VERSION ""

NS_ :

BS_:

BU_: TCM HCM IPMA_ADAS PSCM ABS_ESC TCCM TCM_DSL PCM_HEV PCM ECM_HEVDSL ECM_HEV ECM_Diesel ECM SIMA_DLCS BCMD_IPDB VDM CMR_DSMC SOBDMC_HPCM CHCM GWM _delete AWD_DLCM GENERIC TSTR

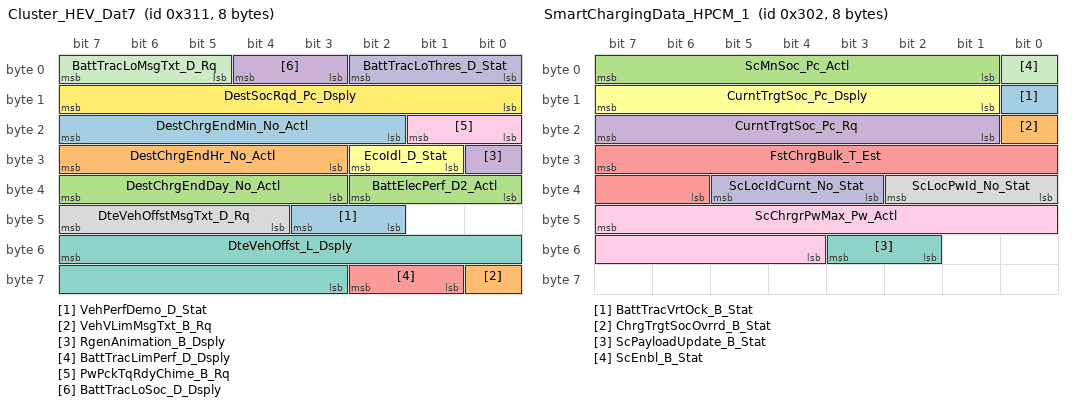
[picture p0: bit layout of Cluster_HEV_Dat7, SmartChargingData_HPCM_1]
BO_ 785 Cluster_HEV_Dat7: 8 SOBDMC_HPCM
 SG_ VehPerfDemo_D_Stat : 43|2@0+ (1,0) [0|3] "SED"  GWM
 SG_ VehVLimMsgTxt_B_Rq : 56|1@0+ (1,0) [0|1] "SED"  GWM
 SG_ BattElecPerf_D2_Actl : 34|3@0+ (1,0) [0|7] "SED"  GWM
 SG_ RgenAnimation_B_Dsply : 24|1@0+ (1,0) [0|1] "SED"  GWM
 SG_ BattTracLimPerf_D_Dsply : 58|2@0+ (1,0) [0|3] "SED"  GWM
 SG_ EcoIdl_D_Stat : 26|2@0+ (1,0) [0|3] "SED"  GWM
 SG_ DteVehOffst_L_Dsply : 55|13@0+ (0.1,-400) [-400|418.9] "kilometer"  GWM
 SG_ DteVehOffstMsgTxt_D_Rq : 47|4@0+ (1,0) [0|15] "SED"  GWM
 SG_ PwPckTqRdyChime_B_Rq : 17|2@0+ (1,0) [0|3] "SED"  GWM
 SG_ BattTracLoThres_D_Stat : 2|3@0+ (1,0) [0|7] "SED"  GWM
 SG_ BattTracLoMsgTxt_D_Rq : 7|3@0+ (1,0) [0|7] "SED"  GWM
 SG_ DestSocRqd_Pc_Dsply : 15|8@0+ (0.5,0) [0|127.5] "percent"  GWM
 SG_ DestChrgEndMin_No_Actl : 23|6@0+ (1,0) [0|63] "Minutes"  GWM
 SG_ DestChrgEndHr_No_Actl : 31|5@0+ (1,0) [0|31] "Hours"  GWM
 SG_ DestChrgEndDay_No_Actl : 39|5@0+ (1,0) [1|31] "days"  GWM
 SG_ BattTracLoSoc_D_Dsply : 4|2@0+ (1,0) [0|3] "SED"  GWM

BO_ 770 SmartChargingData_HPCM_1: 8 SOBDMC_HPCM
 SG_ BattTracVrtOck_B_Stat : 8|1@0+ (1,0) [0|1] "SED"  GWM
 SG_ ChrgTrgtSocOvrrd_B_Stat : 16|1@0+ (1,0) [0|1] "SED"  GWM
 SG_ ScMnSoc_Pc_Actl : 7|7@0+ (1,0) [0|127] "percent"  GWM
 SG_ CurntTrgtSoc_Pc_Rq : 23|7@0+ (1,0) [0|127] "percent"  GWM
 SG_ FstChrgBulk_T_Est : 31|10@0+ (1,0) [0|1023] "minute"  GWM
 SG_ CurntTrgtSoc_Pc_Dsply : 15|7@0+ (1,0) [0|127] "percent"  GWM
 SG_ ScPayloadUpdate_B_Stat : 51|2@0+ (1,0) [0|3] "SED"  GWM
 SG_ ScLocPwId_No_Stat : 34|3@0+ (1,0) [0|7] "unitless"  GWM
 SG_ ScChrgrPwMax_Pw_Actl : 47|12@0+ (50,0) [0|204700] "watts"  GWM
 SG_ ScLocIdCurnt_No_Stat : 37|3@0+ (1,0) [0|7] "unitless"  GWM
 SG_ ScEnbl_B_Stat : 0|1@0+ (1,0) [0|1] "SED"  GWM

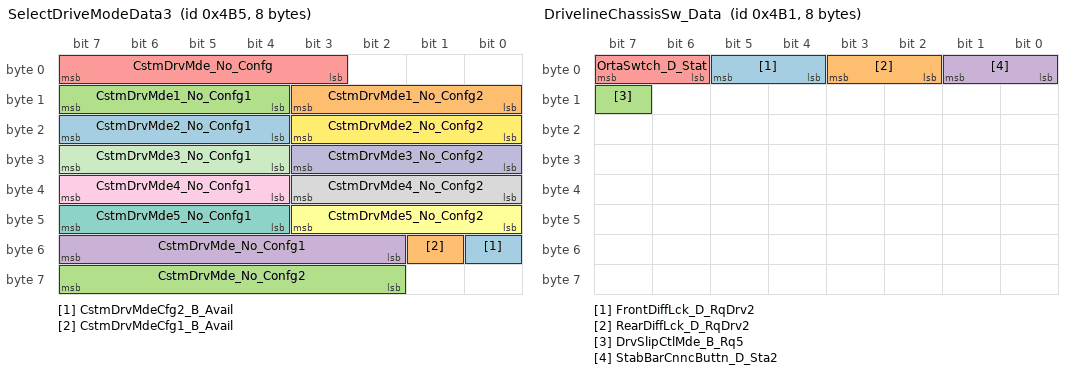
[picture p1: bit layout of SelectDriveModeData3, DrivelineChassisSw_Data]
BO_ 1205 SelectDriveModeData3: 8 ABS_ESC
 SG_ CstmDrvMdeCfg2_B_Avail : 48|1@0+ (1,0) [0|1] "SED"  GWM
 SG_ CstmDrvMdeCfg1_B_Avail : 49|1@0+ (1,0) [0|1] "SED"  GWM
 SG_ CstmDrvMde_No_Confg2 : 63|6@0+ (1,0) [0|63] "unitless"  GWM
 SG_ CstmDrvMde_No_Confg1 : 55|6@0+ (1,0) [0|63] "unitless"  GWM
 SG_ CstmDrvMde_No_Confg : 7|5@0+ (1,0) [0|31] "unitless"  GWM
 SG_ CstmDrvMde5_No_Confg2 : 43|4@0+ (1,0) [0|15] "unitless"  GWM
 SG_ CstmDrvMde5_No_Confg1 : 47|4@0+ (1,0) [0|15] "unitless"  GWM
 SG_ CstmDrvMde4_No_Confg2 : 35|4@0+ (1,0) [0|15] "unitless"  GWM
 SG_ CstmDrvMde4_No_Confg1 : 39|4@0+ (1,0) [0|15] "unitless"  GWM
 SG_ CstmDrvMde3_No_Confg2 : 27|4@0+ (1,0) [0|15] "unitless"  GWM
 SG_ CstmDrvMde3_No_Confg1 : 31|4@0+ (1,0) [0|15] "unitless"  GWM
 SG_ CstmDrvMde2_No_Confg2 : 19|4@0+ (1,0) [0|15] "unitless"  GWM
 SG_ CstmDrvMde2_No_Confg1 : 23|4@0+ (1,0) [0|15] "unitless"  GWM
 SG_ CstmDrvMde1_No_Confg2 : 11|4@0+ (1,0) [0|15] "unitless"  GWM
 SG_ CstmDrvMde1_No_Confg1 : 15|4@0+ (1,0) [0|15] "unitless"  GWM

BO_ 942 ParkAid_Data_3: 8 IPMA_ADAS
 SG_ ApaOffOptnSel_B_Avail : 51|1@0+ (1,0) [0|1] "SED"  GWM
 SG_ PrkBrkElRleas_B_RqApa : 50|1@0+ (1,0) [0|1] "SED"  ABS_ESC,GWM
 SG_ ApaDrvRq2MsgTxt_D_Rq : 55|4@0+ (1,0) [0|15] "SED"  GWM
 SG_ ApaDrvRq1MsgTxt_D_Rq : 42|3@0+ (1,0) [0|7] "SED"  GWM
 SG_ ApaSys_D2_Stat : 35|4@0+ (1,0) [0|15] "SED"  GWM
 SG_ ApaSlotTrgt_D_Stat : 39|4@0+ (1,0) [0|15] "SED"  GWM
 SG_ ApaSlotOption_B_Avail : 43|1@0+ (1,0) [0|1] "SED"  GWM
 SG_ ApaSlotAlrtSet_B_Stat : 44|1@0+ (1,0) [0|1] "SED"  GWM
 SG_ ApaSlotAlrt_B_Rq : 45|1@0+ (1,0) [0|1] "SED"  GWM
 SG_ ApaRmtFeatSel_B_Avail : 46|1@0+ (1,0) [0|1] "SED"  GWM
 SG_ ApaParkOutSel_B_Avail : 47|1@0+ (1,0) [0|1] "SED"  GWM
 SG_ ApaParkInSel_B_Avail : 24|1@0+ (1,0) [0|1] "SED"  GWM
 SG_ ApaMsgTxt_D2_Stat : 28|4@0+ (1,0) [0|15] "SED"  GWM
 SG_ ApaDynmcSlot_B_Stat : 29|1@0+ (1,0) [0|1] "SED"  GWM
 SG_ ApaDisplayMode_D_Stat : 31|2@0+ (1,0) [0|3] "SED"  GWM
 SG_ ApaControlMode_D_Stat : 16|1@0+ (1,0) [0|1] "SED"  GWM
 SG_ PrkAidAcsyRear_D_Stat : 18|2@0+ (1,0) [0|3] "SED"  GWM
 SG_ PrkAidAcsyFront_D_Stat : 20|2@0+ (1,0) [0|3] "SED"  GWM
 SG_ PrkAidRdiusRight_L_Dsply : 15|8@0+ (1,0) [0|255] "unitless"  GWM
 SG_ PrkAidRdiusLeft_L_Dsply : 7|8@0+ (1,0) [0|255] "unitless"  GWM
 SG_ PrkAidDrvDir_D_Stat : 23|3@0+ (1,0) [0|7] "SED"  GWM

BO_ 123 Battery_Traction_2_FD1: 8 BECM
 SG_ BattTrac_U2_Actl : 21|12@0+ (0.5,0) [0|2046.5] "volt"  ECM_Diesel,ECM_HEVDSL,SOBDMC_HPCM,ECM_HEV,PCM_HEV
 SG_ BattTrac_I2_Actl : 7|18@0+ (0.05,-6553.52) [-6553.52|6553.53] "ampere"  ECM_Diesel,ECM_HEVDSL,SOBDMC_HPCM,ECM_HEV,PCM_HEV

BO_ 2612052184 PARSEDPushFcGWM_ECGtoPSCM: 8 GWM
 SG_ PARSEDPushFcGWM_ECGtoPSCM : 7|29@0+ (1,0) [0|536870911] "unitless"  PSCM

BO_ 2612224187 PARSEDPushCMRtoGWM_ECG: 8 CMR_DSMC
 SG_ PARSEDPushCMRtoGWM_ECG : 7|29@0+ (1,0) [0|536870911] "unitless"  GWM

BO_ 1201 DrivelineChassisSw_Data: 8 SIMA_DLCS
 SG_ FrontDiffLck_D_RqDrv2 : 5|2@0+ (1,0) [0|3] "SED"  GWM
 SG_ RearDiffLck_D_RqDrv2 : 3|2@0+ (1,0) [0|3] "SED"  GWM
 SG_ DrvSlipCtlMde_B_Rq5 : 15|1@0+ (1,0) [0|1] "SED"  GWM
 SG_ StabBarCnncButtn_D_Sta2 : 1|2@0+ (1,0) [0|3] "SED"  GWM
 SG_ OrtaSwtch_D_Stat : 7|2@0+ (1,0) [0|3] "SED"  ABS_ESC

BO_ 1912 TesterPhysicalResSIMA_DLCS: 64 SIMA_DLCS
 SG_ TesterPhysicalResSIMA : 7|64@0+ (1,0) [0|1.84467E+019] "unitless"  TSTR

BO_ 1904 TesterPhysicalReqSIMA_DLCS: 64 TSTR
 SG_ TesterPhysicalReqSIMA : 7|64@0+ (1,0) [0|1.84467E+019] "unitless"  SIMA_DLCS

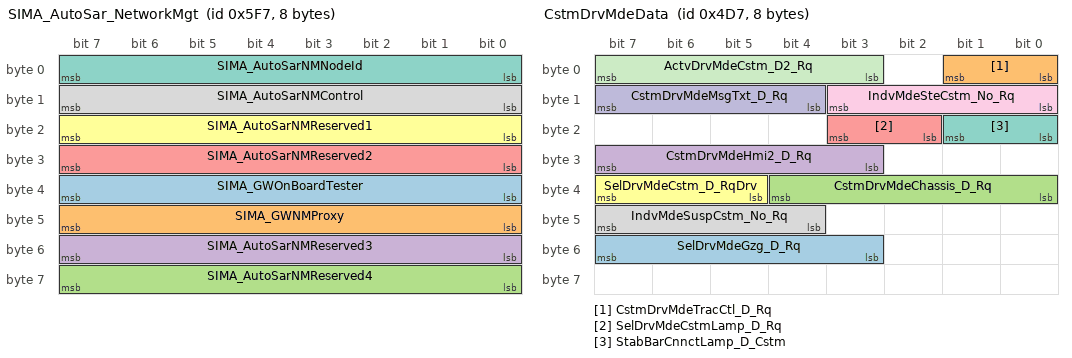
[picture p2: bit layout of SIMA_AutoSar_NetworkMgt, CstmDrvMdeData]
BO_ 1527 SIMA_AutoSar_NetworkMgt: 8 SIMA_DLCS
 SG_ SIMA_GWOnBoardTester : 39|8@0+ (1,0) [0|255] "unitless"  GENERIC
 SG_ SIMA_GWNMProxy : 47|8@0+ (1,0) [0|255] "unitless"  GENERIC
 SG_ SIMA_AutoSarNMReserved4 : 63|8@0+ (1,0) [0|255] "unitless"  GENERIC
 SG_ SIMA_AutoSarNMReserved3 : 55|8@0+ (1,0) [0|255] "unitless"  GENERIC
 SG_ SIMA_AutoSarNMReserved2 : 31|8@0+ (1,0) [0|255] "unitless"  GENERIC
 SG_ SIMA_AutoSarNMReserved1 : 23|8@0+ (1,0) [0|255] "unitless"  GENERIC
 SG_ SIMA_AutoSarNMNodeId : 7|8@0+ (1,0) [0|255] "unitless"  GENERIC
 SG_ SIMA_AutoSarNMControl : 15|8@0+ (1,0) [0|255] "unitless"  GENERIC

BO_ 1239 CstmDrvMdeData: 8 GWM
 SG_ SelDrvMdeGzg_D_Rq : 55|5@0+ (1,0) [0|31] "SED"  ABS_ESC
 SG_ CstmDrvMdeTracCtl_D_Rq : 1|2@0+ (1,0) [0|3] "SED"  ABS_ESC
 SG_ CstmDrvMdeChassis_D_Rq : 36|5@0+ (1,0) [0|31] "SED"  ABS_ESC
 SG_ CstmDrvMdeHmi2_D_Rq : 31|5@0+ (1,0) [0|31] "SED"  ABS_ESC
 SG_ SelDrvMdeCstmLamp_D_Rq : 19|2@0+ (1,0) [0|3] "SED"  GENERIC
 SG_ SelDrvMdeCstm_D_RqDrv : 39|3@0+ (1,0) [0|7] "SED"  ECM_Diesel,ECM_HEV,ECM_HEVDSL,PCM_HEV,ABS_ESC,AWD_DLCM,ECM,PCM,TCCM
 SG_ StabBarCnnctLamp_D_Cstm : 17|2@0+ (1,0) [0|3] "SED"  ABS_ESC
 SG_ IndvMdeSuspCstm_No_Rq : 47|4@0+ (1,0) [0|15] "unitless"  ABS_ESC
 SG_ IndvMdeSteCstm_No_Rq : 11|4@0+ (1,0) [0|15] "unitless"  ABS_ESC
 SG_ CstmDrvMdeMsgTxt_D_Rq : 15|4@0+ (1,0) [0|15] "SED"  GENERIC
 SG_ ActvDrvMdeCstm_D2_Rq : 7|5@0+ (1,0) [0|31] "SED"  ABS_ESC

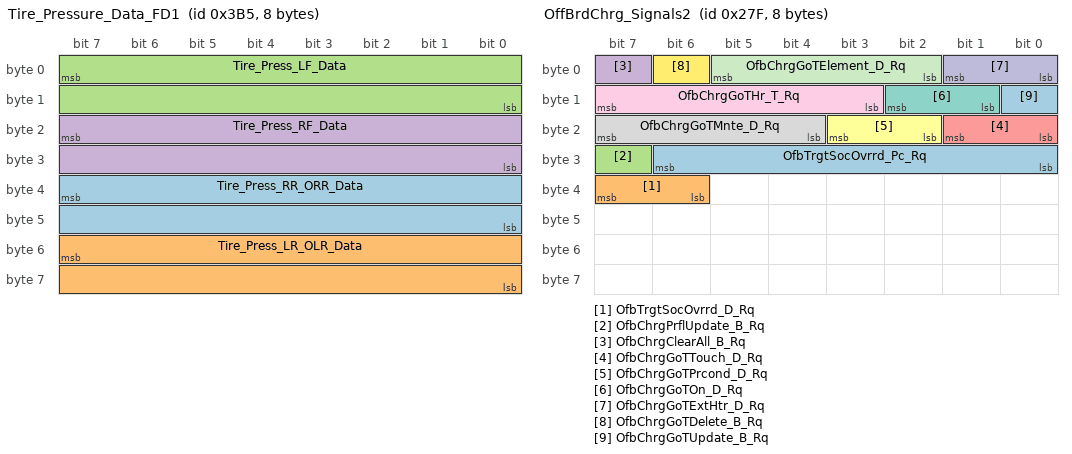
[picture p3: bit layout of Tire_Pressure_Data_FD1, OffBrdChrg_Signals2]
BO_ 949 Tire_Pressure_Data_FD1: 8 BCM
 SG_ Tire_Press_RR_ORR_Data : 39|16@0+ (1,0) [0|65533] "kilopascal"  VDM
 SG_ Tire_Press_LR_OLR_Data : 55|16@0+ (1,0) [0|65533] "kilopascal"  VDM
 SG_ Tire_Press_LF_Data : 7|16@0+ (1,0) [0|65533] "kilopascal"  VDM
 SG_ Tire_Press_RF_Data : 23|16@0+ (1,0) [0|65533] "kilopascal"  VDM

BO_ 2612118744 PARSEDPushFcGWMtoHCM: 8 GWM
 SG_ PARSEDPushFcGWM_ECGtoHCM : 7|29@0+ (1,0) [0|536870911] "unitless"  HCM

BO_ 2612074712 PARSEDPushFcGWMtoSODCMD: 8 GWM
 SG_ PARSEDPushFcGWMtoSODCMD : 7|29@0+ (1,0) [0|536870911] "unitless"  IPMA_ADAS

BO_ 2612024536 PARSEDPushFcGWM_ECGtoCCM: 8 GWM
 SG_ PARSEDPushFcGWM_ECGtoCCM : 7|29@0+ (1,0) [0|536870911] "unitless"  IPMA_ADAS

BO_ 2612036824 PARSEDPushFcGWM_ECGtoIPMA: 8 GWM
 SG_ PARSEDPushFcGWM_ECGtoIPMA : 7|29@0+ (1,0) [0|536870911] "unitless"  IPMA_ADAS

BO_ 2612103384 PARSEDPushFcGWMtoSODL: 8 GWM
 SG_ PARSEDPushFcGWM_ECGtoSODL : 7|29@0+ (1,0) [0|536870911] "unitless"  IPMA_ADAS

BO_ 639 OffBrdChrg_Signals2: 8 GWM
 SG_ OfbTrgtSocOvrrd_Pc_Rq : 30|7@0+ (1,0) [0|127] "percent"  SOBDMC_HPCM
 SG_ OfbTrgtSocOvrrd_D_Rq : 39|2@0+ (1,0) [0|3] "SED"  SOBDMC_HPCM
 SG_ OfbChrgPrflUpdate_B_Rq : 31|1@0+ (1,0) [0|1] "SED"  SOBDMC_HPCM
 SG_ OfbChrgClearAll_B_Rq : 7|1@0+ (1,0) [0|1] "SED"  SOBDMC_HPCM
 SG_ OfbChrgGoTTouch_D_Rq : 17|2@0+ (1,0) [0|3] "SED"  SOBDMC_HPCM
 SG_ OfbChrgGoTPrcond_D_Rq : 19|2@0+ (1,0) [0|3] "SED"  SOBDMC_HPCM
 SG_ OfbChrgGoTOn_D_Rq : 10|2@0+ (1,0) [0|3] "SED"  SOBDMC_HPCM
 SG_ OfbChrgGoTMnte_D_Rq : 23|4@0+ (1,0) [0|15] "minute"  SOBDMC_HPCM
 SG_ OfbChrgGoTHr_T_Rq : 15|5@0+ (1,0) [0|29] "hour"  SOBDMC_HPCM
 SG_ OfbChrgGoTExtHtr_D_Rq : 1|2@0+ (1,0) [0|3] "SED"  SOBDMC_HPCM
 SG_ OfbChrgGoTElement_D_Rq : 5|4@0+ (1,0) [0|15] "Unitless"  SOBDMC_HPCM
 SG_ OfbChrgGoTDelete_B_Rq : 6|1@0+ (1,0) [0|1] "SED"  SOBDMC_HPCM
 SG_ OfbChrgGoTUpdate_B_Rq : 8|1@0+ (1,0) [0|1] "SED"  SOBDMC_HPCM

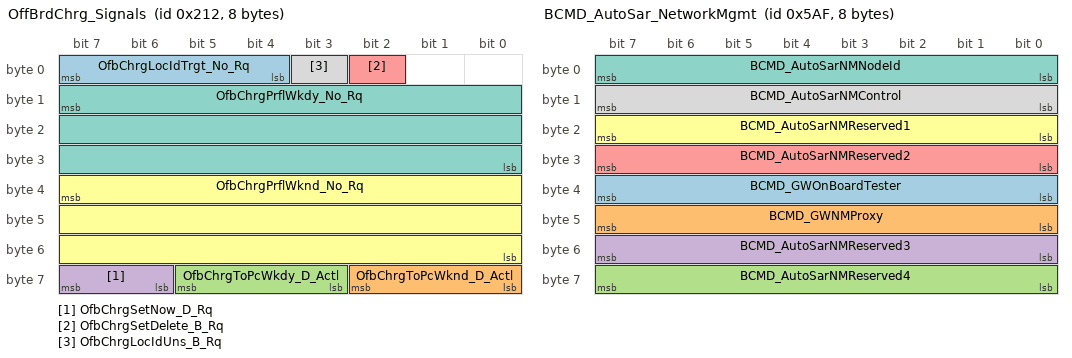
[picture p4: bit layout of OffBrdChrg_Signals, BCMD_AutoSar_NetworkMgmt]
BO_ 530 OffBrdChrg_Signals: 8 GWM
 SG_ OfbChrgLocIdTrgt_No_Rq : 7|4@0+ (1,0) [0|15] "Unitless"  SOBDMC_HPCM
 SG_ OfbChrgToPcWknd_D_Actl : 58|3@0+ (1,0) [0|7] "percent"  SOBDMC_HPCM
 SG_ OfbChrgToPcWkdy_D_Actl : 61|3@0+ (1,0) [0|7] "percent"  SOBDMC_HPCM
 SG_ OfbChrgSetNow_D_Rq : 63|2@0+ (1,0) [0|3] "SED"  SOBDMC_HPCM
 SG_ OfbChrgSetDelete_B_Rq : 2|1@0+ (1,0) [0|1] "SED"  SOBDMC_HPCM
 SG_ OfbChrgPrflWknd_No_Rq : 39|24@0+ (1,0) [0|16777215] "unitless"  SOBDMC_HPCM
 SG_ OfbChrgPrflWkdy_No_Rq : 15|24@0+ (1,0) [0|16777215] "unitless"  SOBDMC_HPCM
 SG_ OfbChrgLocIdUns_B_Rq : 3|1@0+ (1,0) [0|1] "SED"  SOBDMC_HPCM

BO_ 550 ECG_Data4_FD1: 8 GWM
 SG_ PtWakeupActv1_B_Rq : 7|1@0+ (1,0) [0|1] "SED"  SOBDMC_HPCM

BO_ 879 BCMC_Data_FD1: 8 GWM
 SG_ WndwRearHeat_I_Actl : 7|11@0+ (0.1,0) [0|204.6] "ampere"  ECM_Diesel,ECM_HEVDSL
 SG_ WndwRearHeat_D_Stat : 12|3@0+ (1,0) [0|7] "SED"  ECM_Diesel,ECM_HEVDSL

BO_ 1455 BCMD_AutoSar_NetworkMgmt: 8 BCMD_IPDB
 SG_ BCMD_GWOnBoardTester : 39|8@0+ (1,0) [0|255] "unitless"  GENERIC
 SG_ BCMD_GWNMProxy : 47|8@0+ (1,0) [0|255] "unitless"  GENERIC
 SG_ BCMD_AutoSarNMReserved4 : 63|8@0+ (1,0) [0|255] "unitless"  GENERIC
 SG_ BCMD_AutoSarNMReserved3 : 55|8@0+ (1,0) [0|255] "unitless"  GENERIC
 SG_ BCMD_AutoSarNMReserved2 : 31|8@0+ (1,0) [0|255] "unitless"  GENERIC
 SG_ BCMD_AutoSarNMReserved1 : 23|8@0+ (1,0) [0|255] "unitless"  GENERIC
 SG_ BCMD_AutoSarNMNodeId : 7|8@0+ (1,0) [0|255] "unitless"  GENERIC
 SG_ BCMD_AutoSarNMControl : 15|8@0+ (1,0) [0|255] "unitless"  GENERIC

BO_ 1775 TesterPhysicalResBCMD_IPDB: 64 BCMD_IPDB
 SG_ TesterPhysicalResBCMD_IPDB : 7|64@0+ (1,0) [0|1.84467E+019] "unitless"  TSTR

BO_ 1767 TesterPhysicalReqBCMD_IPDB: 64 TSTR
 SG_ TesterPhysicalReqBCMD_IPDB : 7|64@0+ (1,0) [0|1.84467E+019] "unitless"  BCMD_IPDB

BO_ 2612019416 PARSEDPushFcGWM_ECGtoPCM: 8 GWM
 SG_ PARSEDPushFcGWM_ECGtoPCM : 7|29@0+ (1,0) [0|536870911] "unitless"  SOBDMC_HPCM,ECM,ECM_Diesel,ECM_HEV,ECM_HEVDSL,PCM,PCM_HEV

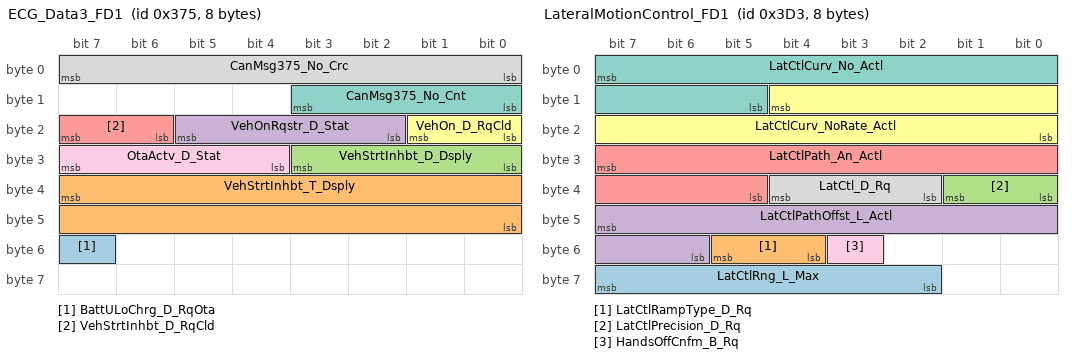
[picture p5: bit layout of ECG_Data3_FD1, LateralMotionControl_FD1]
BO_ 885 ECG_Data3_FD1: 8 GWM
 SG_ BattULoChrg_D_RqOta : 55|1@0+ (1,0) [0|1] "SED"  GENERIC
 SG_ VehStrtInhbt_T_Dsply : 39|16@0+ (1,0) [0|65535] "second"  GENERIC
 SG_ VehStrtInhbt_D_Dsply : 27|4@0+ (1,0) [0|15] "SED"  GENERIC
 SG_ VehOnRqstr_D_Stat : 21|4@0+ (1,0) [0|15] "SED"  GENERIC
 SG_ VehStrtInhbt_D_RqCld : 23|2@0+ (1,0) [0|3] "SED"  GENERIC
 SG_ VehOn_D_RqCld : 17|2@0+ (1,0) [0|3] "SED"  GENERIC
 SG_ CanMsg375_No_Cnt : 11|4@0+ (1,0) [0|15] "unitless"  GENERIC
 SG_ CanMsg375_No_Crc : 7|8@0+ (1,0) [0|255] "unitless"  GENERIC
 SG_ OtaActv_D_Stat : 31|4@0+ (1,0) [0|15] "SED"  AWD_DLCM,TCM,TCM_DSL,SOBDMC_HPCM

BO_ 2612104408 PARSEDPushFcGWMtoSODR: 8 GWM
 SG_ PARSEDPushFcGWM_ECGtoSODR : 7|29@0+ (1,0) [0|536870911] "unitless"  IPMA_ADAS

BO_ 2612020440 PARSEDPushFcGWMtoSOBDMCFD1: 8 GWM
 SG_ PARSEDPushFcGWMtoSOBDMC : 7|29@0+ (1,0) [0|536870911] "unitless"  SOBDMC_HPCM

BO_ 979 LateralMotionControl_FD1: 8 IPMA
 SG_ LatCtlRng_L_Max : 63|6@0+ (2,0) [0|126] "meter"  PSCM
 SG_ LatCtlRampType_D_Rq : 53|2@0+ (1,0) [0|3] "SED" Vector__XXX
 SG_ LatCtlPrecision_D_Rq : 33|2@0+ (1,0) [0|3] "SED" Vector__XXX
 SG_ LatCtlPathOffst_L_Actl : 47|10@0+ (0.01,-5.12) [-5.12|5.11] "meter" Vector__XXX
 SG_ LatCtlPath_An_Actl : 31|11@0+ (0.0005,-0.5) [-0.5|0.5235] "radians" Vector__XXX
 SG_ LatCtlCurv_NoRate_Actl : 12|13@0+ (2.5E-007,-0.001024) [-0.001024|0.00102375] "1/meter"  PSCM
 SG_ LatCtlCurv_No_Actl : 7|11@0+ (2E-005,-0.02) [-0.02|0.02094] "1/meter" Vector__XXX
 SG_ LatCtl_D_Rq : 36|3@0+ (1,0) [0|7] "SED"  PSCM
 SG_ HandsOffCnfm_B_Rq : 51|1@0+ (1,0) [0|1] "SED" Vector__XXX

BO_ 739 HMI_Send_Signals_7_FD1: 8 APIM
 SG_ BptMde_D_RqMnu : 7|3@0+ (1,0) [0|7] "SED"  SOBDMC_HPCM
 SG_ SpeedChngChime_D_Rq : 49|2@0+ (1,0) [0|3] "SED"  IPMA_ADAS
 SG_ BptMnSoc_L_RqMnu : 39|13@0+ (0.1,0) [0|818.9] "kilometer"  SOBDMC_HPCM
 SG_ BptStrtStop_D_RqMnu : 4|2@0+ (1,0) [0|3] "SED"  SOBDMC_HPCM
 SG_ OnbTrgtSocOvrrd_Pc_Rq : 63|7@0+ (1,0) [0|127] "percent"  SOBDMC_HPCM
 SG_ OnbTrgtSocOvrrd_D_Rq : 14|2@0+ (1,0) [0|3] "SED"  SOBDMC_HPCM
 SG_ BabySeatInUse_D_Stat : 31|2@0+ (1,0) [0|3] "SED"  GENERIC
 SG_ VehHornOccAlrt_D_Stat : 27|2@0+ (1,0) [0|3] "SED"  GENERIC
 SG_ SeatOccChime_B_RqCancl : 16|1@0+ (1,0) [0|1] "SED"  GENERIC
 SG_ SeatOccRear_D_Stat : 29|2@0+ (1,0) [0|3] "SED"  GENERIC
 SG_ EngExhMdeHrStrt_D_Rq : 12|5@0+ (1,0) [0|31] "SED"  PCM
 SG_ EngExhMdeHrEnd_D_Rq : 23|5@0+ (1,0) [0|31] "SED"  PCM
 SG_ EngExhMdeHrEnbl_D_Rq : 18|2@0+ (1,0) [0|3] "SED"  PCM
 SG_ VgfSet_D_Stat : 25|2@0+ (1,0) [0|3] "SED"  GENERIC
 SG_ BptDly_T_RqMnu : 55|6@0+ (0.5,0) [0|30.5] "minute"  SOBDMC_HPCM
 SG_ Partial_Amp_Shutdown : 15|1@0+ (1,0) [0|1] "SED"  GENERIC
 SG_ HMI_HMIMode_St : 2|3@0+ (1,0) [0|7] "SED"  ECM,ECM_Diesel,ECM_HEV,ECM_HEVDSL,PCM_HEV,PCM

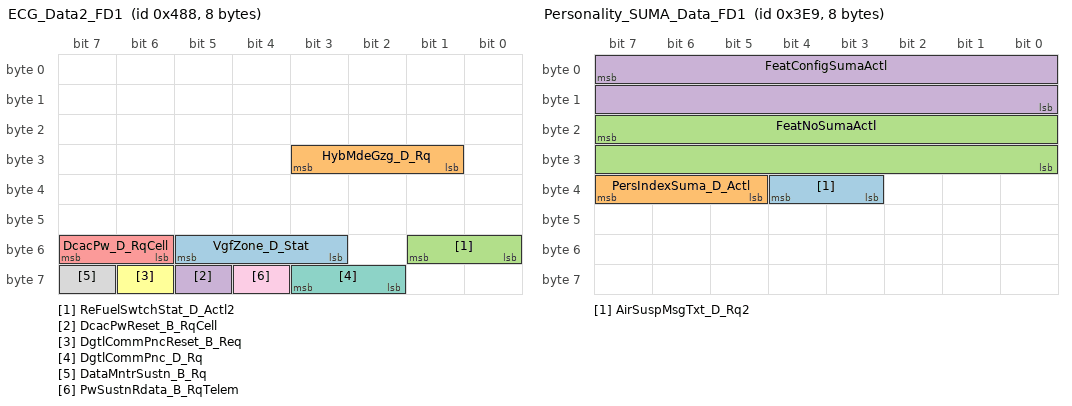
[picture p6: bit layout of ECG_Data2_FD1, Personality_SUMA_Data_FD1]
BO_ 1160 ECG_Data2_FD1: 8 GWM
 SG_ VgfZone_D_Stat : 53|3@0+ (1,0) [0|7] "SED"  ECM,ECM_HEV,PCM,PCM_HEV
 SG_ HybMdeGzg_D_Rq : 27|3@0+ (1,0) [0|7] "SED"  PCM_HEV,SOBDMC_HPCM
 SG_ ReFuelSwtchStat_D_Actl2 : 49|2@0+ (1,0) [0|3] "SED"  ECM_HEV,PCM_HEV
 SG_ DcacPwReset_B_RqCell : 61|1@0+ (1,0) [0|1] "SED"  PCM
 SG_ DcacPw_D_RqCell : 55|2@0+ (1,0) [0|3] "SED"  PCM
 SG_ DgtlCommPncReset_B_Req : 62|1@0+ (1,0) [0|1] "SED"  GENERIC
 SG_ DgtlCommPnc_D_Rq : 59|2@0+ (1,0) [0|3] "SED"  GENERIC
 SG_ DataMntrSustn_B_Rq : 63|1@0+ (1,0) [0|1] "SED"  ECM_HEV,PCM_HEV
 SG_ PwSustnRdata_B_RqTelem : 60|1@0+ (1,0) [0|1] "SED"  SOBDMC_HPCM,ECM_HEV,PCM_HEV

BO_ 1825 TesterPhysicalReqVDM_FD1: 64 TSTR
 SG_ TesterPhysicalReqVDM : 7|64@0+ (1,0) [0|1.84467E+019] "unitless"  VDM

BO_ 1001 Personality_SUMA_Data_FD1: 8 SUMA_RLM
 SG_ AirSuspMsgTxt_D_Rq2 : 36|2@0+ (1,0) [0|3] "SED"  VDM
 SG_ PersIndexSuma_D_Actl : 39|3@0+ (1,0) [0|7] "SED"  GENERIC
 SG_ FeatNoSumaActl : 23|16@0+ (1,0) [0|65535] "Number"  GENERIC
 SG_ FeatConfigSumaActl : 7|16@0+ (1,0) [0|65535] "Undefined"  GENERIC

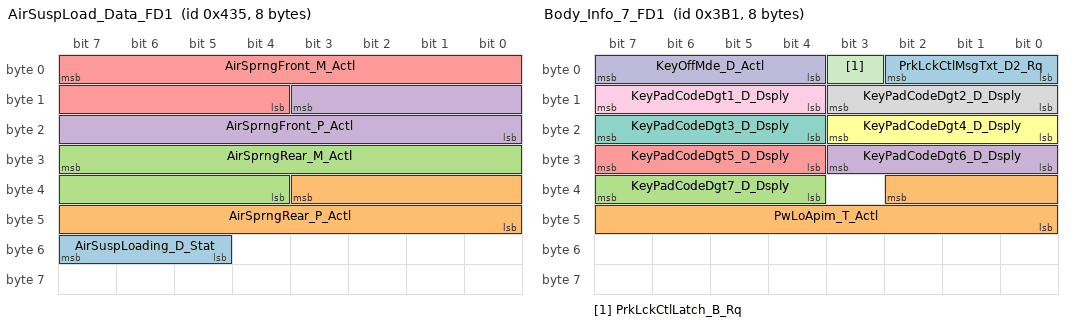
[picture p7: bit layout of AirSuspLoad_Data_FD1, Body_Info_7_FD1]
BO_ 1077 AirSuspLoad_Data_FD1: 8 SUMA_RLM
 SG_ AirSuspLoading_D_Stat : 55|3@0+ (1,0) [0|7] "SED"  VDM
 SG_ AirSprngRear_P_Actl : 35|12@0+ (0.01,-5.92) [-5.92|35.02] "bar"  VDM
 SG_ AirSprngRear_M_Actl : 31|12@0+ (1,0) [0|4094] "kilogram"  VDM
 SG_ AirSprngFront_P_Actl : 11|12@0+ (0.01,-5.92) [-5.92|35.02] "bar"  VDM
 SG_ AirSprngFront_M_Actl : 7|12@0+ (1,0) [0|4094] "kilogram"  VDM

BO_ 945 Body_Info_7_FD1: 8 BCM
 SG_ PrkLckCtlMsgTxt_D2_Rq : 2|3@0+ (1,0) [0|7] "SED"  GENERIC
 SG_ PwLoApim_T_Actl : 34|11@0+ (1,0) [0|2047] "minute"  GENERIC
 SG_ KeyPadCodeDgt7_D_Dsply : 39|4@0+ (1,0) [0|15] "SED"  GENERIC
 SG_ KeyPadCodeDgt6_D_Dsply : 27|4@0+ (1,0) [0|15] "SED"  GENERIC
 SG_ KeyPadCodeDgt5_D_Dsply : 31|4@0+ (1,0) [0|15] "SED"  GENERIC
 SG_ KeyPadCodeDgt4_D_Dsply : 19|4@0+ (1,0) [0|15] "SED"  GENERIC
 SG_ KeyPadCodeDgt3_D_Dsply : 23|4@0+ (1,0) [0|15] "SED"  GENERIC
 SG_ KeyPadCodeDgt2_D_Dsply : 11|4@0+ (1,0) [0|15] "SED"  GENERIC
 SG_ KeyPadCodeDgt1_D_Dsply : 15|4@0+ (1,0) [0|15] "SED"  GENERIC
 SG_ KeyOffMde_D_Actl : 7|4@0+ (1,0) [0|15] "SED"  IPMA_ADAS,VDM
 SG_ PrkLckCtlLatch_B_Rq : 3|1@0+ (1,0) [0|1] "SED"  GENERIC

BO_ 2612073688 PARSEDPushFcGWMtoSODCMC: 8 GWM
 SG_ PARSEDPushFcGWMtoSODCMC : 7|29@0+ (1,0) [0|536870911] "unitless"  IPMA_ADAS

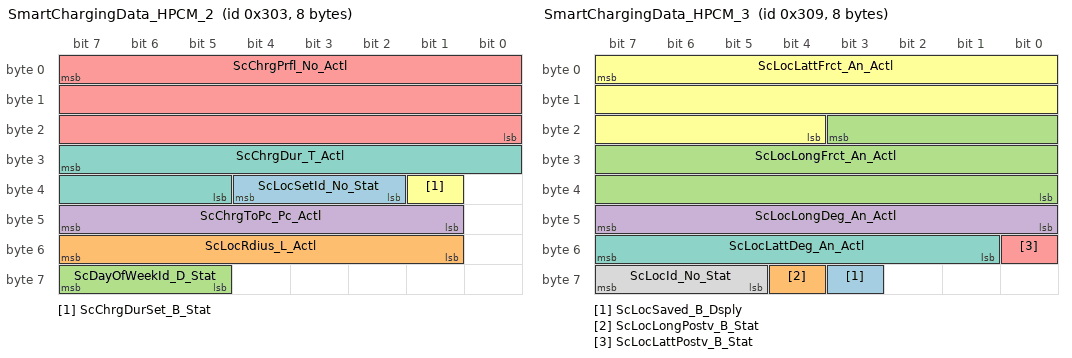
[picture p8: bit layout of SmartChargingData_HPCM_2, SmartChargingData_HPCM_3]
BO_ 771 SmartChargingData_HPCM_2: 8 SOBDMC_HPCM
 SG_ ScLocSetId_No_Stat : 36|3@0+ (1,0) [0|7] "unitless"  GWM
 SG_ ScLocRdius_L_Actl : 55|7@0+ (100,0) [0|12700] "meter"  GWM
 SG_ ScDayOfWeekId_D_Stat : 63|3@0+ (1,0) [0|7] "SED"  GWM
 SG_ ScChrgToPc_Pc_Actl : 47|7@0+ (1,0) [0|127] "percent"  GWM
 SG_ ScChrgPrfl_No_Actl : 7|24@0+ (1,0) [0|16777215] "unitless"  GWM
 SG_ ScChrgDurSet_B_Stat : 33|1@0+ (1,0) [0|1] "SED"  GWM
 SG_ ScChrgDur_T_Actl : 31|11@0+ (1,0) [0|2047] "minute"  GWM

BO_ 777 SmartChargingData_HPCM_3: 8 SOBDMC_HPCM
 SG_ ScLocSaved_B_Dsply : 59|1@0+ (1,0) [0|1] "SED"  GWM
 SG_ ScLocLongPostv_B_Stat : 60|1@0+ (1,0) [0|1] "SED"  GWM
 SG_ ScLocLongFrct_An_Actl : 19|20@0+ (1E-006,0) [0|1.048575] "degrees"  GWM
 SG_ ScLocLongDeg_An_Actl : 47|8@0+ (1,0) [0|255] "degrees"  GWM
 SG_ ScLocLattPostv_B_Stat : 48|1@0+ (1,0) [0|1] "SED"  GWM
 SG_ ScLocLattFrct_An_Actl : 7|20@0+ (1E-006,0) [0|1.048575] "degrees"  GWM
 SG_ ScLocLattDeg_An_Actl : 55|7@0+ (1,0) [0|127] "degrees"  GWM
 SG_ ScLocId_No_Stat : 63|3@0+ (1,0) [0|7] "unitless"  GWM

BO_ 1043 ABS_BrkData: 8 ABS_ESC
 SG_ PrkBrkPerfMsgTxt_D_Rq : 63|5@0+ (1,0) [0|31] "SED"  GWM
 SG_ PrkBrkPerfMde_D_Stat : 34|2@0+ (1,0) [0|3] "SED"  GWM
 SG_ WhlSpareMsgTxt_D_Rq : 41|2@0+ (1,0) [0|3] "SED"  GWM
 SG_ WhlSpareDetct_D_Dsply : 50|3@0+ (1,0) [0|7] "SED"  GWM
 SG_ PrkBrkPerfActv_B_Stat : 32|1@0+ (1,0) [0|1] "SED"  GWM,PCM,TCM
 SG_ SelDrvMdeHmi02_D_Rq : 47|5@0+ (1,0) [0|31] "SED"  GWM
 SG_ SelDrvMdeHmi04_D_Rq : 55|5@0+ (1,0) [0|31] "SED"  GWM
 SG_ IndvMdeSusp_No_Stat : 27|4@0+ (1,0) [0|15] "unitless"  GWM
 SG_ IndvMdeSte_No_Stat : 31|4@0+ (1,0) [0|15] "unitless"  GWM
 SG_ IndvMdeSel_No_Rq : 19|4@0+ (1,0) [0|15] "unitless"  GWM
 SG_ IndvMdeSel_D_Stat : 9|2@0+ (1,0) [0|3] "SED"  GWM
 SG_ IndvMdeMsgTxt_D_Rq : 23|4@0+ (1,0) [0|15] "SED"  GWM
 SG_ IndvMde5_B_Avail : 35|1@0+ (1,0) [0|1] "SED"  GWM
 SG_ IndvMde4_B_Avail : 36|1@0+ (1,0) [0|1] "SED"  GWM
 SG_ IndvMde3_B_Avail : 37|1@0+ (1,0) [0|1] "SED"  GWM
 SG_ IndvMde2_B_Avail : 38|1@0+ (1,0) [0|1] "SED"  GWM
 SG_ IndvMde1_B_Avail : 39|1@0+ (1,0) [0|1] "SED"  GWM
 SG_ TrailOnePdlMde_D_Ind : 15|3@0+ (1,0) [0|7] "SED"  GWM
 SG_ TrailOnePdlMsgTxt_D_Rq : 12|3@0+ (1,0) [0|7] "SED"  GWM
 SG_ OrtaSwtchLamp_B_Rq : 0|1@0+ (1,0) [0|1] "SED"  SIMA_DLCS,GWM
 SG_ OrtaMsgTxt_D_Rq : 4|4@0+ (1,0) [0|15] "SED"  GWM
 SG_ OrtaMde_D_Ind : 7|3@0+ (1,0) [0|7] "SED"  GWM,PCM

BO_ 1833 TesterPhysicalResVDM: 64 VDM
 SG_ TesterPhysicalResVDM : 7|64@0+ (1,0) [0|1.84467E+019] "unitless"  TSTR

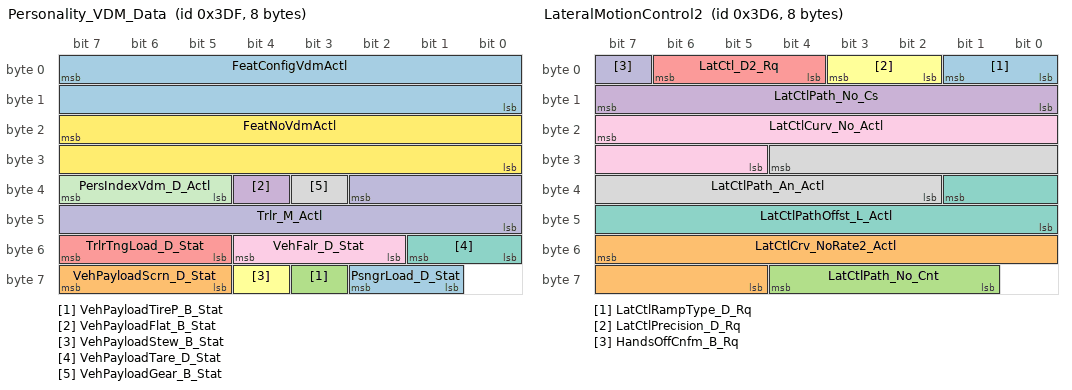
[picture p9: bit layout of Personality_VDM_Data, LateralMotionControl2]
BO_ 991 Personality_VDM_Data: 8 VDM
 SG_ PsngrLoad_D_Stat : 58|2@0+ (1,0) [0|3] "SED"  GWM
 SG_ VehPayloadScrn_D_Stat : 63|3@0+ (1,0) [0|7] "SED"  GWM
 SG_ VehPayloadTireP_B_Stat : 59|1@0+ (1,0) [0|1] "SED"  GWM
 SG_ VehPayloadFlat_B_Stat : 36|1@0+ (1,0) [0|1] "SED"  GWM
 SG_ TrlrTngLoad_D_Stat : 55|3@0+ (1,0) [0|7] "SED"  GWM
 SG_ VehPayloadStew_B_Stat : 60|1@0+ (1,0) [0|1] "SED"  GWM
 SG_ VehPayloadTare_D_Stat : 49|2@0+ (1,0) [0|3] "SED"  GWM
 SG_ VehPayloadGear_B_Stat : 35|1@0+ (1,0) [0|1] "SED"  GWM
 SG_ VehFalr_D_Stat : 52|3@0+ (1,0) [0|7] "SED"  GWM
 SG_ Trlr_M_Actl : 34|11@0+ (10,0) [0|20450] "kilogram"  GWM
 SG_ PersIndexVdm_D_Actl : 39|3@0+ (1,0) [0|7] "SED"  GWM
 SG_ FeatNoVdmActl : 23|16@0+ (1,0) [0|65535] "Number"  GWM
 SG_ FeatConfigVdmActl : 7|16@0+ (1,0) [0|65535] "Undefined"  GWM

BO_ 395 HeadUpDisplayReq_FD1: 8 IPC
 SG_ SelDrvMdeCnfm_D_Stat : 35|2@0+ (1,0) [0|3] "SED"  AWD_DLCM,ABS_ESC
 SG_ HudShifPoint_N_Rq : 29|6@0+ (100,2000) [2000|8300] "rpm"  GENERIC
 SG_ HudMde_D_Rq : 38|3@0+ (1,0) [0|7] "SED"  GENERIC
 SG_ HudLedMde_D_Rq : 31|2@0+ (1,0) [0|3] "SED"  GENERIC
 SG_ HudLedIntns_Pc_Rq : 22|7@0+ (1,0) [0|127] "percent"  GENERIC
 SG_ HudLed9On_B_Rq : 15|1@0+ (1,0) [0|1] "SED"  GENERIC
 SG_ HudLed8On_B_Rq : 0|1@0+ (1,0) [0|1] "SED"  GENERIC
 SG_ HudLed7On_B_Rq : 1|1@0+ (1,0) [0|1] "SED"  GENERIC
 SG_ HudLed6On_B_Rq : 2|1@0+ (1,0) [0|1] "SED"  GENERIC
 SG_ HudLed5On_B_Rq : 3|1@0+ (1,0) [0|1] "SED"  GENERIC
 SG_ HudLed4On_B_Rq : 4|1@0+ (1,0) [0|1] "SED"  GENERIC
 SG_ HudLed3On_B_Rq : 5|1@0+ (1,0) [0|1] "SED"  GENERIC
 SG_ HudLed2On_B_Rq : 6|1@0+ (1,0) [0|1] "SED"  GENERIC
 SG_ HudLed1On_B_Rq : 7|1@0+ (1,0) [0|1] "SED"  GENERIC
 SG_ HudLed18On_B_Rq : 39|1@0+ (1,0) [0|1] "SED"  GENERIC
 SG_ HudLed17On_B_Rq : 23|1@0+ (1,0) [0|1] "SED"  GENERIC
 SG_ HudLed16On_B_Rq : 8|1@0+ (1,0) [0|1] "SED"  GENERIC
 SG_ HudLed15On_B_Rq : 9|1@0+ (1,0) [0|1] "SED"  GENERIC
 SG_ HudLed14On_B_Rq : 10|1@0+ (1,0) [0|1] "SED"  GENERIC
 SG_ HudLed13On_B_Rq : 11|1@0+ (1,0) [0|1] "SED"  GENERIC
 SG_ HudLed12On_B_Rq : 12|1@0+ (1,0) [0|1] "SED"  GENERIC
 SG_ HudLed11On_B_Rq : 13|1@0+ (1,0) [0|1] "SED"  GENERIC
 SG_ HudLed10On_B_Rq : 14|1@0+ (1,0) [0|1] "SED"  GENERIC

BO_ 542 LocationServices_3_FD1: 8 TCU_FB5
 SG_ LocationServices_3 : 7|64@0+ (1,0) [0|1.84467440737096E+019] "unitless"  IPMA_ADAS,ABS_ESC,SOBDMC_HPCM

BO_ 1689 AWD_Rapid_Data_Response_2: 8 AWD_DLCM
 SG_ UUDTAWDResponse2 : 7|64@0+ (1,0) [0|1.84467440737096E+019] "unitless"  TSTR

BO_ 515 PowertrainData_12: 8 SOBDMC_HPCM
 SG_ PtIgnSwtch_D_Stat : 7|2@0+ (1,0) [0|3] "SED"  GWM

BO_ 982 LateralMotionControl2: 8 IPMA_ADAS
 SG_ LatCtlRampType_D_Rq : 1|2@0+ (1,0) [0|3] "SED"  PSCM
 SG_ LatCtlCrv_NoRate2_Actl : 55|11@0+ (1E-006,-0.001024) [-0.001024|0.001023] "meter^2"  PSCM
 SG_ LatCtlPath_No_Cnt : 60|4@0+ (1,0) [0|15] "Unitless"  PSCM
 SG_ LatCtlPath_No_Cs : 15|8@0+ (1,0) [0|255] "Unitless"  PSCM
 SG_ LatCtl_D2_Rq : 6|3@0+ (1,0) [0|7] "SED"  PSCM
 SG_ LatCtlPrecision_D_Rq : 3|2@0+ (1,0) [0|3] "SED"  PSCM
 SG_ LatCtlPathOffst_L_Actl : 33|10@0+ (0.01,-5.12) [-5.12|5.11] "meter"  PSCM
 SG_ LatCtlPath_An_Actl : 28|11@0+ (0.0005,-0.5) [-0.5|0.5235] "radians"  PSCM
 SG_ LatCtlCurv_No_Actl : 23|11@0+ (2E-005,-0.02) [-0.02|0.02094] "1/meter"  PSCM
 SG_ HandsOffCnfm_B_Rq : 7|1@0+ (1,0) [0|1] "SED"  PSCM

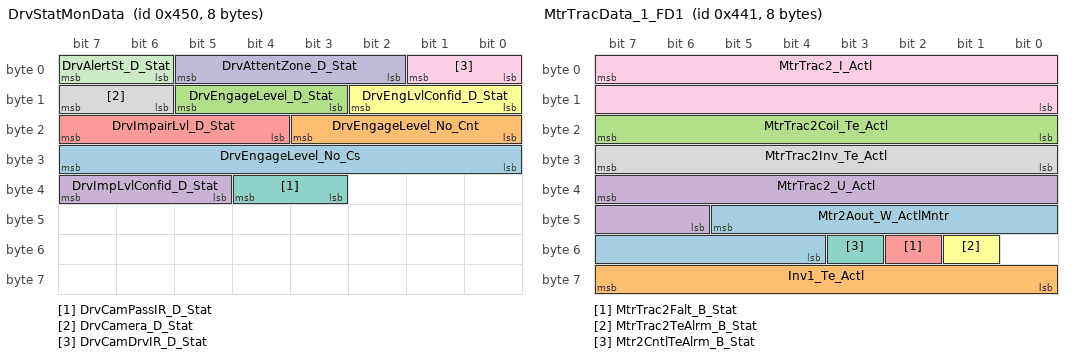
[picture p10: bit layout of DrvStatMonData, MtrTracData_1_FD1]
BO_ 1104 DrvStatMonData: 8 CMR_DSMC
 SG_ DrvEngageLevel_No_Cs : 31|8@0+ (1,0) [0|255] "Unitless"  IPMA_ADAS
 SG_ DrvEngageLevel_No_Cnt : 19|4@0+ (1,0) [0|15] "Unitless"  IPMA_ADAS
 SG_ DrvEngageLevel_D_Stat : 13|3@0+ (1,0) [0|7] "SED"  IPMA_ADAS
 SG_ DrvImpLvlConfid_D_Stat : 39|3@0+ (1,0) [0|7] "SED"  IPMA_ADAS
 SG_ DrvImpairLvl_D_Stat : 23|4@0+ (1,0) [0|15] "SED"  IPMA_ADAS
 SG_ DrvEngLvlConfid_D_Stat : 10|3@0+ (1,0) [0|7] "SED"  IPMA_ADAS
 SG_ DrvCamPassIR_D_Stat : 36|2@0+ (1,0) [0|3] "SED"  IPMA_ADAS
 SG_ DrvCamera_D_Stat : 15|2@0+ (1,0) [0|3] "SED"  IPMA_ADAS
 SG_ DrvCamDrvIR_D_Stat : 1|2@0+ (1,0) [0|3] "SED"  IPMA_ADAS
 SG_ DrvAttentZone_D_Stat : 5|4@0+ (1,0) [0|15] "SED"  IPMA_ADAS
 SG_ DrvAlertSt_D_Stat : 7|2@0+ (1,0) [0|3] "SED"  IPMA_ADAS

BO_ 829 Low_Voltage_Power_Dat2_FD1: 8 DCDC_HEV
 SG_ PwSrcULoMde2_D_Actl : 12|2@0+ (1,0) [0|3] "SED"  SOBDMC_HPCM,ECM_HEV,ECM_HEVDSL,PCM_HEV
 SG_ DcdcUHi3_I_Actl : 7|11@0+ (0.1,0) [0|204.5] "ampere"  ECM_HEV,ECM_HEVDSL,PCM_HEV,SOBDMC_HPCM

BO_ 2611070168 PARSEDPhysGWM_ECGtoHCM: 64 GWM
 SG_ PARSEDPhysGWM_ECGtoHCM : 7|29@0+ (1,0) [0|536870911] "unitless"  HCM,GENERIC

BO_ 2611175537 PARSEDPhysHCMtoGWM_ECG: 64 HCM
 SG_ PARSEDPhysHCMtoGWM_ECG : 7|29@0+ (1,0) [0|536870911] "unitless"  GWM

BO_ 2612224113 PARSEDPushHCMtoGWM_ECG: 8 HCM
 SG_ PARSEDPushHCMtoGWM_ECG : 7|29@0+ (1,0) [0|536870911] "unitless"  GWM

BO_ 2610021592 OTAPhysGWM_ECGtoHCM: 64 GWM
 SG_ OTAPhysGWM_ECGtoHCM : 7|29@0+ (1,0) [0|536870911] "unitless"  HCM,GENERIC

BO_ 2610126961 OTAPhysHCMtoGWM_ECG: 64 HCM
 SG_ OTAPhysHCMtoGWM_ECG : 7|29@0+ (1,0) [0|536870911] "unitless"  GWM

BO_ 2610975960 PARSEDPhysGWM_ECGtoCCM: 64 GWM
 SG_ PARSEDPhysGWM_ECGtoCCM : 7|29@0+ (1,0) [0|536870911] "unitless"  IPMA_ADAS

BO_ 2611175445 PARSEDPhysCCMtoGWM_ECG: 64 IPMA_ADAS
 SG_ PARSEDPhysCCMtoGWM_ECG : 7|29@0+ (1,0) [0|536870911] "unitless"  GWM

BO_ 2612224021 PARSEDPushCCMtoGWM_ECG: 8 IPMA_ADAS
 SG_ PARSEDPushCCMtoGWM_ECG : 7|29@0+ (1,0) [0|536870911] "unitless"  GWM

BO_ 2611025112 PARSEDPhysGWM_ECGtoSODCMC: 64 GWM
 SG_ PARSEDPhysGWM_ECGtoSODCMC : 7|29@0+ (1,0) [0|536870911] "unitless"  IPMA_ADAS

BO_ 2611175493 PARSEDPhysSODCMCtoGWM_ECG: 64 IPMA_ADAS
 SG_ PARSEDPhysSODCMCtoGWM_ECG : 7|29@0+ (1,0) [0|536870911] "unitless"  GWM

BO_ 2612224069 PARSEDPushSODCMCtoGWM: 8 IPMA_ADAS
 SG_ PARSEDPushSODCMCtoGWM : 7|29@0+ (1,0) [0|536870911] "unitless"  GWM

BO_ 1787 TesterPhysicalResSODCMD: 64 IPMA_ADAS
 SG_ TesterPhysicalResSODCMD : 7|64@0+ (1,0) [0|1.84467E+019] "unitless"  TSTR

BO_ 1779 TesterPhysicalReqSODCMD: 64 TSTR
 SG_ TesterPhysicalReqSODCMD : 7|64@0+ (1,0) [0|1.84467E+019] "unitless"  IPMA_ADAS

BO_ 1786 TesterPhysicalResSODCMC: 64 IPMA_ADAS
 SG_ TesterPhysicalResSODCMC : 7|64@0+ (1,0) [0|1.84467E+019] "unitless"  TSTR

BO_ 1089 MtrTracData_1_FD1: 8 SOBDMC_HPCM
 SG_ Mtr2Aout_W_ActlMntr : 45|10@0+ (6.28,-3209) [-3209|3209.16] "radians/sec"  GWM
 SG_ Inv1_Te_Actl : 63|8@0+ (1,-40) [-40|213] "degC"  GWM
 SG_ MtrTrac2Coil_Te_Actl : 23|8@0+ (1,-40) [-40|213] "degC"  GWM
 SG_ MtrTrac2_U_Actl : 39|10@0+ (1,0) [0|1023] "volt"  GWM
 SG_ MtrTrac2Falt_B_Stat : 50|1@0+ (1,0) [0|1] "SED"  GWM
 SG_ MtrTrac2TeAlrm_B_Stat : 49|1@0+ (1,0) [0|1] "SED"  GWM
 SG_ Mtr2CntlTeAlrm_B_Stat : 51|1@0+ (1,0) [0|1] "SED"  GWM
 SG_ MtrTrac2Inv_Te_Actl : 31|8@0+ (1,-40) [-40|213] "degC"  GWM
 SG_ MtrTrac2_I_Actl : 7|16@0+ (0.1,-1000) [-1000|5553.4] "ampere"  GWM

BO_ 1778 TesterPhysicalReqSODCMC: 64 TSTR
 SG_ TesterPhysicalReqSODCMC : 7|64@0+ (1,0) [0|1.84467E+019] "unitless"  IPMA_ADAS

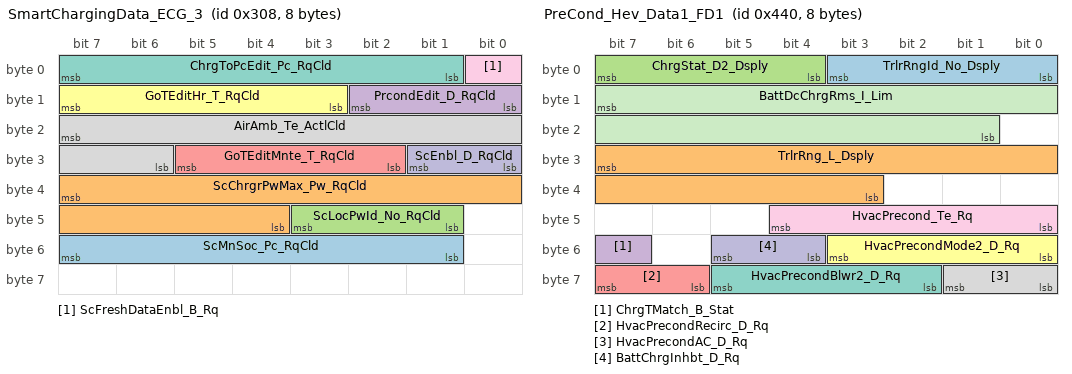
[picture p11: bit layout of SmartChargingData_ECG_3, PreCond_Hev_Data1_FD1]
BO_ 776 SmartChargingData_ECG_3: 8 GWM
 SG_ ScMnSoc_Pc_RqCld : 55|7@0+ (1,0) [0|127] "percent"  SOBDMC_HPCM
 SG_ ScChrgrPwMax_Pw_RqCld : 39|12@0+ (50,0) [0|204700] "watts"  SOBDMC_HPCM
 SG_ ScLocPwId_No_RqCld : 43|3@0+ (1,0) [0|7] "unitless"  SOBDMC_HPCM
 SG_ PrcondEdit_D_RqCld : 10|3@0+ (1,0) [0|7] "SED"  SOBDMC_HPCM
 SG_ GoTEditMnte_T_RqCld : 29|4@0+ (1,0) [0|15] "SED"  SOBDMC_HPCM
 SG_ GoTEditHr_T_RqCld : 15|5@0+ (1,0) [0|29] "SED"  SOBDMC_HPCM
 SG_ ChrgToPcEdit_Pc_RqCld : 7|7@0+ (1,0) [0|125] "percent"  SOBDMC_HPCM
 SG_ AirAmb_Te_ActlCld : 23|10@0+ (0.25,-128) [-128|127.75] "degC"  SOBDMC_HPCM
 SG_ ScFreshDataEnbl_B_Rq : 0|1@0+ (1,0) [0|1] "SED"  SOBDMC_HPCM
 SG_ ScEnbl_D_RqCld : 25|2@0+ (1,0) [0|3] "SED"  SOBDMC_HPCM

BO_ 1088 PreCond_Hev_Data1_FD1: 8 SOBDMC_HPCM
 SG_ TrlrRngId_No_Dsply : 3|4@0+ (1,0) [0|15] "unitless"  GWM
 SG_ TrlrRng_L_Dsply : 31|13@0+ (0.1,0) [0|818.9] "kilometer"  GWM
 SG_ ChrgStat_D2_Dsply : 7|4@0+ (1,0) [0|15] "SED"  GWM,ECM_HEV,PCM_HEV
 SG_ ChrgTMatch_B_Stat : 55|1@0+ (1,0) [0|1] "SED"  GWM,GENERIC
 SG_ HvacPrecondRecirc_D_Rq : 63|2@0+ (1,0) [0|3] "SED"  GWM,GENERIC
 SG_ HvacPrecondMode2_D_Rq : 51|4@0+ (1,0) [0|15] "SED"  GWM,GENERIC
 SG_ HvacPrecondBlwr2_D_Rq : 61|4@0+ (1,0) [0|15] "SED"  GWM,GENERIC
 SG_ HvacPrecondAC_D_Rq : 57|2@0+ (1,0) [0|3] "SED"  GWM,GENERIC
 SG_ HvacPrecond_Te_Rq : 44|5@0+ (0.5,14.5) [14.5|30] "deg C"  GWM,GENERIC
 SG_ BattChrgInhbt_D_Rq : 53|2@0+ (1,0) [0|3] "SED"  GWM,GENERIC
 SG_ BattDcChrgRms_I_Lim : 15|15@0+ (0.05,0) [0|1638.25] "ampere"  GWM

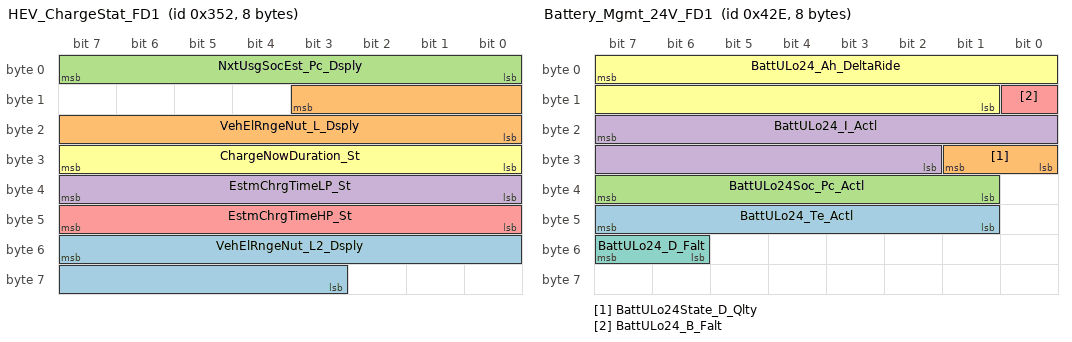
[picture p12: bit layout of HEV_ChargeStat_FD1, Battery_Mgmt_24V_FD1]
BO_ 850 HEV_ChargeStat_FD1: 8 SOBDMC_HPCM
 SG_ VehElRngeNut_L2_Dsply : 55|13@0+ (0.1,0) [0|818.9] "km"  GWM
 SG_ VehElRngeNut_L_Dsply : 11|12@0+ (0.1,0) [0|409.3] "km"  GWM
 SG_ NxtUsgSocEst_Pc_Dsply : 7|8@0+ (0.5,0) [0|126.5] "unitless"  GWM
 SG_ EstmChrgTimeLP_St : 39|8@0+ (0.1,0) [0|25.4] "hour"  GWM
 SG_ EstmChrgTimeHP_St : 47|8@0+ (0.1,0) [0|25.4] "hour"  GWM
 SG_ ChargeNowDuration_St : 31|8@0+ (0.1,0) [0|25.4] "hour"  GWM

BO_ 1070 Battery_Mgmt_24V_FD1: 8 BCM
 SG_ BattULo24_Te_Actl : 47|7@0+ (1,-40) [-40|86] "degC"  ECM_Diesel,ECM_HEVDSL,PCM
 SG_ BattULo24State_D_Qlty : 25|2@0+ (1,0) [0|3] "SED"  ECM_Diesel,ECM_HEVDSL,PCM
 SG_ BattULo24Soc_Pc_Actl : 39|7@0+ (1,0) [0|127] "percent"  PCM,ECM_Diesel,ECM_HEVDSL
 SG_ BattULo24_I_Actl : 23|14@0+ (0.0625,-512) [-512|511.875] "ampere"  ECM_Diesel,ECM_HEVDSL,PCM
 SG_ BattULo24_B_Falt : 8|1@0+ (1,0) [0|1] "SED"  ECM_Diesel,ECM_HEVDSL,PCM
 SG_ BattULo24_Ah_DeltaRide : 7|15@0+ (0.0078125,-100) [-100|155.9921875] "amperehour"  ECM_Diesel,ECM_HEVDSL,PCM
 SG_ BattULo24_D_Falt : 55|2@0+ (1,0) [0|3] "SED"  ECM_Diesel,ECM_HEVDSL,PCM

BO_ 1153 All_Terrain_Data_FD1: 8 ATCM
 SG_ TerrStat_D_RqDsply : 7|4@0+ (1,0) [0|15] "SED"  GENERIC
 SG_ TerrMde_D_RqDrv : 3|3@0+ (1,0) [0|7] "SED"  AWD_DLCM

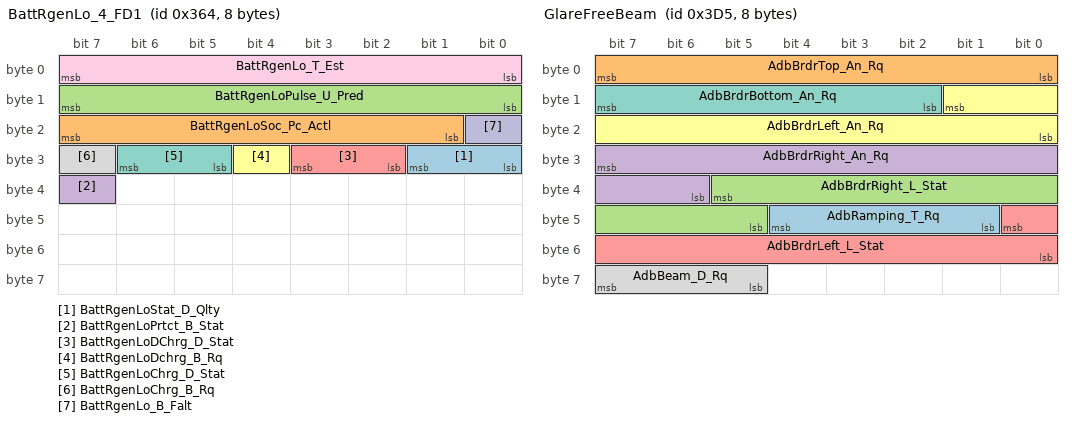
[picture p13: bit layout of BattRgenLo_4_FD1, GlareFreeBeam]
BO_ 868 BattRgenLo_4_FD1: 8 DCDC_LISB
 SG_ BattRgenLoStat_D_Qlty : 25|2@0+ (1,0) [0|3] "SED"  PCM_HEV,PCM
 SG_ BattRgenLoSoc_Pc_Actl : 23|7@0+ (1,0) [0|100] "percent"  PCM_HEV,PCM
 SG_ BattRgenLoPulse_U_Pred : 15|8@0+ (0.0625,0) [0|15.9375] "volt"  PCM_HEV,PCM
 SG_ BattRgenLoPrtct_B_Stat : 39|1@0+ (1,0) [0|1] "SED"  PCM_HEV,PCM
 SG_ BattRgenLoDChrg_D_Stat : 27|2@0+ (1,0) [0|3] "SED"  PCM_HEV,PCM
 SG_ BattRgenLoDchrg_B_Rq : 28|1@0+ (1,0) [0|1] "SED"  PCM_HEV,PCM
 SG_ BattRgenLoChrg_D_Stat : 30|2@0+ (1,0) [0|3] "SED"  PCM_HEV,PCM
 SG_ BattRgenLoChrg_B_Rq : 31|1@0+ (1,0) [0|1] "SED"  PCM_HEV,PCM
 SG_ BattRgenLo_T_Est : 7|8@0+ (8,0) [0|2040] "second"  PCM_HEV,PCM
 SG_ BattRgenLo_B_Falt : 16|1@0+ (1,0) [0|1] "SED"  PCM_HEV,PCM

BO_ 1795 TesterPhysicalReqAWD: 64 TSTR
 SG_ TesterPhysicalReqAWD : 7|64@0+ (1,0) [0|1.84467E+019] "unitless"  AWD_DLCM

BO_ 1803 TesterPhysicalResAWD: 64 AWD_DLCM
 SG_ TesterPhysicalResAWD : 7|64@0+ (1,0) [0|1.84467E+019] "unitless"  TSTR

BO_ 2611026136 PARSEDPhysGWM_ECGtoSODCMD: 64 GWM
 SG_ PARSEDPhysGWM_ECGtoSODCMD : 7|29@0+ (1,0) [0|536870911] "unitless"  IPMA_ADAS

BO_ 2611175494 PARSEDPhysSODCMDtoGWM_ECG: 64 IPMA_ADAS
 SG_ PARSEDPhysSODCMDtoGWM_ECG : 7|29@0+ (1,0) [0|536870911] "unitless"  GWM

BO_ 2612224070 PARSEDPushSODCMDtoGWM: 8 IPMA_ADAS
 SG_ PARSEDPushSODCMDtoGWM : 7|29@0+ (1,0) [0|536870911] "unitless"  GWM

BO_ 2611054808 PARSEDPhysGWM_ECGtoSODL: 64 GWM
 SG_ PARSEDPhysGWM_ECGtoSODL : 7|29@0+ (1,0) [0|536870911] "unitless"  IPMA_ADAS

BO_ 2611175523 PARSEDPhysSODRtoGWM_ECG: 64 IPMA_ADAS
 SG_ PARSEDPhysSODRtoGWM_ECG : 7|29@0+ (1,0) [0|536870911] "unitless"  GWM

BO_ 2612224099 PARSEDPushSODRtoGWM_ECG: 8 IPMA_ADAS
 SG_ PARSEDPushSODRtoGWM_ECG : 7|29@0+ (1,0) [0|536870911] "unitless"  GWM

BO_ 2611055832 PARSEDPhysGWM_ECGtoSODR: 64 GWM
 SG_ PARSEDPhysGWM_ECGtoSODR : 7|29@0+ (1,0) [0|536870911] "unitless"  IPMA_ADAS

BO_ 2611175522 PARSEDPhysSODLtoGWM_ECG: 64 IPMA_ADAS
 SG_ PARSEDPhysSODLtoGWM_ECG : 7|29@0+ (1,0) [0|536870911] "unitless"  GWM

BO_ 2612224098 PARSEDPushSODLtoGWM_ECG: 8 IPMA_ADAS
 SG_ PARSEDPushSODLtoGWM_ECG : 7|29@0+ (1,0) [0|536870911] "unitless"  GWM

BO_ 2609927384 OTAPhysGWM_ECGtoCCM: 64 GWM
 SG_ OTAPhysGWM_ECGtoCCM : 7|29@0+ (1,0) [0|536870911] "unitless"  IPMA_ADAS

BO_ 2610126869 OTAPhysCCMtoGWM_ECG: 64 IPMA_ADAS
 SG_ OTAPhysCCMtoGWM_ECG : 7|29@0+ (1,0) [0|536870911] "unitless"  GWM

BO_ 2609976536 OTAPhysGWM_ECGtoSODCMC: 64 GWM
 SG_ OTAPhysGWM_ECGtoSODCMC : 7|29@0+ (1,0) [0|536870911] "unitless"  IPMA_ADAS

BO_ 2610126917 OTAPhysSODCMCtoGWM_ECG: 64 IPMA_ADAS
 SG_ OTAPhysSODCMCtoGWM_ECG : 7|29@0+ (1,0) [0|536870911] "unitless"  GWM

BO_ 2609977560 OTAPhysGWM_ECGtoSODCMD: 64 GWM
 SG_ OTAPhysGWM_ECGtoSODCMD : 7|29@0+ (1,0) [0|536870911] "unitless"  IPMA_ADAS

BO_ 2610126918 OTAPhysSODCMDtoGWM_ECG: 64 IPMA_ADAS
 SG_ OTAPhysSODCMDtoGWM_ECG : 7|29@0+ (1,0) [0|536870911] "unitless"  GWM

BO_ 2610007256 OTAPhysGWM_ECGtoSODR: 64 GWM
 SG_ OTAPhysGWM_ECGtoSODR : 7|29@0+ (1,0) [0|536870911] "unitless"  IPMA_ADAS

BO_ 2610126947 OTAPhysSODRtoGWM_ECG: 64 IPMA_ADAS
 SG_ OTAPhysSODRtoGWM_ECG : 7|29@0+ (1,0) [0|536870911] "unitless"  GWM

BO_ 2612224017 PARSEDPushSOBDMCtoGWM_FD1: 8 SOBDMC_HPCM
 SG_ PARSEDPushSOBDMCtoGWM_ECG : 7|29@0+ (1,0) [0|536870911] "unitless"  GWM

BO_ 981 GlareFreeBeam: 8 IPMA_ADAS
 SG_ AdbRamping_T_Rq : 44|4@0+ (200,0) [0|3000] "millisecond"  HCM,GWM
 SG_ AdbBrdrTop_An_Rq : 7|8@0+ (0.04,-9.54) [-9.54|0.58] "degrees"  HCM,GWM
 SG_ AdbBrdrRight_L_Stat : 37|9@0+ (2,0) [0|1018] "meter"  HCM,GWM
 SG_ AdbBrdrRight_An_Rq : 31|10@0+ (0.04,-20.4) [-20.4|20.44] "degrees"  HCM,GWM
 SG_ AdbBrdrLeft_L_Stat : 40|9@0+ (2,0) [0|1018] "meter"  HCM,GWM
 SG_ AdbBrdrLeft_An_Rq : 9|10@0+ (0.04,-20.4) [-20.4|20.44] "degrees"  HCM,GWM
 SG_ AdbBrdrBottom_An_Rq : 15|6@0+ (0.04,-1.86) [-1.86|0.58] "degrees"  HCM,GWM
 SG_ AdbBeam_D_Rq : 63|3@0+ (1,0) [0|7] "SED"  HCM,GWM

BO_ 810 ECG_Data_FD1: 8 GWM
 SG_ VehHorn_B_RqOccAlrt : 58|1@0+ (1,0) [0|1] "SED"  GENERIC
 SG_ RmtViewMde_B_Rq : 59|1@0+ (1,0) [0|1] "SED"  GENERIC
 SG_ DteCldAcceptData_B_Rq : 60|1@0+ (1,0) [0|1] "SED"  SOBDMC_HPCM
 SG_ DteCldCnclRoute_B_Rq : 61|1@0+ (1,0) [0|1] "SED"  SOBDMC_HPCM
 SG_ NtfyDrvTrgtDist_L_Rq : 23|12@0+ (0.1,0) [0|409.5] "Km"  SOBDMC_HPCM
 SG_ NtfyDrvSocLvl1_Pc_Rq : 39|7@0+ (1,0) [0|127] "%"  SOBDMC_HPCM
 SG_ PtRmtRprt_D_Stat : 27|4@0+ (1,0) [0|15] "SED"  SOBDMC_HPCM
 SG_ ChrgrPncEnbl_D_Rq : 9|2@0+ (1,0) [0|3] "SED"  GENERIC
 SG_ OneTEditActv_B_RqCld : 32|1@0+ (1,0) [0|1] "SED"  SOBDMC_HPCM
 SG_ GoTElementEdit_No_RqCld : 43|4@0+ (1,0) [0|15] "unitless"  SOBDMC_HPCM
 SG_ OBCCSerial_D_Rq : 45|2@0+ (1,0) [0|3] "SED"  GENERIC
 SG_ ExtLghtDsply_B_StatArb : 7|1@0+ (1,0) [0|1] "SED"  GENERIC
 SG_ ExtLghtRight_D_RqOta : 12|3@0+ (1,0) [0|7] "SED"  GENERIC
 SG_ ExtLghtRear_D_RqOta : 15|3@0+ (1,0) [0|7] "SED"  GENERIC
 SG_ ExtLghtLeft_D_RqOta : 3|3@0+ (1,0) [0|7] "SED"  GENERIC
 SG_ ExtLghtFront_D_RqOta : 6|3@0+ (1,0) [0|7] "SED"  GENERIC
 SG_ TlghtTest_D_RqArb : 47|2@0+ (1,0) [0|3] "SED"  GENERIC
 SG_ ChrgrPncSustn_B_Rq : 0|1@0+ (1,0) [0|1] "SED"  GENERIC
 SG_ GoTAirAmb_Te_ActlCld : 55|10@0+ (0.25,-128) [-128|127.75] "degC"  SOBDMC_HPCM

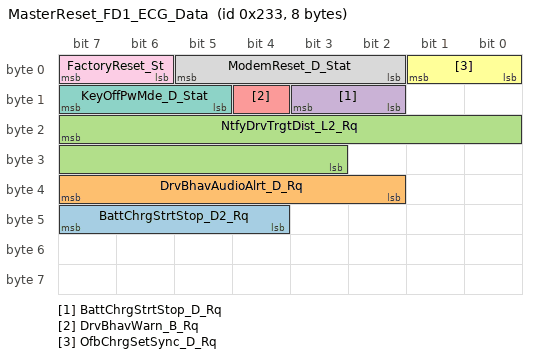
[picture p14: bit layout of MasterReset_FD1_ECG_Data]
BO_ 563 MasterReset_FD1_ECG_Data: 8 GWM
 SG_ BattChrgStrtStop_D2_Rq : 47|4@0+ (1,0) [0|15] "SED"  SOBDMC_HPCM
 SG_ DrvBhavAudioAlrt_D_Rq : 39|6@0+ (1,0) [0|63] "SED"  GENERIC
 SG_ NtfyDrvTrgtDist_L2_Rq : 23|13@0+ (0.1,0) [0|818.9] "Km"  SOBDMC_HPCM
 SG_ BattChrgStrtStop_D_Rq : 11|2@0+ (1,0) [0|3] "SED"  SOBDMC_HPCM
 SG_ DrvBhavWarn_B_Rq : 12|1@0+ (1,0) [0|1] "SED"  GENERIC
 SG_ OfbChrgSetSync_D_Rq : 1|2@0+ (1,0) [0|3] "SED"  SOBDMC_HPCM
 SG_ KeyOffPwMde_D_Stat : 15|3@0+ (1,0) [0|7] "SED"  GENERIC
 SG_ ModemReset_D_Stat : 5|4@0+ (1,0) [0|15] "SED"  GENERIC
 SG_ FactoryReset_St : 7|2@0+ (1,0) [0|3] "SED"  GENERIC

BO_ 2609923288 OTAPhysGWM_ECGtoSOBDMC_FD1: 64 GWM
 SG_ OTAPhysGWM_ECGtoSOBDMC : 7|29@0+ (1,0) [0|536870911] "unitless"  SOBDMC_HPCM

BO_TX_BU_ 785 : PCM_HEV,SOBDMC_HPCM;
BO_TX_BU_ 991 : GWM,VDM;
BO_TX_BU_ 515 : PCM_HEV,PCM,ECM_HEVDSL,ECM_HEV,ECM_Diesel,ECM,SOBDMC_HPCM;
CM_ SG_ 942 PrkAidRdiusRight_L_Dsply "MSGDCR 679, set all signals to OnChange";
CM_ SG_ 942 PrkAidRdiusLeft_L_Dsply "MSGDCR 679, set all signals to OnChange";
CM_ SG_ 942 PrkAidDrvDir_D_Stat "MSGDCR 679, set all signals to OnChange";
CM_ BO_ 949 "For 2010MY and beyond, use for SCT (non-CGEA) and CGEA modules";
CM_ SG_ 550 PtWakeupActv1_B_Rq "ECG Application signal";
CM_ BO_ 885 "NOTE: START BITS 8-11 MUST BE OPEN SPEC REQUIREMENT";
CM_ BO_ 739 "FCDIM Tx";
CM_ SG_ 739 Partial_Amp_Shutdown "Method Partial_Amp_Shutdown";
CM_ SG_ 739 HMI_HMIMode_St "Object ACU System Master.HMIMode
OR
Object NAV System Master.HMIMode

Refer Method HMIAudioMode in the SPSS";
CM_ BO_ 1160 "some signals from HS4 0x22A TCU_EM in CGEA1.3";
CM_ SG_ 542 LocationServices_3 "Tx by HS3 APIM";
CM_ SG_ 982 LatCtlPath_No_Cnt "Signal not transmitted on gas variants.";
CM_ SG_ 982 LatCtlPath_No_Cs "Signal not transmitted on gas variants.";
CM_ SG_ 1104 DrvEngageLevel_No_Cs "Signal not transmitted on gas variants.";
CM_ SG_ 1104 DrvEngageLevel_No_Cnt "Signal not transmitted on gas variants.";
CM_ SG_ 1088 HvacPrecondMode2_D_Rq "Signal not transmitted on vehicles that do not have the Fuel operated heater feature.";
CM_ SG_ 1088 HvacPrecondBlwr2_D_Rq "Signal not transmitted on vehicles that do not have the Fuel operated heater feature.";
CM_ SG_ 810 NtfyDrvTrgtDist_L_Rq "Object.SetTripRangeAlert_Rq
This signal is meant to provide the customer settings for the target distance remote notification";
CM_ SG_ 810 NtfyDrvSocLvl1_Pc_Rq "Object.SetCustomerLevelAlert_Rq
This signal is meant to provide the customer settings for the SOC remote notification.";
CM_ SG_ 810 PtRmtRprt_D_Stat "Object.RemoteDataReport_St
";
CM_ SG_ 563 NtfyDrvTrgtDist_L2_Rq "Object.SetTripRangeAlert_Rq
This signal is meant to provide the customer settings for the target distance remote notification";
BA_DEF_ BO_  "VFrameFormat" ENUM  "StandardCAN","ExtendedCAN","reserved","reserved","reserved","reserved","reserved","reserved","reserved","reserved","reserved","reserved","reserved","reserved","StandardCAN_FD","ExtendedCAN_FD";
BA_DEF_ SG_  "GenSigSendType" ENUM  "Cyclic","OnWrite","vector_leerstring","OnChange","vector_leerstring","IfActive","vector_leerstring","NoSigSendType";
BA_DEF_ SG_  "GenSigInactiveValue" INT 0 100000;
BA_DEF_ SG_  "WakeupSignal" ENUM  "No","Yes";
BA_DEF_ SG_  "UsedOnPgmDBC" ENUM  "No","Yes";
BA_DEF_ SG_  "GenSigStartValueInteger" INT 0 1000000000;
BA_DEF_ SG_  "ContentDependant" ENUM  "No","Yes";
BA_DEF_ SG_  "MetaData" ENUM  "No","Yes";
BA_DEF_ SG_  "GenSigStartValue" HEX 0 268435455;
BA_DEF_ SG_  "U_CX727_MY2021_Rx" ENUM  "No","Yes";
BA_DEF_ SG_  "U_P702_MY2021_Rx" ENUM  "No","Yes";
BA_DEF_ SG_  "U_T6_MCA_MY2020_Rx" ENUM  "No","Yes";
BA_DEF_ SG_  "ECGUsedRxSignal" ENUM  "No","Yes";
BA_DEF_ SG_  "U_CD542_MY2021_Rx" ENUM  "No","Yes";
BA_DEF_ SG_  "U_U55X_MY2022_Rx" ENUM  "No","Yes";
BA_DEF_ SG_  "U_CD764_MY2022_Rx" ENUM  "No","Yes";
BA_DEF_ SG_  "U_CDX706_MY2023_Rx" ENUM  "No","Yes";
BA_DEF_ SG_  "U_CX727_MY2021_Tx" ENUM  "No","Yes";
BA_DEF_ SG_  "U_P702_MY2021_Tx" ENUM  "No","Yes";
BA_DEF_ SG_  "U_T6_MCA_MY2020_Tx" ENUM  "No","Yes";
BA_DEF_ SG_  "ECGUsedTxSignal" ENUM  "No","Yes";
BA_DEF_ SG_  "U_CD542_MY2021_Tx" ENUM  "No","Yes";
BA_DEF_ SG_  "U_U55X_MY2022_Tx" ENUM  "No","Yes";
BA_DEF_ SG_  "U_CD764_MY2022_Tx" ENUM  "No","Yes";
BA_DEF_ SG_  "U_CDX706_MY2023_Tx" ENUM  "No","Yes";
BA_DEF_ BO_  "GenMsgILSupport" ENUM  "No","Yes";
BA_DEF_ BO_  "DiagResponse" ENUM  "No","Yes";
BA_DEF_ BO_  "DiagRequest" ENUM  "No","Yes";
BA_DEF_ BO_  "TpTxIndex" INT 0 536870911;
BA_DEF_ BO_  "DiagState" ENUM  "No","Yes";
BA_DEF_ BO_  "TpApplType" STRING ;
BA_DEF_ BO_  "NmAsrMessage" ENUM  "No","Yes";
BA_DEF_ BO_  "ProgBWConditional" STRING ;
BA_DEF_ BO_  "SCP_AuthInfoTxLength" INT 0 512;
BA_DEF_ BO_  "SCP_FreshnessValueTxLength" INT 0 512;
BA_DEF_ BO_  "SCP_FreshnessValueLength" INT 0 512;
BA_DEF_ BO_  "OvtpPushApplication" ENUM  "FALSE","TRUE";
BA_DEF_ BO_  "GenMsgSendType" ENUM  "FixedPeriodic","Event","EnabledPeriodic","NotUsed","NotUsed","EventPeriodic","NotUsed","NotUsed","NoMsgSendType";
BA_DEF_ BO_  "GenMsgCycleTime" INT 0 100000;
BA_DEF_ BO_  "GenMsgDelayTime" INT 0 1000;
BA_DEF_ BO_  "GenMsgNrOfRepetition" INT 0 100;
BA_DEF_ BO_  "GenMsgStartDelayTime" INT 0 10000;
BA_DEF_ BO_  "EventRateOfChange" INT 10 10000;
BA_DEF_ BO_  "FrameGatewayId" HEX 0 1407;
BA_DEF_ BO_  "NetworkInitialization" ENUM  "No","Yes";
BA_DEF_ BO_  "FrameGatewayNetwork" STRING ;
BA_DEF_ BO_  "FrameRouting" STRING ;
BA_DEF_DEF_  "VFrameFormat" "ExtendedCAN_FD";
BA_DEF_DEF_  "GenSigSendType" "NoSigSendType";
BA_DEF_DEF_  "GenSigInactiveValue" 0;
BA_DEF_DEF_  "WakeupSignal" "No";
BA_DEF_DEF_  "UsedOnPgmDBC" "Yes";
BA_DEF_DEF_  "GenSigStartValueInteger" 0;
BA_DEF_DEF_  "ContentDependant" "No";
BA_DEF_DEF_  "MetaData" "No";
BA_DEF_DEF_  "GenSigStartValue" 0;
BA_DEF_DEF_  "U_CX727_MY2021_Rx" "No";
BA_DEF_DEF_  "U_P702_MY2021_Rx" "No";
BA_DEF_DEF_  "U_T6_MCA_MY2020_Rx" "No";
BA_DEF_DEF_  "ECGUsedRxSignal" "No";
BA_DEF_DEF_  "U_CD542_MY2021_Rx" "No";
BA_DEF_DEF_  "U_U55X_MY2022_Rx" "No";
BA_DEF_DEF_  "U_CD764_MY2022_Rx" "No";
BA_DEF_DEF_  "U_CDX706_MY2023_Rx" "No";
BA_DEF_DEF_  "U_CX727_MY2021_Tx" "No";
BA_DEF_DEF_  "U_P702_MY2021_Tx" "No";
BA_DEF_DEF_  "U_T6_MCA_MY2020_Tx" "No";
BA_DEF_DEF_  "ECGUsedTxSignal" "No";
BA_DEF_DEF_  "U_CD542_MY2021_Tx" "No";
BA_DEF_DEF_  "U_U55X_MY2022_Tx" "No";
BA_DEF_DEF_  "U_CD764_MY2022_Tx" "No";
BA_DEF_DEF_  "U_CDX706_MY2023_Tx" "No";
BA_DEF_DEF_  "GenMsgILSupport" "Yes";
BA_DEF_DEF_  "DiagResponse" "No";
BA_DEF_DEF_  "DiagRequest" "No";
BA_DEF_DEF_  "TpTxIndex" 0;
BA_DEF_DEF_  "DiagState" "No";
BA_DEF_DEF_  "TpApplType" "";
BA_DEF_DEF_  "NmAsrMessage" "No";
BA_DEF_DEF_  "ProgBWConditional" "NONE";
BA_DEF_DEF_  "SCP_AuthInfoTxLength" 53;
BA_DEF_DEF_  "SCP_FreshnessValueTxLength" 11;
BA_DEF_DEF_  "SCP_FreshnessValueLength" 64;
BA_DEF_DEF_  "OvtpPushApplication" "FALSE";
BA_DEF_DEF_  "GenMsgSendType" "NoMsgSendType";
BA_DEF_DEF_  "GenMsgCycleTime" 0;
BA_DEF_DEF_  "GenMsgDelayTime" 20;
BA_DEF_DEF_  "GenMsgNrOfRepetition" 1;
BA_DEF_DEF_  "GenMsgStartDelayTime" 0;
BA_DEF_DEF_  "EventRateOfChange" 10000;
BA_DEF_DEF_  "FrameGatewayId" 0;
BA_DEF_DEF_  "NetworkInitialization" "Yes";
BA_DEF_DEF_  "FrameGatewayNetwork" "NONE";
BA_DEF_DEF_  "FrameRouting" "";
BA_ "GenMsgSendType" BO_ 123 0;
BA_ "GenMsgCycleTime" BO_ 123 10;
BA_ "GenMsgSendType" BO_ 949 0;
BA_ "GenMsgCycleTime" BO_ 949 500;
BA_ "GenMsgSendType" BO_ 979 0;
BA_ "GenMsgCycleTime" BO_ 979 50;
BA_ "GenMsgSendType" BO_ 739 5;
BA_ "GenMsgCycleTime" BO_ 739 1000;
BA_ "GenMsgSendType" BO_ 1001 5;
BA_ "GenMsgCycleTime" BO_ 1001 1000;
BA_ "GenMsgSendType" BO_ 1077 0;
BA_ "GenMsgCycleTime" BO_ 1077 1000;
BA_ "GenMsgSendType" BO_ 945 5;
BA_ "GenMsgCycleTime" BO_ 945 1000;
BA_ "GenMsgSendType" BO_ 395 5;
BA_ "GenMsgCycleTime" BO_ 395 1000;
BA_ "GenMsgSendType" BO_ 542 1;
BA_ "GenMsgSendType" BO_ 829 0;
BA_ "GenMsgCycleTime" BO_ 829 100;
BA_ "GenMsgSendType" BO_ 1070 0;
BA_ "GenMsgCycleTime" BO_ 1070 40;
BA_ "GenMsgSendType" BO_ 1153 0;
BA_ "GenMsgCycleTime" BO_ 1153 100;
BA_ "GenMsgSendType" BO_ 868 5;
BA_ "GenMsgCycleTime" BO_ 868 1000;
BA_ "GenMsgSendType" BO_ 785 5;
BA_ "GenMsgCycleTime" BO_ 785 1000;
BA_ "VFrameFormat" BO_ 785 14;
BA_ "GenMsgSendType" BO_ 770 5;
BA_ "GenMsgCycleTime" BO_ 770 1000;
BA_ "VFrameFormat" BO_ 770 14;
BA_ "GenMsgSendType" BO_ 1205 5;
BA_ "GenMsgCycleTime" BO_ 1205 100000;
BA_ "GenMsgStartDelayTime" BO_ 1205 1130;
BA_ "VFrameFormat" BO_ 1205 14;
BA_ "GenMsgSendType" BO_ 942 5;
BA_ "GenMsgCycleTime" BO_ 942 200;
BA_ "VFrameFormat" BO_ 942 14;
BA_ "FrameGatewayId" BO_ 123 123;
BA_ "FrameGatewayNetwork" BO_ 123 "HS1_CAN";
BA_ "FrameRouting" BO_ 123 "HS1_CAN,0x7B;";
BA_ "VFrameFormat" BO_ 123 14;
BA_ "TpTxIndex" BO_ 2612052184 464568536;
BA_ "OvtpPushApplication" BO_ 2612052184 1;
BA_ "GenMsgSendType" BO_ 2612052184 1;
BA_ "GenMsgDelayTime" BO_ 2612052184 0;
BA_ "NetworkInitialization" BO_ 2612052184 0;
BA_ "TpTxIndex" BO_ 2612224187 464710872;
BA_ "OvtpPushApplication" BO_ 2612224187 1;
BA_ "GenMsgSendType" BO_ 2612224187 1;
BA_ "GenMsgDelayTime" BO_ 2612224187 0;
BA_ "NetworkInitialization" BO_ 2612224187 0;
BA_ "GenMsgSendType" BO_ 1201 5;
BA_ "GenMsgCycleTime" BO_ 1201 1000;
BA_ "VFrameFormat" BO_ 1201 14;
BA_ "GenMsgILSupport" BO_ 1912 0;
BA_ "DiagResponse" BO_ 1912 1;
BA_ "GenMsgSendType" BO_ 1912 1;
BA_ "GenMsgDelayTime" BO_ 1912 0;
BA_ "NetworkInitialization" BO_ 1912 0;
BA_ "VFrameFormat" BO_ 1912 14;
BA_ "GenMsgILSupport" BO_ 1904 0;
BA_ "DiagRequest" BO_ 1904 1;
BA_ "GenMsgSendType" BO_ 1904 1;
BA_ "GenMsgDelayTime" BO_ 1904 0;
BA_ "NetworkInitialization" BO_ 1904 0;
BA_ "VFrameFormat" BO_ 1904 14;
BA_ "GenMsgILSupport" BO_ 1527 0;
BA_ "NmAsrMessage" BO_ 1527 1;
BA_ "GenMsgSendType" BO_ 1527 0;
BA_ "GenMsgCycleTime" BO_ 1527 1000;
BA_ "NetworkInitialization" BO_ 1527 0;
BA_ "VFrameFormat" BO_ 1527 14;
BA_ "GenMsgSendType" BO_ 1239 5;
BA_ "GenMsgCycleTime" BO_ 1239 1000;
BA_ "VFrameFormat" BO_ 1239 14;
BA_ "FrameGatewayId" BO_ 949 949;
BA_ "FrameGatewayNetwork" BO_ 949 "HS1_CAN";
BA_ "FrameRouting" BO_ 949 "HS1_CAN,0x3B5;";
BA_ "VFrameFormat" BO_ 949 14;
BA_ "TpTxIndex" BO_ 2612118744 464635096;
BA_ "OvtpPushApplication" BO_ 2612118744 1;
BA_ "GenMsgSendType" BO_ 2612118744 1;
BA_ "GenMsgDelayTime" BO_ 2612118744 0;
BA_ "NetworkInitialization" BO_ 2612118744 0;
BA_ "TpTxIndex" BO_ 2612074712 464591064;
BA_ "OvtpPushApplication" BO_ 2612074712 1;
BA_ "GenMsgSendType" BO_ 2612074712 1;
BA_ "GenMsgDelayTime" BO_ 2612074712 0;
BA_ "NetworkInitialization" BO_ 2612074712 0;
BA_ "TpTxIndex" BO_ 2612024536 464540888;
BA_ "OvtpPushApplication" BO_ 2612024536 1;
BA_ "GenMsgSendType" BO_ 2612024536 1;
BA_ "GenMsgDelayTime" BO_ 2612024536 0;
BA_ "NetworkInitialization" BO_ 2612024536 0;
BA_ "TpTxIndex" BO_ 2612036824 464553176;
BA_ "OvtpPushApplication" BO_ 2612036824 1;
BA_ "GenMsgSendType" BO_ 2612036824 1;
BA_ "GenMsgDelayTime" BO_ 2612036824 0;
BA_ "NetworkInitialization" BO_ 2612036824 0;
BA_ "TpTxIndex" BO_ 2612103384 464619736;
BA_ "OvtpPushApplication" BO_ 2612103384 1;
BA_ "GenMsgSendType" BO_ 2612103384 1;
BA_ "GenMsgDelayTime" BO_ 2612103384 0;
BA_ "NetworkInitialization" BO_ 2612103384 0;
BA_ "GenMsgSendType" BO_ 639 5;
BA_ "GenMsgCycleTime" BO_ 639 1000;
BA_ "VFrameFormat" BO_ 639 14;
BA_ "GenMsgSendType" BO_ 530 5;
BA_ "GenMsgCycleTime" BO_ 530 1000;
BA_ "VFrameFormat" BO_ 530 14;
BA_ "GenMsgSendType" BO_ 550 5;
BA_ "GenMsgCycleTime" BO_ 550 1000;
BA_ "VFrameFormat" BO_ 550 14;
BA_ "FrameGatewayId" BO_ 879 879;
BA_ "FrameGatewayNetwork" BO_ 879 "HS1_CAN";
BA_ "FrameRouting" BO_ 879 "HS1_CAN,0x36F;";
BA_ "VFrameFormat" BO_ 879 14;
BA_ "GenMsgILSupport" BO_ 1455 0;
BA_ "NmAsrMessage" BO_ 1455 1;
BA_ "GenMsgSendType" BO_ 1455 0;
BA_ "GenMsgCycleTime" BO_ 1455 1000;
BA_ "NetworkInitialization" BO_ 1455 0;
BA_ "VFrameFormat" BO_ 1455 14;
BA_ "GenMsgILSupport" BO_ 1775 0;
BA_ "DiagResponse" BO_ 1775 1;
BA_ "GenMsgSendType" BO_ 1775 1;
BA_ "GenMsgDelayTime" BO_ 1775 0;
BA_ "NetworkInitialization" BO_ 1775 0;
BA_ "VFrameFormat" BO_ 1775 14;
BA_ "GenMsgILSupport" BO_ 1767 0;
BA_ "DiagRequest" BO_ 1767 1;
BA_ "GenMsgSendType" BO_ 1767 1;
BA_ "GenMsgDelayTime" BO_ 1767 0;
BA_ "NetworkInitialization" BO_ 1767 0;
BA_ "VFrameFormat" BO_ 1767 14;
BA_ "TpTxIndex" BO_ 2612019416 464535768;
BA_ "OvtpPushApplication" BO_ 2612019416 1;
BA_ "GenMsgSendType" BO_ 2612019416 1;
BA_ "GenMsgDelayTime" BO_ 2612019416 0;
BA_ "NetworkInitialization" BO_ 2612019416 0;
BA_ "GenMsgSendType" BO_ 885 0;
BA_ "GenMsgCycleTime" BO_ 885 200;
BA_ "VFrameFormat" BO_ 885 14;
BA_ "TpTxIndex" BO_ 2612104408 464620760;
BA_ "OvtpPushApplication" BO_ 2612104408 1;
BA_ "GenMsgSendType" BO_ 2612104408 1;
BA_ "GenMsgDelayTime" BO_ 2612104408 0;
BA_ "NetworkInitialization" BO_ 2612104408 0;
BA_ "TpTxIndex" BO_ 2612020440 464536792;
BA_ "OvtpPushApplication" BO_ 2612020440 1;
BA_ "GenMsgSendType" BO_ 2612020440 1;
BA_ "GenMsgDelayTime" BO_ 2612020440 0;
BA_ "NetworkInitialization" BO_ 2612020440 0;
BA_ "FrameGatewayId" BO_ 979 979;
BA_ "FrameGatewayNetwork" BO_ 979 "HS2_CAN";
BA_ "FrameRouting" BO_ 979 "HS2_CAN,0x3D3;";
BA_ "VFrameFormat" BO_ 979 14;
BA_ "FrameGatewayId" BO_ 739 739;
BA_ "FrameGatewayNetwork" BO_ 739 "HS3_CAN";
BA_ "FrameRouting" BO_ 739 "HS3_CAN,0x2E3;";
BA_ "VFrameFormat" BO_ 739 14;
BA_ "GenMsgSendType" BO_ 1160 5;
BA_ "GenMsgCycleTime" BO_ 1160 1000;
BA_ "VFrameFormat" BO_ 1160 14;
BA_ "GenMsgILSupport" BO_ 1825 0;
BA_ "DiagRequest" BO_ 1825 1;
BA_ "GenMsgSendType" BO_ 1825 1;
BA_ "GenMsgDelayTime" BO_ 1825 0;
BA_ "NetworkInitialization" BO_ 1825 0;
BA_ "VFrameFormat" BO_ 1825 14;
BA_ "FrameGatewayId" BO_ 1001 1001;
BA_ "FrameGatewayNetwork" BO_ 1001 "HS2_CAN";
BA_ "FrameRouting" BO_ 1001 "HS2_CAN,0x3E9;";
BA_ "VFrameFormat" BO_ 1001 14;
BA_ "FrameGatewayId" BO_ 1077 1077;
BA_ "FrameGatewayNetwork" BO_ 1077 "HS2_CAN";
BA_ "FrameRouting" BO_ 1077 "HS2_CAN,0x435;";
BA_ "VFrameFormat" BO_ 1077 14;
BA_ "FrameGatewayId" BO_ 945 945;
BA_ "FrameGatewayNetwork" BO_ 945 "HS1_CAN";
BA_ "FrameRouting" BO_ 945 "HS1_CAN,0x3B1;";
BA_ "VFrameFormat" BO_ 945 14;
BA_ "TpTxIndex" BO_ 2612073688 464590040;
BA_ "OvtpPushApplication" BO_ 2612073688 1;
BA_ "GenMsgSendType" BO_ 2612073688 1;
BA_ "GenMsgDelayTime" BO_ 2612073688 0;
BA_ "NetworkInitialization" BO_ 2612073688 0;
BA_ "GenMsgSendType" BO_ 771 5;
BA_ "GenMsgCycleTime" BO_ 771 1000;
BA_ "VFrameFormat" BO_ 771 14;
BA_ "GenMsgSendType" BO_ 777 5;
BA_ "GenMsgCycleTime" BO_ 777 1000;
BA_ "VFrameFormat" BO_ 777 14;
BA_ "GenMsgSendType" BO_ 1043 5;
BA_ "GenMsgCycleTime" BO_ 1043 1000;
BA_ "VFrameFormat" BO_ 1043 14;
BA_ "GenMsgILSupport" BO_ 1833 0;
BA_ "DiagResponse" BO_ 1833 1;
BA_ "GenMsgSendType" BO_ 1833 1;
BA_ "GenMsgDelayTime" BO_ 1833 0;
BA_ "NetworkInitialization" BO_ 1833 0;
BA_ "VFrameFormat" BO_ 1833 14;
BA_ "GenMsgSendType" BO_ 991 5;
BA_ "GenMsgCycleTime" BO_ 991 1000;
BA_ "VFrameFormat" BO_ 991 14;
BA_ "FrameGatewayId" BO_ 395 395;
BA_ "FrameGatewayNetwork" BO_ 395 "HS3_CAN";
BA_ "FrameRouting" BO_ 395 "HS3_CAN,0x18B;";
BA_ "VFrameFormat" BO_ 395 14;
BA_ "FrameGatewayId" BO_ 542 542;
BA_ "FrameGatewayNetwork" BO_ 542 "HS4_CAN";
BA_ "FrameRouting" BO_ 542 "HS4_CAN,0x21E;";
BA_ "VFrameFormat" BO_ 542 14;
BA_ "GenMsgILSupport" BO_ 1689 0;
BA_ "TpApplType" BO_ 1689 "DiagUUDTResponse";
BA_ "GenMsgSendType" BO_ 1689 1;
BA_ "NetworkInitialization" BO_ 1689 0;
BA_ "VFrameFormat" BO_ 1689 14;
BA_ "GenMsgSendType" BO_ 515 5;
BA_ "GenMsgCycleTime" BO_ 515 100;
BA_ "VFrameFormat" BO_ 515 14;
BA_ "GenMsgSendType" BO_ 982 0;
BA_ "GenMsgCycleTime" BO_ 982 50;
BA_ "FrameRouting" BO_ 982 "FD1_CAN,0x3D6;HS2_CAN,0x3D6";
BA_ "VFrameFormat" BO_ 982 14;
BA_ "GenMsgSendType" BO_ 1104 0;
BA_ "GenMsgCycleTime" BO_ 1104 200;
BA_ "VFrameFormat" BO_ 1104 14;
BA_ "FrameGatewayId" BO_ 829 829;
BA_ "FrameGatewayNetwork" BO_ 829 "HS1_CAN";
BA_ "FrameRouting" BO_ 829 "HS1_CAN,0x33D;";
BA_ "VFrameFormat" BO_ 829 14;
BA_ "TpTxIndex" BO_ 2611070168 463586520;
BA_ "GenMsgSendType" BO_ 2611070168 1;
BA_ "GenMsgDelayTime" BO_ 2611070168 0;
BA_ "NetworkInitialization" BO_ 2611070168 0;
BA_ "TpTxIndex" BO_ 2611175537 463586520;
BA_ "GenMsgSendType" BO_ 2611175537 1;
BA_ "GenMsgDelayTime" BO_ 2611175537 0;
BA_ "NetworkInitialization" BO_ 2611175537 0;
BA_ "TpTxIndex" BO_ 2612224113 464635096;
BA_ "OvtpPushApplication" BO_ 2612224113 1;
BA_ "GenMsgSendType" BO_ 2612224113 1;
BA_ "GenMsgDelayTime" BO_ 2612224113 0;
BA_ "NetworkInitialization" BO_ 2612224113 0;
BA_ "TpTxIndex" BO_ 2610021592 462537944;
BA_ "GenMsgSendType" BO_ 2610021592 1;
BA_ "GenMsgDelayTime" BO_ 2610021592 0;
BA_ "NetworkInitialization" BO_ 2610021592 0;
BA_ "TpTxIndex" BO_ 2610126961 462537944;
BA_ "GenMsgSendType" BO_ 2610126961 1;
BA_ "GenMsgDelayTime" BO_ 2610126961 0;
BA_ "NetworkInitialization" BO_ 2610126961 0;
BA_ "TpTxIndex" BO_ 2610975960 463492312;
BA_ "GenMsgSendType" BO_ 2610975960 1;
BA_ "GenMsgDelayTime" BO_ 2610975960 0;
BA_ "NetworkInitialization" BO_ 2610975960 0;
BA_ "TpTxIndex" BO_ 2611175445 463492312;
BA_ "GenMsgSendType" BO_ 2611175445 1;
BA_ "GenMsgDelayTime" BO_ 2611175445 0;
BA_ "NetworkInitialization" BO_ 2611175445 0;
BA_ "TpTxIndex" BO_ 2612224021 464540888;
BA_ "OvtpPushApplication" BO_ 2612224021 1;
BA_ "GenMsgSendType" BO_ 2612224021 1;
BA_ "GenMsgDelayTime" BO_ 2612224021 0;
BA_ "NetworkInitialization" BO_ 2612224021 0;
BA_ "TpTxIndex" BO_ 2611025112 463541464;
BA_ "GenMsgSendType" BO_ 2611025112 1;
BA_ "GenMsgDelayTime" BO_ 2611025112 0;
BA_ "NetworkInitialization" BO_ 2611025112 0;
BA_ "TpTxIndex" BO_ 2611175493 463541464;
BA_ "GenMsgSendType" BO_ 2611175493 1;
BA_ "GenMsgDelayTime" BO_ 2611175493 0;
BA_ "NetworkInitialization" BO_ 2611175493 0;
BA_ "TpTxIndex" BO_ 2612224069 464590040;
BA_ "OvtpPushApplication" BO_ 2612224069 1;
BA_ "GenMsgSendType" BO_ 2612224069 1;
BA_ "GenMsgDelayTime" BO_ 2612224069 0;
BA_ "NetworkInitialization" BO_ 2612224069 0;
BA_ "GenMsgILSupport" BO_ 1787 0;
BA_ "DiagResponse" BO_ 1787 1;
BA_ "GenMsgSendType" BO_ 1787 1;
BA_ "GenMsgDelayTime" BO_ 1787 0;
BA_ "NetworkInitialization" BO_ 1787 0;
BA_ "VFrameFormat" BO_ 1787 14;
BA_ "GenMsgILSupport" BO_ 1779 0;
BA_ "DiagRequest" BO_ 1779 1;
BA_ "GenMsgSendType" BO_ 1779 1;
BA_ "GenMsgDelayTime" BO_ 1779 0;
BA_ "NetworkInitialization" BO_ 1779 0;
BA_ "VFrameFormat" BO_ 1779 14;
BA_ "GenMsgILSupport" BO_ 1786 0;
BA_ "DiagResponse" BO_ 1786 1;
BA_ "GenMsgSendType" BO_ 1786 1;
BA_ "GenMsgDelayTime" BO_ 1786 0;
BA_ "NetworkInitialization" BO_ 1786 0;
BA_ "VFrameFormat" BO_ 1786 14;
BA_ "GenMsgSendType" BO_ 1089 0;
BA_ "GenMsgCycleTime" BO_ 1089 1000;
BA_ "VFrameFormat" BO_ 1089 14;
BA_ "GenMsgILSupport" BO_ 1778 0;
BA_ "DiagRequest" BO_ 1778 1;
BA_ "GenMsgSendType" BO_ 1778 1;
BA_ "GenMsgDelayTime" BO_ 1778 0;
BA_ "NetworkInitialization" BO_ 1778 0;
BA_ "VFrameFormat" BO_ 1778 14;
BA_ "GenMsgSendType" BO_ 776 5;
BA_ "GenMsgCycleTime" BO_ 776 1000;
BA_ "VFrameFormat" BO_ 776 14;
BA_ "GenMsgSendType" BO_ 1088 0;
BA_ "GenMsgCycleTime" BO_ 1088 1000;
BA_ "VFrameFormat" BO_ 1088 14;
BA_ "GenMsgSendType" BO_ 850 0;
BA_ "GenMsgCycleTime" BO_ 850 150;
BA_ "VFrameFormat" BO_ 850 14;
BA_ "FrameGatewayId" BO_ 1070 1070;
BA_ "FrameGatewayNetwork" BO_ 1070 "HS1_CAN";
BA_ "FrameRouting" BO_ 1070 "HS1_CAN,0x42E;";
BA_ "VFrameFormat" BO_ 1070 14;
BA_ "FrameGatewayId" BO_ 1153 1152;
BA_ "FrameGatewayNetwork" BO_ 1153 "HS2_CAN";
BA_ "FrameRouting" BO_ 1153 "HS2_CAN,0x480;";
BA_ "VFrameFormat" BO_ 1153 14;
BA_ "FrameGatewayId" BO_ 868 868;
BA_ "FrameGatewayNetwork" BO_ 868 "HS1_CAN";
BA_ "FrameRouting" BO_ 868 "HS1_CAN,0x364;";
BA_ "VFrameFormat" BO_ 868 14;
BA_ "GenMsgILSupport" BO_ 1795 0;
BA_ "DiagRequest" BO_ 1795 1;
BA_ "GenMsgSendType" BO_ 1795 1;
BA_ "GenMsgDelayTime" BO_ 1795 0;
BA_ "NetworkInitialization" BO_ 1795 0;
BA_ "VFrameFormat" BO_ 1795 14;
BA_ "GenMsgILSupport" BO_ 1803 0;
BA_ "DiagResponse" BO_ 1803 1;
BA_ "GenMsgSendType" BO_ 1803 1;
BA_ "GenMsgDelayTime" BO_ 1803 0;
BA_ "NetworkInitialization" BO_ 1803 0;
BA_ "VFrameFormat" BO_ 1803 14;
BA_ "TpTxIndex" BO_ 2611026136 463542488;
BA_ "GenMsgSendType" BO_ 2611026136 1;
BA_ "GenMsgDelayTime" BO_ 2611026136 0;
BA_ "NetworkInitialization" BO_ 2611026136 0;
BA_ "TpTxIndex" BO_ 2611175494 463542488;
BA_ "GenMsgSendType" BO_ 2611175494 1;
BA_ "GenMsgDelayTime" BO_ 2611175494 0;
BA_ "NetworkInitialization" BO_ 2611175494 0;
BA_ "TpTxIndex" BO_ 2612224070 464591064;
BA_ "OvtpPushApplication" BO_ 2612224070 1;
BA_ "GenMsgSendType" BO_ 2612224070 1;
BA_ "GenMsgDelayTime" BO_ 2612224070 0;
BA_ "NetworkInitialization" BO_ 2612224070 0;
BA_ "TpTxIndex" BO_ 2611054808 463571160;
BA_ "GenMsgSendType" BO_ 2611054808 1;
BA_ "GenMsgDelayTime" BO_ 2611054808 0;
BA_ "NetworkInitialization" BO_ 2611054808 0;
BA_ "TpTxIndex" BO_ 2611175523 463572184;
BA_ "GenMsgSendType" BO_ 2611175523 1;
BA_ "GenMsgDelayTime" BO_ 2611175523 0;
BA_ "NetworkInitialization" BO_ 2611175523 0;
BA_ "TpTxIndex" BO_ 2612224099 464620760;
BA_ "OvtpPushApplication" BO_ 2612224099 1;
BA_ "GenMsgSendType" BO_ 2612224099 1;
BA_ "GenMsgDelayTime" BO_ 2612224099 0;
BA_ "NetworkInitialization" BO_ 2612224099 0;
BA_ "TpTxIndex" BO_ 2611055832 463572184;
BA_ "GenMsgSendType" BO_ 2611055832 1;
BA_ "GenMsgDelayTime" BO_ 2611055832 0;
BA_ "NetworkInitialization" BO_ 2611055832 0;
BA_ "TpTxIndex" BO_ 2611175522 463571160;
BA_ "GenMsgSendType" BO_ 2611175522 1;
BA_ "GenMsgDelayTime" BO_ 2611175522 0;
BA_ "NetworkInitialization" BO_ 2611175522 0;
BA_ "TpTxIndex" BO_ 2612224098 464619736;
BA_ "OvtpPushApplication" BO_ 2612224098 1;
BA_ "GenMsgSendType" BO_ 2612224098 1;
BA_ "GenMsgDelayTime" BO_ 2612224098 0;
BA_ "NetworkInitialization" BO_ 2612224098 0;
BA_ "TpTxIndex" BO_ 2609927384 462443736;
BA_ "GenMsgSendType" BO_ 2609927384 1;
BA_ "GenMsgDelayTime" BO_ 2609927384 0;
BA_ "NetworkInitialization" BO_ 2609927384 0;
BA_ "TpTxIndex" BO_ 2610126869 462443736;
BA_ "GenMsgSendType" BO_ 2610126869 1;
BA_ "GenMsgDelayTime" BO_ 2610126869 0;
BA_ "NetworkInitialization" BO_ 2610126869 0;
BA_ "TpTxIndex" BO_ 2609976536 462492888;
BA_ "GenMsgSendType" BO_ 2609976536 1;
BA_ "GenMsgDelayTime" BO_ 2609976536 0;
BA_ "NetworkInitialization" BO_ 2609976536 0;
BA_ "TpTxIndex" BO_ 2610126917 462492888;
BA_ "GenMsgSendType" BO_ 2610126917 1;
BA_ "GenMsgDelayTime" BO_ 2610126917 0;
BA_ "NetworkInitialization" BO_ 2610126917 0;
BA_ "TpTxIndex" BO_ 2609977560 462493912;
BA_ "GenMsgSendType" BO_ 2609977560 1;
BA_ "GenMsgDelayTime" BO_ 2609977560 0;
BA_ "NetworkInitialization" BO_ 2609977560 0;
BA_ "TpTxIndex" BO_ 2610126918 462493912;
BA_ "GenMsgSendType" BO_ 2610126918 1;
BA_ "GenMsgDelayTime" BO_ 2610126918 0;
BA_ "NetworkInitialization" BO_ 2610126918 0;
BA_ "TpTxIndex" BO_ 2610007256 462523608;
BA_ "GenMsgSendType" BO_ 2610007256 1;
BA_ "GenMsgDelayTime" BO_ 2610007256 0;
BA_ "NetworkInitialization" BO_ 2610007256 0;
BA_ "TpTxIndex" BO_ 2610126947 462523608;
BA_ "GenMsgSendType" BO_ 2610126947 1;
BA_ "GenMsgDelayTime" BO_ 2610126947 0;
BA_ "NetworkInitialization" BO_ 2610126947 0;
BA_ "TpTxIndex" BO_ 2612224017 464536792;
BA_ "OvtpPushApplication" BO_ 2612224017 1;
BA_ "GenMsgSendType" BO_ 2612224017 1;
BA_ "GenMsgDelayTime" BO_ 2612224017 0;
BA_ "NetworkInitialization" BO_ 2612224017 0;
BA_ "GenMsgSendType" BO_ 981 0;
BA_ "GenMsgCycleTime" BO_ 981 20;
BA_ "GenMsgDelayTime" BO_ 981 10;
BA_ "VFrameFormat" BO_ 981 14;
BA_ "GenMsgSendType" BO_ 810 5;
BA_ "GenMsgCycleTime" BO_ 810 1000;
BA_ "VFrameFormat" BO_ 810 14;
BA_ "GenMsgSendType" BO_ 563 5;
BA_ "GenMsgCycleTime" BO_ 563 1000;
BA_ "VFrameFormat" BO_ 563 14;
BA_ "TpTxIndex" BO_ 2609923288 462439640;
BA_ "GenMsgSendType" BO_ 2609923288 1;
BA_ "GenMsgDelayTime" BO_ 2609923288 0;
BA_ "NetworkInitialization" BO_ 2609923288 0;
BA_ "GenSigSendType" SG_ 785 VehPerfDemo_D_Stat 3;
BA_ "GenSigSendType" SG_ 785 VehVLimMsgTxt_B_Rq 3;
BA_ "GenSigSendType" SG_ 785 BattElecPerf_D2_Actl 3;
BA_ "GenSigSendType" SG_ 785 RgenAnimation_B_Dsply 3;
BA_ "GenSigSendType" SG_ 785 BattTracLimPerf_D_Dsply 3;
BA_ "GenSigSendType" SG_ 785 EcoIdl_D_Stat 3;
BA_ "GenSigStartValue" SG_ 785 DteVehOffst_L_Dsply 8190;
BA_ "GenSigSendType" SG_ 785 DteVehOffstMsgTxt_D_Rq 3;
BA_ "GenSigSendType" SG_ 785 PwPckTqRdyChime_B_Rq 3;
BA_ "U_CDX706_MY2023_Tx" SG_ 785 PwPckTqRdyChime_B_Rq 1;
BA_ "GenSigSendType" SG_ 785 BattTracLoThres_D_Stat 3;
BA_ "ECGUsedRxSignal" SG_ 785 BattTracLoThres_D_Stat 1;
BA_ "U_CD542_MY2021_Rx" SG_ 785 BattTracLoThres_D_Stat 1;
BA_ "U_U55X_MY2022_Rx" SG_ 785 BattTracLoThres_D_Stat 1;
BA_ "U_CDX706_MY2023_Rx" SG_ 785 BattTracLoThres_D_Stat 1;
BA_ "GenSigSendType" SG_ 785 BattTracLoMsgTxt_D_Rq 3;
BA_ "GenSigSendType" SG_ 785 DestSocRqd_Pc_Dsply 3;
BA_ "ECGUsedRxSignal" SG_ 785 DestSocRqd_Pc_Dsply 1;
BA_ "U_CD542_MY2021_Rx" SG_ 785 DestSocRqd_Pc_Dsply 1;
BA_ "U_U55X_MY2022_Rx" SG_ 785 DestSocRqd_Pc_Dsply 1;
BA_ "U_CDX706_MY2023_Rx" SG_ 785 DestSocRqd_Pc_Dsply 1;
BA_ "GenSigSendType" SG_ 785 DestChrgEndMin_No_Actl 3;
BA_ "ECGUsedRxSignal" SG_ 785 DestChrgEndMin_No_Actl 1;
BA_ "U_CD542_MY2021_Rx" SG_ 785 DestChrgEndMin_No_Actl 1;
BA_ "U_U55X_MY2022_Rx" SG_ 785 DestChrgEndMin_No_Actl 1;
BA_ "U_CDX706_MY2023_Rx" SG_ 785 DestChrgEndMin_No_Actl 1;
BA_ "GenSigSendType" SG_ 785 DestChrgEndHr_No_Actl 3;
BA_ "ECGUsedRxSignal" SG_ 785 DestChrgEndHr_No_Actl 1;
BA_ "U_CD542_MY2021_Rx" SG_ 785 DestChrgEndHr_No_Actl 1;
BA_ "U_U55X_MY2022_Rx" SG_ 785 DestChrgEndHr_No_Actl 1;
BA_ "U_CDX706_MY2023_Rx" SG_ 785 DestChrgEndHr_No_Actl 1;
BA_ "GenSigSendType" SG_ 785 DestChrgEndDay_No_Actl 3;
BA_ "GenSigStartValue" SG_ 785 DestChrgEndDay_No_Actl 1;
BA_ "ECGUsedRxSignal" SG_ 785 DestChrgEndDay_No_Actl 1;
BA_ "U_CD542_MY2021_Rx" SG_ 785 DestChrgEndDay_No_Actl 1;
BA_ "U_U55X_MY2022_Rx" SG_ 785 DestChrgEndDay_No_Actl 1;
BA_ "U_CDX706_MY2023_Rx" SG_ 785 DestChrgEndDay_No_Actl 1;
BA_ "GenSigSendType" SG_ 785 BattTracLoSoc_D_Dsply 3;
BA_ "ECGUsedRxSignal" SG_ 785 BattTracLoSoc_D_Dsply 1;
BA_ "U_CD542_MY2021_Rx" SG_ 785 BattTracLoSoc_D_Dsply 1;
BA_ "U_U55X_MY2022_Rx" SG_ 785 BattTracLoSoc_D_Dsply 1;
BA_ "U_CDX706_MY2023_Rx" SG_ 785 BattTracLoSoc_D_Dsply 1;
BA_ "GenSigSendType" SG_ 770 BattTracVrtOck_B_Stat 3;
BA_ "GenSigSendType" SG_ 770 ChrgTrgtSocOvrrd_B_Stat 3;
BA_ "ECGUsedRxSignal" SG_ 770 ChrgTrgtSocOvrrd_B_Stat 1;
BA_ "GenSigSendType" SG_ 770 ScMnSoc_Pc_Actl 3;
BA_ "GenSigStartValue" SG_ 770 ScMnSoc_Pc_Actl 100;
BA_ "ECGUsedRxSignal" SG_ 770 ScMnSoc_Pc_Actl 1;
BA_ "U_CD542_MY2021_Rx" SG_ 770 ScMnSoc_Pc_Actl 1;
BA_ "U_U55X_MY2022_Rx" SG_ 770 ScMnSoc_Pc_Actl 1;
BA_ "GenSigSendType" SG_ 770 CurntTrgtSoc_Pc_Rq 3;
BA_ "GenSigStartValue" SG_ 770 CurntTrgtSoc_Pc_Rq 100;
BA_ "GenSigSendType" SG_ 770 FstChrgBulk_T_Est 3;
BA_ "ECGUsedRxSignal" SG_ 770 FstChrgBulk_T_Est 1;
BA_ "U_CD542_MY2021_Rx" SG_ 770 FstChrgBulk_T_Est 1;
BA_ "U_U55X_MY2022_Rx" SG_ 770 FstChrgBulk_T_Est 1;
BA_ "GenSigSendType" SG_ 770 CurntTrgtSoc_Pc_Dsply 3;
BA_ "GenSigStartValue" SG_ 770 CurntTrgtSoc_Pc_Dsply 100;
BA_ "ECGUsedRxSignal" SG_ 770 CurntTrgtSoc_Pc_Dsply 1;
BA_ "U_CD542_MY2021_Rx" SG_ 770 CurntTrgtSoc_Pc_Dsply 1;
BA_ "U_U55X_MY2022_Rx" SG_ 770 CurntTrgtSoc_Pc_Dsply 1;
BA_ "GenSigSendType" SG_ 770 ScPayloadUpdate_B_Stat 3;
BA_ "ECGUsedRxSignal" SG_ 770 ScPayloadUpdate_B_Stat 1;
BA_ "U_CD542_MY2021_Rx" SG_ 770 ScPayloadUpdate_B_Stat 1;
BA_ "U_U55X_MY2022_Rx" SG_ 770 ScPayloadUpdate_B_Stat 1;
BA_ "GenSigSendType" SG_ 770 ScLocPwId_No_Stat 3;
BA_ "ECGUsedRxSignal" SG_ 770 ScLocPwId_No_Stat 1;
BA_ "U_CD542_MY2021_Rx" SG_ 770 ScLocPwId_No_Stat 1;
BA_ "U_U55X_MY2022_Rx" SG_ 770 ScLocPwId_No_Stat 1;
BA_ "ECGUsedRxSignal" SG_ 770 ScChrgrPwMax_Pw_Actl 1;
BA_ "U_CD542_MY2021_Rx" SG_ 770 ScChrgrPwMax_Pw_Actl 1;
BA_ "U_U55X_MY2022_Rx" SG_ 770 ScChrgrPwMax_Pw_Actl 1;
BA_ "GenSigSendType" SG_ 770 ScLocIdCurnt_No_Stat 3;
BA_ "ECGUsedRxSignal" SG_ 770 ScLocIdCurnt_No_Stat 1;
BA_ "U_CD542_MY2021_Rx" SG_ 770 ScLocIdCurnt_No_Stat 1;
BA_ "U_U55X_MY2022_Rx" SG_ 770 ScLocIdCurnt_No_Stat 1;
BA_ "GenSigSendType" SG_ 770 ScEnbl_B_Stat 3;
BA_ "ECGUsedRxSignal" SG_ 770 ScEnbl_B_Stat 1;
BA_ "U_CD542_MY2021_Rx" SG_ 770 ScEnbl_B_Stat 1;
BA_ "U_U55X_MY2022_Rx" SG_ 770 ScEnbl_B_Stat 1;
BA_ "GenSigSendType" SG_ 1205 CstmDrvMdeCfg2_B_Avail 3;
BA_ "U_CDX706_MY2023_Tx" SG_ 1205 CstmDrvMdeCfg2_B_Avail 1;
BA_ "GenSigSendType" SG_ 1205 CstmDrvMdeCfg1_B_Avail 3;
BA_ "U_CDX706_MY2023_Tx" SG_ 1205 CstmDrvMdeCfg1_B_Avail 1;
BA_ "GenSigSendType" SG_ 1205 CstmDrvMde_No_Confg2 3;
BA_ "GenSigStartValue" SG_ 1205 CstmDrvMde_No_Confg2 63;
BA_ "U_CDX706_MY2023_Tx" SG_ 1205 CstmDrvMde_No_Confg2 1;
BA_ "GenSigSendType" SG_ 1205 CstmDrvMde_No_Confg1 3;
BA_ "GenSigStartValue" SG_ 1205 CstmDrvMde_No_Confg1 63;
BA_ "U_CDX706_MY2023_Tx" SG_ 1205 CstmDrvMde_No_Confg1 1;
BA_ "GenSigSendType" SG_ 1205 CstmDrvMde_No_Confg 3;
BA_ "U_CDX706_MY2023_Tx" SG_ 1205 CstmDrvMde_No_Confg 1;
BA_ "GenSigSendType" SG_ 1205 CstmDrvMde5_No_Confg2 3;
BA_ "GenSigStartValue" SG_ 1205 CstmDrvMde5_No_Confg2 15;
BA_ "U_CDX706_MY2023_Tx" SG_ 1205 CstmDrvMde5_No_Confg2 1;
BA_ "GenSigSendType" SG_ 1205 CstmDrvMde5_No_Confg1 3;
BA_ "GenSigStartValue" SG_ 1205 CstmDrvMde5_No_Confg1 15;
BA_ "U_CDX706_MY2023_Tx" SG_ 1205 CstmDrvMde5_No_Confg1 1;
BA_ "GenSigSendType" SG_ 1205 CstmDrvMde4_No_Confg2 3;
BA_ "GenSigStartValue" SG_ 1205 CstmDrvMde4_No_Confg2 15;
BA_ "U_CDX706_MY2023_Tx" SG_ 1205 CstmDrvMde4_No_Confg2 1;
BA_ "GenSigSendType" SG_ 1205 CstmDrvMde4_No_Confg1 3;
BA_ "GenSigStartValue" SG_ 1205 CstmDrvMde4_No_Confg1 15;
BA_ "U_CDX706_MY2023_Tx" SG_ 1205 CstmDrvMde4_No_Confg1 1;
BA_ "GenSigSendType" SG_ 1205 CstmDrvMde3_No_Confg2 3;
BA_ "GenSigStartValue" SG_ 1205 CstmDrvMde3_No_Confg2 15;
BA_ "U_CDX706_MY2023_Tx" SG_ 1205 CstmDrvMde3_No_Confg2 1;
BA_ "GenSigSendType" SG_ 1205 CstmDrvMde3_No_Confg1 3;
BA_ "GenSigStartValue" SG_ 1205 CstmDrvMde3_No_Confg1 15;
BA_ "U_CDX706_MY2023_Tx" SG_ 1205 CstmDrvMde3_No_Confg1 1;
BA_ "GenSigSendType" SG_ 1205 CstmDrvMde2_No_Confg2 3;
BA_ "GenSigStartValue" SG_ 1205 CstmDrvMde2_No_Confg2 15;
BA_ "U_CDX706_MY2023_Tx" SG_ 1205 CstmDrvMde2_No_Confg2 1;
BA_ "GenSigSendType" SG_ 1205 CstmDrvMde2_No_Confg1 3;
BA_ "GenSigStartValue" SG_ 1205 CstmDrvMde2_No_Confg1 15;
BA_ "U_CDX706_MY2023_Tx" SG_ 1205 CstmDrvMde2_No_Confg1 1;
BA_ "GenSigSendType" SG_ 1205 CstmDrvMde1_No_Confg2 3;
BA_ "GenSigStartValue" SG_ 1205 CstmDrvMde1_No_Confg2 15;
BA_ "U_CDX706_MY2023_Tx" SG_ 1205 CstmDrvMde1_No_Confg2 1;
BA_ "GenSigSendType" SG_ 1205 CstmDrvMde1_No_Confg1 3;
BA_ "GenSigStartValue" SG_ 1205 CstmDrvMde1_No_Confg1 15;
BA_ "U_CDX706_MY2023_Tx" SG_ 1205 CstmDrvMde1_No_Confg1 1;
BA_ "GenSigSendType" SG_ 942 ApaOffOptnSel_B_Avail 3;
BA_ "GenSigStartValue" SG_ 942 ApaOffOptnSel_B_Avail 1;
BA_ "U_U55X_MY2022_Tx" SG_ 942 ApaOffOptnSel_B_Avail 1;
BA_ "U_CDX706_MY2023_Tx" SG_ 942 ApaOffOptnSel_B_Avail 1;
BA_ "GenSigSendType" SG_ 942 PrkBrkElRleas_B_RqApa 3;
BA_ "U_CD764_MY2022_Tx" SG_ 942 PrkBrkElRleas_B_RqApa 1;
BA_ "U_CDX706_MY2023_Tx" SG_ 942 PrkBrkElRleas_B_RqApa 1;
BA_ "GenSigSendType" SG_ 942 ApaDrvRq2MsgTxt_D_Rq 3;
BA_ "U_U55X_MY2022_Tx" SG_ 942 ApaDrvRq2MsgTxt_D_Rq 1;
BA_ "U_CDX706_MY2023_Tx" SG_ 942 ApaDrvRq2MsgTxt_D_Rq 1;
BA_ "GenSigSendType" SG_ 942 ApaDrvRq1MsgTxt_D_Rq 3;
BA_ "U_U55X_MY2022_Tx" SG_ 942 ApaDrvRq1MsgTxt_D_Rq 1;
BA_ "U_CDX706_MY2023_Tx" SG_ 942 ApaDrvRq1MsgTxt_D_Rq 1;
BA_ "GenSigSendType" SG_ 942 ApaSys_D2_Stat 3;
BA_ "U_U55X_MY2022_Tx" SG_ 942 ApaSys_D2_Stat 1;
BA_ "U_CDX706_MY2023_Tx" SG_ 942 ApaSys_D2_Stat 1;
BA_ "GenSigSendType" SG_ 942 ApaSlotTrgt_D_Stat 3;
BA_ "U_U55X_MY2022_Tx" SG_ 942 ApaSlotTrgt_D_Stat 1;
BA_ "U_CDX706_MY2023_Tx" SG_ 942 ApaSlotTrgt_D_Stat 1;
BA_ "GenSigSendType" SG_ 942 ApaSlotOption_B_Avail 3;
BA_ "U_U55X_MY2022_Tx" SG_ 942 ApaSlotOption_B_Avail 1;
BA_ "U_CDX706_MY2023_Tx" SG_ 942 ApaSlotOption_B_Avail 1;
BA_ "GenSigSendType" SG_ 942 ApaSlotAlrtSet_B_Stat 3;
BA_ "U_U55X_MY2022_Tx" SG_ 942 ApaSlotAlrtSet_B_Stat 1;
BA_ "U_CDX706_MY2023_Tx" SG_ 942 ApaSlotAlrtSet_B_Stat 1;
BA_ "GenSigSendType" SG_ 942 ApaSlotAlrt_B_Rq 3;
BA_ "U_U55X_MY2022_Tx" SG_ 942 ApaSlotAlrt_B_Rq 1;
BA_ "U_CDX706_MY2023_Tx" SG_ 942 ApaSlotAlrt_B_Rq 1;
BA_ "GenSigSendType" SG_ 942 ApaRmtFeatSel_B_Avail 3;
BA_ "U_U55X_MY2022_Tx" SG_ 942 ApaRmtFeatSel_B_Avail 1;
BA_ "U_CDX706_MY2023_Tx" SG_ 942 ApaRmtFeatSel_B_Avail 1;
BA_ "GenSigSendType" SG_ 942 ApaParkOutSel_B_Avail 3;
BA_ "U_U55X_MY2022_Tx" SG_ 942 ApaParkOutSel_B_Avail 1;
BA_ "U_CDX706_MY2023_Tx" SG_ 942 ApaParkOutSel_B_Avail 1;
BA_ "GenSigSendType" SG_ 942 ApaParkInSel_B_Avail 3;
BA_ "U_U55X_MY2022_Tx" SG_ 942 ApaParkInSel_B_Avail 1;
BA_ "U_CDX706_MY2023_Tx" SG_ 942 ApaParkInSel_B_Avail 1;
BA_ "GenSigSendType" SG_ 942 ApaMsgTxt_D2_Stat 3;
BA_ "U_U55X_MY2022_Tx" SG_ 942 ApaMsgTxt_D2_Stat 1;
BA_ "U_CDX706_MY2023_Tx" SG_ 942 ApaMsgTxt_D2_Stat 1;
BA_ "GenSigSendType" SG_ 942 ApaDynmcSlot_B_Stat 3;
BA_ "U_U55X_MY2022_Tx" SG_ 942 ApaDynmcSlot_B_Stat 1;
BA_ "U_CDX706_MY2023_Tx" SG_ 942 ApaDynmcSlot_B_Stat 1;
BA_ "GenSigSendType" SG_ 942 ApaDisplayMode_D_Stat 3;
BA_ "U_U55X_MY2022_Tx" SG_ 942 ApaDisplayMode_D_Stat 1;
BA_ "U_CDX706_MY2023_Tx" SG_ 942 ApaDisplayMode_D_Stat 1;
BA_ "GenSigSendType" SG_ 942 ApaControlMode_D_Stat 3;
BA_ "U_U55X_MY2022_Tx" SG_ 942 ApaControlMode_D_Stat 1;
BA_ "U_CDX706_MY2023_Tx" SG_ 942 ApaControlMode_D_Stat 1;
BA_ "GenSigSendType" SG_ 942 PrkAidAcsyRear_D_Stat 3;
BA_ "U_T6_MCA_MY2020_Tx" SG_ 942 PrkAidAcsyRear_D_Stat 1;
BA_ "U_U55X_MY2022_Tx" SG_ 942 PrkAidAcsyRear_D_Stat 1;
BA_ "U_CD764_MY2022_Tx" SG_ 942 PrkAidAcsyRear_D_Stat 1;
BA_ "U_CDX706_MY2023_Tx" SG_ 942 PrkAidAcsyRear_D_Stat 1;
BA_ "GenSigSendType" SG_ 942 PrkAidAcsyFront_D_Stat 3;
BA_ "U_T6_MCA_MY2020_Tx" SG_ 942 PrkAidAcsyFront_D_Stat 1;
BA_ "U_U55X_MY2022_Tx" SG_ 942 PrkAidAcsyFront_D_Stat 1;
BA_ "U_CDX706_MY2023_Tx" SG_ 942 PrkAidAcsyFront_D_Stat 1;
BA_ "GenSigSendType" SG_ 942 PrkAidRdiusRight_L_Dsply 3;
BA_ "U_T6_MCA_MY2020_Tx" SG_ 942 PrkAidRdiusRight_L_Dsply 1;
BA_ "U_U55X_MY2022_Tx" SG_ 942 PrkAidRdiusRight_L_Dsply 1;
BA_ "U_CD764_MY2022_Tx" SG_ 942 PrkAidRdiusRight_L_Dsply 1;
BA_ "U_CDX706_MY2023_Tx" SG_ 942 PrkAidRdiusRight_L_Dsply 1;
BA_ "GenSigSendType" SG_ 942 PrkAidRdiusLeft_L_Dsply 3;
BA_ "U_T6_MCA_MY2020_Tx" SG_ 942 PrkAidRdiusLeft_L_Dsply 1;
BA_ "U_U55X_MY2022_Tx" SG_ 942 PrkAidRdiusLeft_L_Dsply 1;
BA_ "U_CD764_MY2022_Tx" SG_ 942 PrkAidRdiusLeft_L_Dsply 1;
BA_ "U_CDX706_MY2023_Tx" SG_ 942 PrkAidRdiusLeft_L_Dsply 1;
BA_ "GenSigSendType" SG_ 942 PrkAidDrvDir_D_Stat 3;
BA_ "U_T6_MCA_MY2020_Tx" SG_ 942 PrkAidDrvDir_D_Stat 1;
BA_ "U_U55X_MY2022_Tx" SG_ 942 PrkAidDrvDir_D_Stat 1;
BA_ "U_CD764_MY2022_Tx" SG_ 942 PrkAidDrvDir_D_Stat 1;
BA_ "U_CDX706_MY2023_Tx" SG_ 942 PrkAidDrvDir_D_Stat 1;
BA_ "GenSigStartValueInteger" SG_ 123 BattTrac_U2_Actl 1022;
BA_ "GenSigStartValue" SG_ 123 BattTrac_U2_Actl 4094;
BA_ "U_CDX706_MY2023_Rx" SG_ 123 BattTrac_U2_Actl 1;
BA_ "GenSigStartValueInteger" SG_ 123 BattTrac_I2_Actl 15000;
BA_ "GenSigStartValue" SG_ 123 BattTrac_I2_Actl 262142;
BA_ "U_CDX706_MY2023_Rx" SG_ 123 BattTrac_I2_Actl 1;
BA_ "GenSigSendType" SG_ 2612052184 PARSEDPushFcGWM_ECGtoPSCM 3;
BA_ "U_CD542_MY2021_Rx" SG_ 2612052184 PARSEDPushFcGWM_ECGtoPSCM 1;
BA_ "U_U55X_MY2022_Rx" SG_ 2612052184 PARSEDPushFcGWM_ECGtoPSCM 1;
BA_ "U_CD764_MY2022_Rx" SG_ 2612052184 PARSEDPushFcGWM_ECGtoPSCM 1;
BA_ "U_CDX706_MY2023_Rx" SG_ 2612052184 PARSEDPushFcGWM_ECGtoPSCM 1;
BA_ "ECGUsedTxSignal" SG_ 2612052184 PARSEDPushFcGWM_ECGtoPSCM 1;
BA_ "U_CD542_MY2021_Tx" SG_ 2612052184 PARSEDPushFcGWM_ECGtoPSCM 1;
BA_ "U_U55X_MY2022_Tx" SG_ 2612052184 PARSEDPushFcGWM_ECGtoPSCM 1;
BA_ "U_CD764_MY2022_Tx" SG_ 2612052184 PARSEDPushFcGWM_ECGtoPSCM 1;
BA_ "U_CDX706_MY2023_Tx" SG_ 2612052184 PARSEDPushFcGWM_ECGtoPSCM 1;
BA_ "GenSigSendType" SG_ 2612224187 PARSEDPushCMRtoGWM_ECG 3;
BA_ "U_T6_MCA_MY2020_Rx" SG_ 2612224187 PARSEDPushCMRtoGWM_ECG 1;
BA_ "ECGUsedRxSignal" SG_ 2612224187 PARSEDPushCMRtoGWM_ECG 1;
BA_ "U_CD542_MY2021_Rx" SG_ 2612224187 PARSEDPushCMRtoGWM_ECG 1;
BA_ "U_U55X_MY2022_Rx" SG_ 2612224187 PARSEDPushCMRtoGWM_ECG 1;
BA_ "U_CDX706_MY2023_Rx" SG_ 2612224187 PARSEDPushCMRtoGWM_ECG 1;
BA_ "U_T6_MCA_MY2020_Tx" SG_ 2612224187 PARSEDPushCMRtoGWM_ECG 1;
BA_ "U_CD542_MY2021_Tx" SG_ 2612224187 PARSEDPushCMRtoGWM_ECG 1;
BA_ "U_U55X_MY2022_Tx" SG_ 2612224187 PARSEDPushCMRtoGWM_ECG 1;
BA_ "U_CD764_MY2022_Tx" SG_ 2612224187 PARSEDPushCMRtoGWM_ECG 1;
BA_ "U_CDX706_MY2023_Tx" SG_ 2612224187 PARSEDPushCMRtoGWM_ECG 1;
BA_ "GenSigSendType" SG_ 1201 FrontDiffLck_D_RqDrv2 3;
BA_ "GenSigStartValueInteger" SG_ 1201 FrontDiffLck_D_RqDrv2 2;
BA_ "GenSigStartValue" SG_ 1201 FrontDiffLck_D_RqDrv2 2;
BA_ "U_T6_MCA_MY2020_Tx" SG_ 1201 FrontDiffLck_D_RqDrv2 1;
BA_ "GenSigSendType" SG_ 1201 RearDiffLck_D_RqDrv2 3;
BA_ "GenSigStartValueInteger" SG_ 1201 RearDiffLck_D_RqDrv2 2;
BA_ "GenSigStartValue" SG_ 1201 RearDiffLck_D_RqDrv2 2;
BA_ "U_T6_MCA_MY2020_Tx" SG_ 1201 RearDiffLck_D_RqDrv2 1;
BA_ "GenSigSendType" SG_ 1201 DrvSlipCtlMde_B_Rq5 3;
BA_ "U_T6_MCA_MY2020_Tx" SG_ 1201 DrvSlipCtlMde_B_Rq5 1;
BA_ "GenSigSendType" SG_ 1201 StabBarCnncButtn_D_Sta2 3;
BA_ "U_T6_MCA_MY2020_Tx" SG_ 1201 StabBarCnncButtn_D_Sta2 1;
BA_ "GenSigSendType" SG_ 1201 OrtaSwtch_D_Stat 3;
BA_ "U_T6_MCA_MY2020_Rx" SG_ 1201 OrtaSwtch_D_Stat 1;
BA_ "U_T6_MCA_MY2020_Tx" SG_ 1201 OrtaSwtch_D_Stat 1;
BA_ "GenSigSendType" SG_ 1912 TesterPhysicalResSIMA 3;
BA_ "GenSigSendType" SG_ 1904 TesterPhysicalReqSIMA 3;
BA_ "GenSigStartValueInteger" SG_ 1527 SIMA_GWOnBoardTester 255;
BA_ "ContentDependant" SG_ 1527 SIMA_GWOnBoardTester 1;
BA_ "GenSigStartValue" SG_ 1527 SIMA_GWOnBoardTester 255;
BA_ "U_T6_MCA_MY2020_Tx" SG_ 1527 SIMA_GWOnBoardTester 1;
BA_ "GenSigStartValueInteger" SG_ 1527 SIMA_GWNMProxy 255;
BA_ "ContentDependant" SG_ 1527 SIMA_GWNMProxy 1;
BA_ "GenSigStartValue" SG_ 1527 SIMA_GWNMProxy 255;
BA_ "U_T6_MCA_MY2020_Tx" SG_ 1527 SIMA_GWNMProxy 1;
BA_ "GenSigStartValueInteger" SG_ 1527 SIMA_AutoSarNMReserved4 255;
BA_ "ContentDependant" SG_ 1527 SIMA_AutoSarNMReserved4 1;
BA_ "GenSigStartValue" SG_ 1527 SIMA_AutoSarNMReserved4 255;
BA_ "U_T6_MCA_MY2020_Tx" SG_ 1527 SIMA_AutoSarNMReserved4 1;
BA_ "GenSigStartValueInteger" SG_ 1527 SIMA_AutoSarNMReserved3 255;
BA_ "ContentDependant" SG_ 1527 SIMA_AutoSarNMReserved3 1;
BA_ "GenSigStartValue" SG_ 1527 SIMA_AutoSarNMReserved3 255;
BA_ "U_T6_MCA_MY2020_Tx" SG_ 1527 SIMA_AutoSarNMReserved3 1;
BA_ "GenSigStartValueInteger" SG_ 1527 SIMA_AutoSarNMReserved2 255;
BA_ "ContentDependant" SG_ 1527 SIMA_AutoSarNMReserved2 1;
BA_ "GenSigStartValue" SG_ 1527 SIMA_AutoSarNMReserved2 255;
BA_ "U_T6_MCA_MY2020_Tx" SG_ 1527 SIMA_AutoSarNMReserved2 1;
BA_ "GenSigStartValueInteger" SG_ 1527 SIMA_AutoSarNMReserved1 255;
BA_ "ContentDependant" SG_ 1527 SIMA_AutoSarNMReserved1 1;
BA_ "GenSigStartValue" SG_ 1527 SIMA_AutoSarNMReserved1 255;
BA_ "U_T6_MCA_MY2020_Tx" SG_ 1527 SIMA_AutoSarNMReserved1 1;
BA_ "GenSigStartValueInteger" SG_ 1527 SIMA_AutoSarNMNodeId 166;
BA_ "ContentDependant" SG_ 1527 SIMA_AutoSarNMNodeId 1;
BA_ "GenSigStartValue" SG_ 1527 SIMA_AutoSarNMNodeId 247;
BA_ "U_T6_MCA_MY2020_Tx" SG_ 1527 SIMA_AutoSarNMNodeId 1;
BA_ "ContentDependant" SG_ 1527 SIMA_AutoSarNMControl 1;
BA_ "U_T6_MCA_MY2020_Tx" SG_ 1527 SIMA_AutoSarNMControl 1;
BA_ "GenSigSendType" SG_ 1239 SelDrvMdeGzg_D_Rq 3;
BA_ "GenSigStartValueInteger" SG_ 1239 SelDrvMdeGzg_D_Rq 31;
BA_ "GenSigStartValue" SG_ 1239 SelDrvMdeGzg_D_Rq 31;
BA_ "U_CDX706_MY2023_Rx" SG_ 1239 SelDrvMdeGzg_D_Rq 1;
BA_ "ECGUsedTxSignal" SG_ 1239 SelDrvMdeGzg_D_Rq 1;
BA_ "U_CDX706_MY2023_Tx" SG_ 1239 SelDrvMdeGzg_D_Rq 1;
BA_ "GenSigSendType" SG_ 1239 CstmDrvMdeTracCtl_D_Rq 3;
BA_ "ECGUsedTxSignal" SG_ 1239 CstmDrvMdeTracCtl_D_Rq 1;
BA_ "U_CDX706_MY2023_Tx" SG_ 1239 CstmDrvMdeTracCtl_D_Rq 1;
BA_ "GenSigSendType" SG_ 1239 CstmDrvMdeChassis_D_Rq 3;
BA_ "U_CDX706_MY2023_Rx" SG_ 1239 CstmDrvMdeChassis_D_Rq 1;
BA_ "ECGUsedTxSignal" SG_ 1239 CstmDrvMdeChassis_D_Rq 1;
BA_ "U_CDX706_MY2023_Tx" SG_ 1239 CstmDrvMdeChassis_D_Rq 1;
BA_ "GenSigSendType" SG_ 1239 CstmDrvMdeHmi2_D_Rq 3;
BA_ "GenSigStartValueInteger" SG_ 1239 CstmDrvMdeHmi2_D_Rq 31;
BA_ "GenSigStartValue" SG_ 1239 CstmDrvMdeHmi2_D_Rq 31;
BA_ "ECGUsedTxSignal" SG_ 1239 CstmDrvMdeHmi2_D_Rq 1;
BA_ "U_CDX706_MY2023_Tx" SG_ 1239 CstmDrvMdeHmi2_D_Rq 1;
BA_ "GenSigSendType" SG_ 1239 SelDrvMdeCstmLamp_D_Rq 3;
BA_ "ECGUsedTxSignal" SG_ 1239 SelDrvMdeCstmLamp_D_Rq 1;
BA_ "U_CD542_MY2021_Tx" SG_ 1239 SelDrvMdeCstmLamp_D_Rq 1;
BA_ "U_CD764_MY2022_Tx" SG_ 1239 SelDrvMdeCstmLamp_D_Rq 1;
BA_ "U_CDX706_MY2023_Tx" SG_ 1239 SelDrvMdeCstmLamp_D_Rq 1;
BA_ "GenSigSendType" SG_ 1239 SelDrvMdeCstm_D_RqDrv 3;
BA_ "U_CDX706_MY2023_Rx" SG_ 1239 SelDrvMdeCstm_D_RqDrv 1;
BA_ "ECGUsedTxSignal" SG_ 1239 SelDrvMdeCstm_D_RqDrv 1;
BA_ "U_CD542_MY2021_Tx" SG_ 1239 SelDrvMdeCstm_D_RqDrv 1;
BA_ "U_CD764_MY2022_Tx" SG_ 1239 SelDrvMdeCstm_D_RqDrv 1;
BA_ "U_CDX706_MY2023_Tx" SG_ 1239 SelDrvMdeCstm_D_RqDrv 1;
BA_ "GenSigSendType" SG_ 1239 StabBarCnnctLamp_D_Cstm 3;
BA_ "ECGUsedTxSignal" SG_ 1239 StabBarCnnctLamp_D_Cstm 1;
BA_ "U_CD542_MY2021_Tx" SG_ 1239 StabBarCnnctLamp_D_Cstm 1;
BA_ "U_CD764_MY2022_Tx" SG_ 1239 StabBarCnnctLamp_D_Cstm 1;
BA_ "U_CDX706_MY2023_Tx" SG_ 1239 StabBarCnnctLamp_D_Cstm 1;
BA_ "GenSigSendType" SG_ 1239 IndvMdeSuspCstm_No_Rq 3;
BA_ "GenSigStartValue" SG_ 1239 IndvMdeSuspCstm_No_Rq 15;
BA_ "U_CDX706_MY2023_Rx" SG_ 1239 IndvMdeSuspCstm_No_Rq 1;
BA_ "ECGUsedTxSignal" SG_ 1239 IndvMdeSuspCstm_No_Rq 1;
BA_ "U_CD542_MY2021_Tx" SG_ 1239 IndvMdeSuspCstm_No_Rq 1;
BA_ "U_CD764_MY2022_Tx" SG_ 1239 IndvMdeSuspCstm_No_Rq 1;
BA_ "U_CDX706_MY2023_Tx" SG_ 1239 IndvMdeSuspCstm_No_Rq 1;
BA_ "GenSigSendType" SG_ 1239 IndvMdeSteCstm_No_Rq 3;
BA_ "GenSigStartValue" SG_ 1239 IndvMdeSteCstm_No_Rq 15;
BA_ "U_CDX706_MY2023_Rx" SG_ 1239 IndvMdeSteCstm_No_Rq 1;
BA_ "ECGUsedTxSignal" SG_ 1239 IndvMdeSteCstm_No_Rq 1;
BA_ "U_CD542_MY2021_Tx" SG_ 1239 IndvMdeSteCstm_No_Rq 1;
BA_ "U_CD764_MY2022_Tx" SG_ 1239 IndvMdeSteCstm_No_Rq 1;
BA_ "U_CDX706_MY2023_Tx" SG_ 1239 IndvMdeSteCstm_No_Rq 1;
BA_ "GenSigSendType" SG_ 1239 CstmDrvMdeMsgTxt_D_Rq 3;
BA_ "ECGUsedTxSignal" SG_ 1239 CstmDrvMdeMsgTxt_D_Rq 1;
BA_ "U_CD542_MY2021_Tx" SG_ 1239 CstmDrvMdeMsgTxt_D_Rq 1;
BA_ "U_CD764_MY2022_Tx" SG_ 1239 CstmDrvMdeMsgTxt_D_Rq 1;
BA_ "U_CDX706_MY2023_Tx" SG_ 1239 CstmDrvMdeMsgTxt_D_Rq 1;
BA_ "GenSigSendType" SG_ 1239 ActvDrvMdeCstm_D2_Rq 3;
BA_ "GenSigStartValue" SG_ 1239 ActvDrvMdeCstm_D2_Rq 31;
BA_ "U_CDX706_MY2023_Rx" SG_ 1239 ActvDrvMdeCstm_D2_Rq 1;
BA_ "ECGUsedTxSignal" SG_ 1239 ActvDrvMdeCstm_D2_Rq 1;
BA_ "U_CD542_MY2021_Tx" SG_ 1239 ActvDrvMdeCstm_D2_Rq 1;
BA_ "U_CD764_MY2022_Tx" SG_ 1239 ActvDrvMdeCstm_D2_Rq 1;
BA_ "U_CDX706_MY2023_Tx" SG_ 1239 ActvDrvMdeCstm_D2_Rq 1;
BA_ "GenSigStartValueInteger" SG_ 949 Tire_Press_RR_ORR_Data 65533;
BA_ "GenSigStartValue" SG_ 949 Tire_Press_RR_ORR_Data 65533;
BA_ "U_T6_MCA_MY2020_Rx" SG_ 949 Tire_Press_RR_ORR_Data 1;
BA_ "GenSigStartValueInteger" SG_ 949 Tire_Press_LR_OLR_Data 65533;
BA_ "GenSigStartValue" SG_ 949 Tire_Press_LR_OLR_Data 65533;
BA_ "U_T6_MCA_MY2020_Rx" SG_ 949 Tire_Press_LR_OLR_Data 1;
BA_ "GenSigStartValueInteger" SG_ 949 Tire_Press_LF_Data 65533;
BA_ "GenSigStartValue" SG_ 949 Tire_Press_LF_Data 65533;
BA_ "U_T6_MCA_MY2020_Rx" SG_ 949 Tire_Press_LF_Data 1;
BA_ "GenSigStartValueInteger" SG_ 949 Tire_Press_RF_Data 65533;
BA_ "GenSigStartValue" SG_ 949 Tire_Press_RF_Data 65533;
BA_ "U_T6_MCA_MY2020_Rx" SG_ 949 Tire_Press_RF_Data 1;
BA_ "GenSigSendType" SG_ 2612118744 PARSEDPushFcGWM_ECGtoHCM 3;
BA_ "U_U55X_MY2022_Rx" SG_ 2612118744 PARSEDPushFcGWM_ECGtoHCM 1;
BA_ "U_CD764_MY2022_Rx" SG_ 2612118744 PARSEDPushFcGWM_ECGtoHCM 1;
BA_ "ECGUsedTxSignal" SG_ 2612118744 PARSEDPushFcGWM_ECGtoHCM 1;
BA_ "U_CD542_MY2021_Tx" SG_ 2612118744 PARSEDPushFcGWM_ECGtoHCM 1;
BA_ "U_U55X_MY2022_Tx" SG_ 2612118744 PARSEDPushFcGWM_ECGtoHCM 1;
BA_ "U_CD764_MY2022_Tx" SG_ 2612118744 PARSEDPushFcGWM_ECGtoHCM 1;
BA_ "U_CDX706_MY2023_Tx" SG_ 2612118744 PARSEDPushFcGWM_ECGtoHCM 1;
BA_ "GenSigSendType" SG_ 2612074712 PARSEDPushFcGWMtoSODCMD 3;
BA_ "U_T6_MCA_MY2020_Rx" SG_ 2612074712 PARSEDPushFcGWMtoSODCMD 1;
BA_ "U_U55X_MY2022_Rx" SG_ 2612074712 PARSEDPushFcGWMtoSODCMD 1;
BA_ "U_CDX706_MY2023_Rx" SG_ 2612074712 PARSEDPushFcGWMtoSODCMD 1;
BA_ "U_T6_MCA_MY2020_Tx" SG_ 2612074712 PARSEDPushFcGWMtoSODCMD 1;
BA_ "ECGUsedTxSignal" SG_ 2612074712 PARSEDPushFcGWMtoSODCMD 1;
BA_ "U_CD542_MY2021_Tx" SG_ 2612074712 PARSEDPushFcGWMtoSODCMD 1;
BA_ "U_U55X_MY2022_Tx" SG_ 2612074712 PARSEDPushFcGWMtoSODCMD 1;
BA_ "U_CDX706_MY2023_Tx" SG_ 2612074712 PARSEDPushFcGWMtoSODCMD 1;
BA_ "GenSigSendType" SG_ 2612024536 PARSEDPushFcGWM_ECGtoCCM 3;
BA_ "U_T6_MCA_MY2020_Rx" SG_ 2612024536 PARSEDPushFcGWM_ECGtoCCM 1;
BA_ "U_U55X_MY2022_Rx" SG_ 2612024536 PARSEDPushFcGWM_ECGtoCCM 1;
BA_ "U_CDX706_MY2023_Rx" SG_ 2612024536 PARSEDPushFcGWM_ECGtoCCM 1;
BA_ "U_T6_MCA_MY2020_Tx" SG_ 2612024536 PARSEDPushFcGWM_ECGtoCCM 1;
BA_ "ECGUsedTxSignal" SG_ 2612024536 PARSEDPushFcGWM_ECGtoCCM 1;
BA_ "U_CD542_MY2021_Tx" SG_ 2612024536 PARSEDPushFcGWM_ECGtoCCM 1;
BA_ "U_U55X_MY2022_Tx" SG_ 2612024536 PARSEDPushFcGWM_ECGtoCCM 1;
BA_ "U_CDX706_MY2023_Tx" SG_ 2612024536 PARSEDPushFcGWM_ECGtoCCM 1;
BA_ "GenSigSendType" SG_ 2612036824 PARSEDPushFcGWM_ECGtoIPMA 3;
BA_ "U_T6_MCA_MY2020_Rx" SG_ 2612036824 PARSEDPushFcGWM_ECGtoIPMA 1;
BA_ "U_U55X_MY2022_Rx" SG_ 2612036824 PARSEDPushFcGWM_ECGtoIPMA 1;
BA_ "U_CDX706_MY2023_Rx" SG_ 2612036824 PARSEDPushFcGWM_ECGtoIPMA 1;
BA_ "U_T6_MCA_MY2020_Tx" SG_ 2612036824 PARSEDPushFcGWM_ECGtoIPMA 1;
BA_ "ECGUsedTxSignal" SG_ 2612036824 PARSEDPushFcGWM_ECGtoIPMA 1;
BA_ "U_CD542_MY2021_Tx" SG_ 2612036824 PARSEDPushFcGWM_ECGtoIPMA 1;
BA_ "U_U55X_MY2022_Tx" SG_ 2612036824 PARSEDPushFcGWM_ECGtoIPMA 1;
BA_ "U_CD764_MY2022_Tx" SG_ 2612036824 PARSEDPushFcGWM_ECGtoIPMA 1;
BA_ "U_CDX706_MY2023_Tx" SG_ 2612036824 PARSEDPushFcGWM_ECGtoIPMA 1;
BA_ "GenSigSendType" SG_ 2612103384 PARSEDPushFcGWM_ECGtoSODL 3;
BA_ "U_T6_MCA_MY2020_Rx" SG_ 2612103384 PARSEDPushFcGWM_ECGtoSODL 1;
BA_ "U_U55X_MY2022_Rx" SG_ 2612103384 PARSEDPushFcGWM_ECGtoSODL 1;
BA_ "U_CDX706_MY2023_Rx" SG_ 2612103384 PARSEDPushFcGWM_ECGtoSODL 1;
BA_ "U_T6_MCA_MY2020_Tx" SG_ 2612103384 PARSEDPushFcGWM_ECGtoSODL 1;
BA_ "ECGUsedTxSignal" SG_ 2612103384 PARSEDPushFcGWM_ECGtoSODL 1;
BA_ "U_CD542_MY2021_Tx" SG_ 2612103384 PARSEDPushFcGWM_ECGtoSODL 1;
BA_ "U_U55X_MY2022_Tx" SG_ 2612103384 PARSEDPushFcGWM_ECGtoSODL 1;
BA_ "U_CDX706_MY2023_Tx" SG_ 2612103384 PARSEDPushFcGWM_ECGtoSODL 1;
BA_ "GenSigStartValue" SG_ 639 OfbTrgtSocOvrrd_Pc_Rq 100;
BA_ "ECGUsedTxSignal" SG_ 639 OfbTrgtSocOvrrd_Pc_Rq 1;
BA_ "GenSigSendType" SG_ 639 OfbTrgtSocOvrrd_D_Rq 3;
BA_ "ECGUsedTxSignal" SG_ 639 OfbTrgtSocOvrrd_D_Rq 1;
BA_ "GenSigSendType" SG_ 639 OfbChrgPrflUpdate_B_Rq 3;
BA_ "ECGUsedTxSignal" SG_ 639 OfbChrgPrflUpdate_B_Rq 1;
BA_ "U_CD542_MY2021_Tx" SG_ 639 OfbChrgPrflUpdate_B_Rq 1;
BA_ "U_U55X_MY2022_Tx" SG_ 639 OfbChrgPrflUpdate_B_Rq 1;
BA_ "GenSigSendType" SG_ 639 OfbChrgClearAll_B_Rq 3;
BA_ "ECGUsedTxSignal" SG_ 639 OfbChrgClearAll_B_Rq 1;
BA_ "U_CD542_MY2021_Tx" SG_ 639 OfbChrgClearAll_B_Rq 1;
BA_ "U_U55X_MY2022_Tx" SG_ 639 OfbChrgClearAll_B_Rq 1;
BA_ "GenSigSendType" SG_ 639 OfbChrgGoTTouch_D_Rq 3;
BA_ "ECGUsedTxSignal" SG_ 639 OfbChrgGoTTouch_D_Rq 1;
BA_ "U_CD542_MY2021_Tx" SG_ 639 OfbChrgGoTTouch_D_Rq 1;
BA_ "U_U55X_MY2022_Tx" SG_ 639 OfbChrgGoTTouch_D_Rq 1;
BA_ "ECGUsedTxSignal" SG_ 639 OfbChrgGoTPrcond_D_Rq 1;
BA_ "U_CD542_MY2021_Tx" SG_ 639 OfbChrgGoTPrcond_D_Rq 1;
BA_ "U_U55X_MY2022_Tx" SG_ 639 OfbChrgGoTPrcond_D_Rq 1;
BA_ "GenSigSendType" SG_ 639 OfbChrgGoTOn_D_Rq 3;
BA_ "GenSigStartValueInteger" SG_ 639 OfbChrgGoTOn_D_Rq 2;
BA_ "ECGUsedTxSignal" SG_ 639 OfbChrgGoTOn_D_Rq 1;
BA_ "U_CD542_MY2021_Tx" SG_ 639 OfbChrgGoTOn_D_Rq 1;
BA_ "U_U55X_MY2022_Tx" SG_ 639 OfbChrgGoTOn_D_Rq 1;
BA_ "ECGUsedTxSignal" SG_ 639 OfbChrgGoTMnte_D_Rq 1;
BA_ "U_CD542_MY2021_Tx" SG_ 639 OfbChrgGoTMnte_D_Rq 1;
BA_ "U_U55X_MY2022_Tx" SG_ 639 OfbChrgGoTMnte_D_Rq 1;
BA_ "GenSigStartValueInteger" SG_ 639 OfbChrgGoTHr_T_Rq 30;
BA_ "GenSigStartValue" SG_ 639 OfbChrgGoTHr_T_Rq 30;
BA_ "ECGUsedTxSignal" SG_ 639 OfbChrgGoTHr_T_Rq 1;
BA_ "U_CD542_MY2021_Tx" SG_ 639 OfbChrgGoTHr_T_Rq 1;
BA_ "U_U55X_MY2022_Tx" SG_ 639 OfbChrgGoTHr_T_Rq 1;
BA_ "GenSigSendType" SG_ 639 OfbChrgGoTExtHtr_D_Rq 3;
BA_ "ECGUsedTxSignal" SG_ 639 OfbChrgGoTExtHtr_D_Rq 1;
BA_ "U_CD542_MY2021_Tx" SG_ 639 OfbChrgGoTExtHtr_D_Rq 1;
BA_ "U_U55X_MY2022_Tx" SG_ 639 OfbChrgGoTExtHtr_D_Rq 1;
BA_ "GenSigSendType" SG_ 639 OfbChrgGoTElement_D_Rq 3;
BA_ "ECGUsedTxSignal" SG_ 639 OfbChrgGoTElement_D_Rq 1;
BA_ "U_CD542_MY2021_Tx" SG_ 639 OfbChrgGoTElement_D_Rq 1;
BA_ "U_U55X_MY2022_Tx" SG_ 639 OfbChrgGoTElement_D_Rq 1;
BA_ "ECGUsedTxSignal" SG_ 639 OfbChrgGoTDelete_B_Rq 1;
BA_ "U_CD542_MY2021_Tx" SG_ 639 OfbChrgGoTDelete_B_Rq 1;
BA_ "U_U55X_MY2022_Tx" SG_ 639 OfbChrgGoTDelete_B_Rq 1;
BA_ "GenSigSendType" SG_ 639 OfbChrgGoTUpdate_B_Rq 3;
BA_ "ECGUsedTxSignal" SG_ 639 OfbChrgGoTUpdate_B_Rq 1;
BA_ "U_CD542_MY2021_Tx" SG_ 639 OfbChrgGoTUpdate_B_Rq 1;
BA_ "U_U55X_MY2022_Tx" SG_ 639 OfbChrgGoTUpdate_B_Rq 1;
BA_ "GenSigSendType" SG_ 530 OfbChrgLocIdTrgt_No_Rq 3;
BA_ "ECGUsedTxSignal" SG_ 530 OfbChrgLocIdTrgt_No_Rq 1;
BA_ "U_CD542_MY2021_Tx" SG_ 530 OfbChrgLocIdTrgt_No_Rq 1;
BA_ "U_U55X_MY2022_Tx" SG_ 530 OfbChrgLocIdTrgt_No_Rq 1;
BA_ "ECGUsedTxSignal" SG_ 530 OfbChrgToPcWknd_D_Actl 1;
BA_ "U_CD542_MY2021_Tx" SG_ 530 OfbChrgToPcWknd_D_Actl 1;
BA_ "U_U55X_MY2022_Tx" SG_ 530 OfbChrgToPcWknd_D_Actl 1;
BA_ "ECGUsedTxSignal" SG_ 530 OfbChrgToPcWkdy_D_Actl 1;
BA_ "U_CD542_MY2021_Tx" SG_ 530 OfbChrgToPcWkdy_D_Actl 1;
BA_ "U_U55X_MY2022_Tx" SG_ 530 OfbChrgToPcWkdy_D_Actl 1;
BA_ "ECGUsedTxSignal" SG_ 530 OfbChrgSetNow_D_Rq 1;
BA_ "U_CD542_MY2021_Tx" SG_ 530 OfbChrgSetNow_D_Rq 1;
BA_ "U_U55X_MY2022_Tx" SG_ 530 OfbChrgSetNow_D_Rq 1;
BA_ "ECGUsedTxSignal" SG_ 530 OfbChrgSetDelete_B_Rq 1;
BA_ "U_CD542_MY2021_Tx" SG_ 530 OfbChrgSetDelete_B_Rq 1;
BA_ "U_U55X_MY2022_Tx" SG_ 530 OfbChrgSetDelete_B_Rq 1;
BA_ "ECGUsedTxSignal" SG_ 530 OfbChrgPrflWknd_No_Rq 1;
BA_ "U_CD542_MY2021_Tx" SG_ 530 OfbChrgPrflWknd_No_Rq 1;
BA_ "U_U55X_MY2022_Tx" SG_ 530 OfbChrgPrflWknd_No_Rq 1;
BA_ "ECGUsedTxSignal" SG_ 530 OfbChrgPrflWkdy_No_Rq 1;
BA_ "U_CD542_MY2021_Tx" SG_ 530 OfbChrgPrflWkdy_No_Rq 1;
BA_ "U_U55X_MY2022_Tx" SG_ 530 OfbChrgPrflWkdy_No_Rq 1;
BA_ "ECGUsedTxSignal" SG_ 530 OfbChrgLocIdUns_B_Rq 1;
BA_ "U_CD542_MY2021_Tx" SG_ 530 OfbChrgLocIdUns_B_Rq 1;
BA_ "U_U55X_MY2022_Tx" SG_ 530 OfbChrgLocIdUns_B_Rq 1;
BA_ "GenSigSendType" SG_ 550 PtWakeupActv1_B_Rq 3;
BA_ "WakeupSignal" SG_ 550 PtWakeupActv1_B_Rq 1;
BA_ "ECGUsedTxSignal" SG_ 550 PtWakeupActv1_B_Rq 1;
BA_ "U_CD542_MY2021_Tx" SG_ 550 PtWakeupActv1_B_Rq 1;
BA_ "U_U55X_MY2022_Tx" SG_ 550 PtWakeupActv1_B_Rq 1;
BA_ "U_CDX706_MY2023_Tx" SG_ 550 PtWakeupActv1_B_Rq 1;
BA_ "GenSigStartValueInteger" SG_ 1455 BCMD_GWOnBoardTester 255;
BA_ "ContentDependant" SG_ 1455 BCMD_GWOnBoardTester 1;
BA_ "GenSigStartValue" SG_ 1455 BCMD_GWOnBoardTester 255;
BA_ "GenSigStartValueInteger" SG_ 1455 BCMD_GWNMProxy 255;
BA_ "ContentDependant" SG_ 1455 BCMD_GWNMProxy 1;
BA_ "GenSigStartValue" SG_ 1455 BCMD_GWNMProxy 255;
BA_ "GenSigStartValueInteger" SG_ 1455 BCMD_AutoSarNMReserved4 255;
BA_ "ContentDependant" SG_ 1455 BCMD_AutoSarNMReserved4 1;
BA_ "GenSigStartValue" SG_ 1455 BCMD_AutoSarNMReserved4 255;
BA_ "GenSigStartValueInteger" SG_ 1455 BCMD_AutoSarNMReserved3 255;
BA_ "ContentDependant" SG_ 1455 BCMD_AutoSarNMReserved3 1;
BA_ "GenSigStartValue" SG_ 1455 BCMD_AutoSarNMReserved3 255;
BA_ "GenSigStartValueInteger" SG_ 1455 BCMD_AutoSarNMReserved2 255;
BA_ "ContentDependant" SG_ 1455 BCMD_AutoSarNMReserved2 1;
BA_ "GenSigStartValue" SG_ 1455 BCMD_AutoSarNMReserved2 255;
BA_ "GenSigStartValueInteger" SG_ 1455 BCMD_AutoSarNMReserved1 255;
BA_ "ContentDependant" SG_ 1455 BCMD_AutoSarNMReserved1 1;
BA_ "GenSigStartValue" SG_ 1455 BCMD_AutoSarNMReserved1 255;
BA_ "GenSigStartValueInteger" SG_ 1455 BCMD_AutoSarNMNodeId 175;
BA_ "ContentDependant" SG_ 1455 BCMD_AutoSarNMNodeId 1;
BA_ "GenSigStartValue" SG_ 1455 BCMD_AutoSarNMNodeId 175;
BA_ "ContentDependant" SG_ 1455 BCMD_AutoSarNMControl 1;
BA_ "GenSigSendType" SG_ 1775 TesterPhysicalResBCMD_IPDB 3;
BA_ "GenSigSendType" SG_ 1767 TesterPhysicalReqBCMD_IPDB 3;
BA_ "GenSigSendType" SG_ 2612019416 PARSEDPushFcGWM_ECGtoPCM 3;
BA_ "U_T6_MCA_MY2020_Rx" SG_ 2612019416 PARSEDPushFcGWM_ECGtoPCM 1;
BA_ "U_CD542_MY2021_Rx" SG_ 2612019416 PARSEDPushFcGWM_ECGtoPCM 1;
BA_ "U_U55X_MY2022_Rx" SG_ 2612019416 PARSEDPushFcGWM_ECGtoPCM 1;
BA_ "U_CD764_MY2022_Rx" SG_ 2612019416 PARSEDPushFcGWM_ECGtoPCM 1;
BA_ "U_CDX706_MY2023_Rx" SG_ 2612019416 PARSEDPushFcGWM_ECGtoPCM 1;
BA_ "U_T6_MCA_MY2020_Tx" SG_ 2612019416 PARSEDPushFcGWM_ECGtoPCM 1;
BA_ "ECGUsedTxSignal" SG_ 2612019416 PARSEDPushFcGWM_ECGtoPCM 1;
BA_ "U_U55X_MY2022_Tx" SG_ 2612019416 PARSEDPushFcGWM_ECGtoPCM 1;
BA_ "U_CD764_MY2022_Tx" SG_ 2612019416 PARSEDPushFcGWM_ECGtoPCM 1;
BA_ "U_CDX706_MY2023_Tx" SG_ 2612019416 PARSEDPushFcGWM_ECGtoPCM 1;
BA_ "U_T6_MCA_MY2020_Tx" SG_ 885 BattULoChrg_D_RqOta 1;
BA_ "ECGUsedTxSignal" SG_ 885 BattULoChrg_D_RqOta 1;
BA_ "U_CD542_MY2021_Tx" SG_ 885 BattULoChrg_D_RqOta 1;
BA_ "U_U55X_MY2022_Tx" SG_ 885 BattULoChrg_D_RqOta 1;
BA_ "U_CD764_MY2022_Tx" SG_ 885 BattULoChrg_D_RqOta 1;
BA_ "U_CDX706_MY2023_Tx" SG_ 885 BattULoChrg_D_RqOta 1;
BA_ "U_T6_MCA_MY2020_Tx" SG_ 885 VehStrtInhbt_T_Dsply 1;
BA_ "ECGUsedTxSignal" SG_ 885 VehStrtInhbt_T_Dsply 1;
BA_ "U_CD542_MY2021_Tx" SG_ 885 VehStrtInhbt_T_Dsply 1;
BA_ "U_U55X_MY2022_Tx" SG_ 885 VehStrtInhbt_T_Dsply 1;
BA_ "U_CD764_MY2022_Tx" SG_ 885 VehStrtInhbt_T_Dsply 1;
BA_ "U_CDX706_MY2023_Tx" SG_ 885 VehStrtInhbt_T_Dsply 1;
BA_ "U_T6_MCA_MY2020_Tx" SG_ 885 VehStrtInhbt_D_Dsply 1;
BA_ "ECGUsedTxSignal" SG_ 885 VehStrtInhbt_D_Dsply 1;
BA_ "U_CD542_MY2021_Tx" SG_ 885 VehStrtInhbt_D_Dsply 1;
BA_ "U_U55X_MY2022_Tx" SG_ 885 VehStrtInhbt_D_Dsply 1;
BA_ "U_CD764_MY2022_Tx" SG_ 885 VehStrtInhbt_D_Dsply 1;
BA_ "U_CDX706_MY2023_Tx" SG_ 885 VehStrtInhbt_D_Dsply 1;
BA_ "U_T6_MCA_MY2020_Tx" SG_ 885 VehOnRqstr_D_Stat 1;
BA_ "ECGUsedTxSignal" SG_ 885 VehOnRqstr_D_Stat 1;
BA_ "U_CD542_MY2021_Tx" SG_ 885 VehOnRqstr_D_Stat 1;
BA_ "U_U55X_MY2022_Tx" SG_ 885 VehOnRqstr_D_Stat 1;
BA_ "U_CD764_MY2022_Tx" SG_ 885 VehOnRqstr_D_Stat 1;
BA_ "U_CDX706_MY2023_Tx" SG_ 885 VehOnRqstr_D_Stat 1;
BA_ "U_T6_MCA_MY2020_Tx" SG_ 885 VehStrtInhbt_D_RqCld 1;
BA_ "ECGUsedTxSignal" SG_ 885 VehStrtInhbt_D_RqCld 1;
BA_ "U_CD542_MY2021_Tx" SG_ 885 VehStrtInhbt_D_RqCld 1;
BA_ "U_U55X_MY2022_Tx" SG_ 885 VehStrtInhbt_D_RqCld 1;
BA_ "U_CD764_MY2022_Tx" SG_ 885 VehStrtInhbt_D_RqCld 1;
BA_ "U_CDX706_MY2023_Tx" SG_ 885 VehStrtInhbt_D_RqCld 1;
BA_ "U_T6_MCA_MY2020_Tx" SG_ 885 VehOn_D_RqCld 1;
BA_ "ECGUsedTxSignal" SG_ 885 VehOn_D_RqCld 1;
BA_ "U_CD542_MY2021_Tx" SG_ 885 VehOn_D_RqCld 1;
BA_ "U_U55X_MY2022_Tx" SG_ 885 VehOn_D_RqCld 1;
BA_ "U_CD764_MY2022_Tx" SG_ 885 VehOn_D_RqCld 1;
BA_ "U_CDX706_MY2023_Tx" SG_ 885 VehOn_D_RqCld 1;
BA_ "MetaData" SG_ 885 CanMsg375_No_Cnt 1;
BA_ "U_T6_MCA_MY2020_Tx" SG_ 885 CanMsg375_No_Cnt 1;
BA_ "ECGUsedTxSignal" SG_ 885 CanMsg375_No_Cnt 1;
BA_ "U_CD542_MY2021_Tx" SG_ 885 CanMsg375_No_Cnt 1;
BA_ "U_U55X_MY2022_Tx" SG_ 885 CanMsg375_No_Cnt 1;
BA_ "U_CD764_MY2022_Tx" SG_ 885 CanMsg375_No_Cnt 1;
BA_ "U_CDX706_MY2023_Tx" SG_ 885 CanMsg375_No_Cnt 1;
BA_ "MetaData" SG_ 885 CanMsg375_No_Crc 1;
BA_ "U_T6_MCA_MY2020_Tx" SG_ 885 CanMsg375_No_Crc 1;
BA_ "ECGUsedTxSignal" SG_ 885 CanMsg375_No_Crc 1;
BA_ "U_CD542_MY2021_Tx" SG_ 885 CanMsg375_No_Crc 1;
BA_ "U_U55X_MY2022_Tx" SG_ 885 CanMsg375_No_Crc 1;
BA_ "U_CD764_MY2022_Tx" SG_ 885 CanMsg375_No_Crc 1;
BA_ "U_CDX706_MY2023_Tx" SG_ 885 CanMsg375_No_Crc 1;
BA_ "U_T6_MCA_MY2020_Rx" SG_ 885 OtaActv_D_Stat 1;
BA_ "U_CDX706_MY2023_Rx" SG_ 885 OtaActv_D_Stat 1;
BA_ "U_T6_MCA_MY2020_Tx" SG_ 885 OtaActv_D_Stat 1;
BA_ "ECGUsedTxSignal" SG_ 885 OtaActv_D_Stat 1;
BA_ "U_CD542_MY2021_Tx" SG_ 885 OtaActv_D_Stat 1;
BA_ "U_U55X_MY2022_Tx" SG_ 885 OtaActv_D_Stat 1;
BA_ "U_CD764_MY2022_Tx" SG_ 885 OtaActv_D_Stat 1;
BA_ "U_CDX706_MY2023_Tx" SG_ 885 OtaActv_D_Stat 1;
BA_ "GenSigSendType" SG_ 2612104408 PARSEDPushFcGWM_ECGtoSODR 3;
BA_ "U_T6_MCA_MY2020_Rx" SG_ 2612104408 PARSEDPushFcGWM_ECGtoSODR 1;
BA_ "U_U55X_MY2022_Rx" SG_ 2612104408 PARSEDPushFcGWM_ECGtoSODR 1;
BA_ "U_CDX706_MY2023_Rx" SG_ 2612104408 PARSEDPushFcGWM_ECGtoSODR 1;
BA_ "U_T6_MCA_MY2020_Tx" SG_ 2612104408 PARSEDPushFcGWM_ECGtoSODR 1;
BA_ "ECGUsedTxSignal" SG_ 2612104408 PARSEDPushFcGWM_ECGtoSODR 1;
BA_ "U_CD542_MY2021_Tx" SG_ 2612104408 PARSEDPushFcGWM_ECGtoSODR 1;
BA_ "U_U55X_MY2022_Tx" SG_ 2612104408 PARSEDPushFcGWM_ECGtoSODR 1;
BA_ "U_CDX706_MY2023_Tx" SG_ 2612104408 PARSEDPushFcGWM_ECGtoSODR 1;
BA_ "GenSigSendType" SG_ 2612020440 PARSEDPushFcGWMtoSOBDMC 3;
BA_ "U_CDX706_MY2023_Rx" SG_ 2612020440 PARSEDPushFcGWMtoSOBDMC 1;
BA_ "ECGUsedTxSignal" SG_ 2612020440 PARSEDPushFcGWMtoSOBDMC 1;
BA_ "U_CD542_MY2021_Tx" SG_ 2612020440 PARSEDPushFcGWMtoSOBDMC 1;
BA_ "U_U55X_MY2022_Tx" SG_ 2612020440 PARSEDPushFcGWMtoSOBDMC 1;
BA_ "U_CDX706_MY2023_Tx" SG_ 2612020440 PARSEDPushFcGWMtoSOBDMC 1;
BA_ "U_CD764_MY2022_Rx" SG_ 979 LatCtlRng_L_Max 1;
BA_ "U_T6_MCA_MY2020_Rx" SG_ 979 LatCtlRampType_D_Rq 1;
BA_ "U_U55X_MY2022_Rx" SG_ 979 LatCtlRampType_D_Rq 1;
BA_ "U_CD764_MY2022_Rx" SG_ 979 LatCtlRampType_D_Rq 1;
BA_ "U_CDX706_MY2023_Rx" SG_ 979 LatCtlRampType_D_Rq 1;
BA_ "U_T6_MCA_MY2020_Tx" SG_ 979 LatCtlRampType_D_Rq 1;
BA_ "U_U55X_MY2022_Tx" SG_ 979 LatCtlRampType_D_Rq 1;
BA_ "U_CD764_MY2022_Tx" SG_ 979 LatCtlRampType_D_Rq 1;
BA_ "U_CDX706_MY2023_Tx" SG_ 979 LatCtlRampType_D_Rq 1;
BA_ "U_T6_MCA_MY2020_Rx" SG_ 979 LatCtlPrecision_D_Rq 1;
BA_ "U_U55X_MY2022_Rx" SG_ 979 LatCtlPrecision_D_Rq 1;
BA_ "U_CD764_MY2022_Rx" SG_ 979 LatCtlPrecision_D_Rq 1;
BA_ "U_CDX706_MY2023_Rx" SG_ 979 LatCtlPrecision_D_Rq 1;
BA_ "U_T6_MCA_MY2020_Tx" SG_ 979 LatCtlPrecision_D_Rq 1;
BA_ "U_U55X_MY2022_Tx" SG_ 979 LatCtlPrecision_D_Rq 1;
BA_ "U_CD764_MY2022_Tx" SG_ 979 LatCtlPrecision_D_Rq 1;
BA_ "U_CDX706_MY2023_Tx" SG_ 979 LatCtlPrecision_D_Rq 1;
BA_ "GenSigStartValueInteger" SG_ 979 LatCtlPathOffst_L_Actl 512;
BA_ "U_T6_MCA_MY2020_Rx" SG_ 979 LatCtlPathOffst_L_Actl 1;
BA_ "U_U55X_MY2022_Rx" SG_ 979 LatCtlPathOffst_L_Actl 1;
BA_ "U_CD764_MY2022_Rx" SG_ 979 LatCtlPathOffst_L_Actl 1;
BA_ "U_CDX706_MY2023_Rx" SG_ 979 LatCtlPathOffst_L_Actl 1;
BA_ "U_T6_MCA_MY2020_Tx" SG_ 979 LatCtlPathOffst_L_Actl 1;
BA_ "U_U55X_MY2022_Tx" SG_ 979 LatCtlPathOffst_L_Actl 1;
BA_ "U_CD764_MY2022_Tx" SG_ 979 LatCtlPathOffst_L_Actl 1;
BA_ "U_CDX706_MY2023_Tx" SG_ 979 LatCtlPathOffst_L_Actl 1;
BA_ "GenSigStartValueInteger" SG_ 979 LatCtlPath_An_Actl 1000;
BA_ "U_T6_MCA_MY2020_Rx" SG_ 979 LatCtlPath_An_Actl 1;
BA_ "U_U55X_MY2022_Rx" SG_ 979 LatCtlPath_An_Actl 1;
BA_ "U_CD764_MY2022_Rx" SG_ 979 LatCtlPath_An_Actl 1;
BA_ "U_CDX706_MY2023_Rx" SG_ 979 LatCtlPath_An_Actl 1;
BA_ "U_T6_MCA_MY2020_Tx" SG_ 979 LatCtlPath_An_Actl 1;
BA_ "U_U55X_MY2022_Tx" SG_ 979 LatCtlPath_An_Actl 1;
BA_ "U_CD764_MY2022_Tx" SG_ 979 LatCtlPath_An_Actl 1;
BA_ "U_CDX706_MY2023_Tx" SG_ 979 LatCtlPath_An_Actl 1;
BA_ "GenSigStartValueInteger" SG_ 979 LatCtlCurv_NoRate_Actl 4096;
BA_ "U_CD764_MY2022_Rx" SG_ 979 LatCtlCurv_NoRate_Actl 1;
BA_ "GenSigStartValueInteger" SG_ 979 LatCtlCurv_No_Actl 1000;
BA_ "U_T6_MCA_MY2020_Rx" SG_ 979 LatCtlCurv_No_Actl 1;
BA_ "U_U55X_MY2022_Rx" SG_ 979 LatCtlCurv_No_Actl 1;
BA_ "U_CD764_MY2022_Rx" SG_ 979 LatCtlCurv_No_Actl 1;
BA_ "U_CDX706_MY2023_Rx" SG_ 979 LatCtlCurv_No_Actl 1;
BA_ "U_T6_MCA_MY2020_Tx" SG_ 979 LatCtlCurv_No_Actl 1;
BA_ "U_U55X_MY2022_Tx" SG_ 979 LatCtlCurv_No_Actl 1;
BA_ "U_CD764_MY2022_Tx" SG_ 979 LatCtlCurv_No_Actl 1;
BA_ "U_CDX706_MY2023_Tx" SG_ 979 LatCtlCurv_No_Actl 1;
BA_ "U_CD764_MY2022_Rx" SG_ 979 LatCtl_D_Rq 1;
BA_ "U_T6_MCA_MY2020_Rx" SG_ 979 HandsOffCnfm_B_Rq 1;
BA_ "U_U55X_MY2022_Rx" SG_ 979 HandsOffCnfm_B_Rq 1;
BA_ "U_CD764_MY2022_Rx" SG_ 979 HandsOffCnfm_B_Rq 1;
BA_ "U_CDX706_MY2023_Rx" SG_ 979 HandsOffCnfm_B_Rq 1;
BA_ "U_T6_MCA_MY2020_Tx" SG_ 979 HandsOffCnfm_B_Rq 1;
BA_ "U_U55X_MY2022_Tx" SG_ 979 HandsOffCnfm_B_Rq 1;
BA_ "U_CD764_MY2022_Tx" SG_ 979 HandsOffCnfm_B_Rq 1;
BA_ "U_CDX706_MY2023_Tx" SG_ 979 HandsOffCnfm_B_Rq 1;
BA_ "GenSigStartValue" SG_ 739 BptMnSoc_L_RqMnu 8190;
BA_ "GenSigStartValue" SG_ 739 OnbTrgtSocOvrrd_Pc_Rq 100;
BA_ "U_T6_MCA_MY2020_Rx" SG_ 739 EngExhMdeHrStrt_D_Rq 1;
BA_ "U_T6_MCA_MY2020_Rx" SG_ 739 EngExhMdeHrEnd_D_Rq 1;
BA_ "U_T6_MCA_MY2020_Rx" SG_ 739 EngExhMdeHrEnbl_D_Rq 1;
BA_ "GenSigStartValue" SG_ 739 BptDly_T_RqMnu 62;
BA_ "WakeupSignal" SG_ 739 HMI_HMIMode_St 1;
BA_ "U_CD764_MY2022_Rx" SG_ 739 HMI_HMIMode_St 1;
BA_ "U_CDX706_MY2023_Rx" SG_ 739 HMI_HMIMode_St 1;
BA_ "GenSigSendType" SG_ 1160 VgfZone_D_Stat 3;
BA_ "ECGUsedTxSignal" SG_ 1160 VgfZone_D_Stat 1;
BA_ "GenSigSendType" SG_ 1160 HybMdeGzg_D_Rq 3;
BA_ "ECGUsedTxSignal" SG_ 1160 HybMdeGzg_D_Rq 1;
BA_ "GenSigSendType" SG_ 1160 ReFuelSwtchStat_D_Actl2 3;
BA_ "WakeupSignal" SG_ 1160 ReFuelSwtchStat_D_Actl2 1;
BA_ "U_CDX706_MY2023_Rx" SG_ 1160 ReFuelSwtchStat_D_Actl2 1;
BA_ "ECGUsedTxSignal" SG_ 1160 ReFuelSwtchStat_D_Actl2 1;
BA_ "U_CD764_MY2022_Tx" SG_ 1160 ReFuelSwtchStat_D_Actl2 1;
BA_ "U_CDX706_MY2023_Tx" SG_ 1160 ReFuelSwtchStat_D_Actl2 1;
BA_ "GenSigSendType" SG_ 1160 DcacPwReset_B_RqCell 3;
BA_ "ECGUsedTxSignal" SG_ 1160 DcacPwReset_B_RqCell 1;
BA_ "U_CD542_MY2021_Tx" SG_ 1160 DcacPwReset_B_RqCell 1;
BA_ "U_U55X_MY2022_Tx" SG_ 1160 DcacPwReset_B_RqCell 1;
BA_ "U_CD764_MY2022_Tx" SG_ 1160 DcacPwReset_B_RqCell 1;
BA_ "U_CDX706_MY2023_Tx" SG_ 1160 DcacPwReset_B_RqCell 1;
BA_ "GenSigSendType" SG_ 1160 DcacPw_D_RqCell 3;
BA_ "ECGUsedTxSignal" SG_ 1160 DcacPw_D_RqCell 1;
BA_ "U_CD542_MY2021_Tx" SG_ 1160 DcacPw_D_RqCell 1;
BA_ "U_U55X_MY2022_Tx" SG_ 1160 DcacPw_D_RqCell 1;
BA_ "U_CD764_MY2022_Tx" SG_ 1160 DcacPw_D_RqCell 1;
BA_ "U_CDX706_MY2023_Tx" SG_ 1160 DcacPw_D_RqCell 1;
BA_ "GenSigSendType" SG_ 1160 DgtlCommPncReset_B_Req 3;
BA_ "ECGUsedTxSignal" SG_ 1160 DgtlCommPncReset_B_Req 1;
BA_ "U_CD542_MY2021_Tx" SG_ 1160 DgtlCommPncReset_B_Req 1;
BA_ "U_U55X_MY2022_Tx" SG_ 1160 DgtlCommPncReset_B_Req 1;
BA_ "U_CD764_MY2022_Tx" SG_ 1160 DgtlCommPncReset_B_Req 1;
BA_ "U_CDX706_MY2023_Tx" SG_ 1160 DgtlCommPncReset_B_Req 1;
BA_ "GenSigSendType" SG_ 1160 DgtlCommPnc_D_Rq 3;
BA_ "ECGUsedTxSignal" SG_ 1160 DgtlCommPnc_D_Rq 1;
BA_ "U_CD542_MY2021_Tx" SG_ 1160 DgtlCommPnc_D_Rq 1;
BA_ "U_U55X_MY2022_Tx" SG_ 1160 DgtlCommPnc_D_Rq 1;
BA_ "U_CD764_MY2022_Tx" SG_ 1160 DgtlCommPnc_D_Rq 1;
BA_ "U_CDX706_MY2023_Tx" SG_ 1160 DgtlCommPnc_D_Rq 1;
BA_ "GenSigSendType" SG_ 1160 DataMntrSustn_B_Rq 3;
BA_ "ECGUsedTxSignal" SG_ 1160 DataMntrSustn_B_Rq 1;
BA_ "U_CD542_MY2021_Tx" SG_ 1160 DataMntrSustn_B_Rq 1;
BA_ "U_U55X_MY2022_Tx" SG_ 1160 DataMntrSustn_B_Rq 1;
BA_ "U_CD764_MY2022_Tx" SG_ 1160 DataMntrSustn_B_Rq 1;
BA_ "U_CDX706_MY2023_Tx" SG_ 1160 DataMntrSustn_B_Rq 1;
BA_ "GenSigSendType" SG_ 1160 PwSustnRdata_B_RqTelem 3;
BA_ "U_CDX706_MY2023_Rx" SG_ 1160 PwSustnRdata_B_RqTelem 1;
BA_ "ECGUsedTxSignal" SG_ 1160 PwSustnRdata_B_RqTelem 1;
BA_ "U_CD542_MY2021_Tx" SG_ 1160 PwSustnRdata_B_RqTelem 1;
BA_ "U_U55X_MY2022_Tx" SG_ 1160 PwSustnRdata_B_RqTelem 1;
BA_ "U_CD764_MY2022_Tx" SG_ 1160 PwSustnRdata_B_RqTelem 1;
BA_ "U_CDX706_MY2023_Tx" SG_ 1160 PwSustnRdata_B_RqTelem 1;
BA_ "GenSigSendType" SG_ 1825 TesterPhysicalReqVDM 3;
BA_ "U_T6_MCA_MY2020_Rx" SG_ 1825 TesterPhysicalReqVDM 1;
BA_ "U_U55X_MY2022_Rx" SG_ 1825 TesterPhysicalReqVDM 1;
BA_ "GenSigStartValueInteger" SG_ 1001 PersIndexSuma_D_Actl 4;
BA_ "GenSigStartValue" SG_ 1001 PersIndexSuma_D_Actl 4;
BA_ "GenSigStartValueInteger" SG_ 1077 AirSprngRear_P_Actl 592;
BA_ "GenSigStartValueInteger" SG_ 1077 AirSprngFront_P_Actl 592;
BA_ "WakeupSignal" SG_ 945 PrkLckCtlMsgTxt_D2_Rq 1;
BA_ "WakeupSignal" SG_ 945 PwLoApim_T_Actl 1;
BA_ "WakeupSignal" SG_ 945 KeyPadCodeDgt6_D_Dsply 1;
BA_ "WakeupSignal" SG_ 945 KeyPadCodeDgt5_D_Dsply 1;
BA_ "WakeupSignal" SG_ 945 KeyPadCodeDgt4_D_Dsply 1;
BA_ "WakeupSignal" SG_ 945 KeyPadCodeDgt3_D_Dsply 1;
BA_ "WakeupSignal" SG_ 945 KeyPadCodeDgt2_D_Dsply 1;
BA_ "WakeupSignal" SG_ 945 KeyPadCodeDgt1_D_Dsply 1;
BA_ "U_CDX706_MY2023_Rx" SG_ 945 KeyOffMde_D_Actl 1;
BA_ "GenSigSendType" SG_ 2612073688 PARSEDPushFcGWMtoSODCMC 3;
BA_ "U_T6_MCA_MY2020_Rx" SG_ 2612073688 PARSEDPushFcGWMtoSODCMC 1;
BA_ "U_U55X_MY2022_Rx" SG_ 2612073688 PARSEDPushFcGWMtoSODCMC 1;
BA_ "U_CDX706_MY2023_Rx" SG_ 2612073688 PARSEDPushFcGWMtoSODCMC 1;
BA_ "U_T6_MCA_MY2020_Tx" SG_ 2612073688 PARSEDPushFcGWMtoSODCMC 1;
BA_ "ECGUsedTxSignal" SG_ 2612073688 PARSEDPushFcGWMtoSODCMC 1;
BA_ "U_CD542_MY2021_Tx" SG_ 2612073688 PARSEDPushFcGWMtoSODCMC 1;
BA_ "U_U55X_MY2022_Tx" SG_ 2612073688 PARSEDPushFcGWMtoSODCMC 1;
BA_ "U_CDX706_MY2023_Tx" SG_ 2612073688 PARSEDPushFcGWMtoSODCMC 1;
BA_ "GenSigSendType" SG_ 771 ScLocSetId_No_Stat 3;
BA_ "ECGUsedRxSignal" SG_ 771 ScLocSetId_No_Stat 1;
BA_ "U_CD542_MY2021_Rx" SG_ 771 ScLocSetId_No_Stat 1;
BA_ "U_U55X_MY2022_Rx" SG_ 771 ScLocSetId_No_Stat 1;
BA_ "GenSigSendType" SG_ 771 ScLocRdius_L_Actl 3;
BA_ "ECGUsedRxSignal" SG_ 771 ScLocRdius_L_Actl 1;
BA_ "U_CD542_MY2021_Rx" SG_ 771 ScLocRdius_L_Actl 1;
BA_ "U_U55X_MY2022_Rx" SG_ 771 ScLocRdius_L_Actl 1;
BA_ "GenSigSendType" SG_ 771 ScDayOfWeekId_D_Stat 3;
BA_ "GenSigStartValue" SG_ 771 ScDayOfWeekId_D_Stat 1;
BA_ "ECGUsedRxSignal" SG_ 771 ScDayOfWeekId_D_Stat 1;
BA_ "U_CD542_MY2021_Rx" SG_ 771 ScDayOfWeekId_D_Stat 1;
BA_ "U_U55X_MY2022_Rx" SG_ 771 ScDayOfWeekId_D_Stat 1;
BA_ "GenSigSendType" SG_ 771 ScChrgToPc_Pc_Actl 3;
BA_ "ECGUsedRxSignal" SG_ 771 ScChrgToPc_Pc_Actl 1;
BA_ "U_CD542_MY2021_Rx" SG_ 771 ScChrgToPc_Pc_Actl 1;
BA_ "U_U55X_MY2022_Rx" SG_ 771 ScChrgToPc_Pc_Actl 1;
BA_ "GenSigSendType" SG_ 771 ScChrgPrfl_No_Actl 3;
BA_ "ECGUsedRxSignal" SG_ 771 ScChrgPrfl_No_Actl 1;
BA_ "U_CD542_MY2021_Rx" SG_ 771 ScChrgPrfl_No_Actl 1;
BA_ "U_U55X_MY2022_Rx" SG_ 771 ScChrgPrfl_No_Actl 1;
BA_ "GenSigSendType" SG_ 771 ScChrgDurSet_B_Stat 3;
BA_ "ECGUsedRxSignal" SG_ 771 ScChrgDurSet_B_Stat 1;
BA_ "U_CD542_MY2021_Rx" SG_ 771 ScChrgDurSet_B_Stat 1;
BA_ "U_U55X_MY2022_Rx" SG_ 771 ScChrgDurSet_B_Stat 1;
BA_ "GenSigSendType" SG_ 771 ScChrgDur_T_Actl 3;
BA_ "ECGUsedRxSignal" SG_ 771 ScChrgDur_T_Actl 1;
BA_ "U_CD542_MY2021_Rx" SG_ 771 ScChrgDur_T_Actl 1;
BA_ "U_U55X_MY2022_Rx" SG_ 771 ScChrgDur_T_Actl 1;
BA_ "GenSigSendType" SG_ 777 ScLocSaved_B_Dsply 3;
BA_ "ECGUsedRxSignal" SG_ 777 ScLocSaved_B_Dsply 1;
BA_ "U_CD542_MY2021_Rx" SG_ 777 ScLocSaved_B_Dsply 1;
BA_ "U_U55X_MY2022_Rx" SG_ 777 ScLocSaved_B_Dsply 1;
BA_ "GenSigSendType" SG_ 777 ScLocLongPostv_B_Stat 3;
BA_ "ECGUsedRxSignal" SG_ 777 ScLocLongPostv_B_Stat 1;
BA_ "U_CD542_MY2021_Rx" SG_ 777 ScLocLongPostv_B_Stat 1;
BA_ "U_U55X_MY2022_Rx" SG_ 777 ScLocLongPostv_B_Stat 1;
BA_ "GenSigSendType" SG_ 777 ScLocLongFrct_An_Actl 3;
BA_ "GenSigStartValue" SG_ 777 ScLocLongFrct_An_Actl 1048575;
BA_ "ECGUsedRxSignal" SG_ 777 ScLocLongFrct_An_Actl 1;
BA_ "U_CD542_MY2021_Rx" SG_ 777 ScLocLongFrct_An_Actl 1;
BA_ "U_U55X_MY2022_Rx" SG_ 777 ScLocLongFrct_An_Actl 1;
BA_ "GenSigSendType" SG_ 777 ScLocLongDeg_An_Actl 3;
BA_ "ECGUsedRxSignal" SG_ 777 ScLocLongDeg_An_Actl 1;
BA_ "U_CD542_MY2021_Rx" SG_ 777 ScLocLongDeg_An_Actl 1;
BA_ "U_U55X_MY2022_Rx" SG_ 777 ScLocLongDeg_An_Actl 1;
BA_ "GenSigSendType" SG_ 777 ScLocLattPostv_B_Stat 3;
BA_ "ECGUsedRxSignal" SG_ 777 ScLocLattPostv_B_Stat 1;
BA_ "U_CD542_MY2021_Rx" SG_ 777 ScLocLattPostv_B_Stat 1;
BA_ "U_U55X_MY2022_Rx" SG_ 777 ScLocLattPostv_B_Stat 1;
BA_ "GenSigSendType" SG_ 777 ScLocLattFrct_An_Actl 3;
BA_ "GenSigStartValue" SG_ 777 ScLocLattFrct_An_Actl 1048575;
BA_ "ECGUsedRxSignal" SG_ 777 ScLocLattFrct_An_Actl 1;
BA_ "U_CD542_MY2021_Rx" SG_ 777 ScLocLattFrct_An_Actl 1;
BA_ "U_U55X_MY2022_Rx" SG_ 777 ScLocLattFrct_An_Actl 1;
BA_ "GenSigSendType" SG_ 777 ScLocLattDeg_An_Actl 3;
BA_ "ECGUsedRxSignal" SG_ 777 ScLocLattDeg_An_Actl 1;
BA_ "U_CD542_MY2021_Rx" SG_ 777 ScLocLattDeg_An_Actl 1;
BA_ "U_U55X_MY2022_Rx" SG_ 777 ScLocLattDeg_An_Actl 1;
BA_ "GenSigSendType" SG_ 777 ScLocId_No_Stat 3;
BA_ "ECGUsedRxSignal" SG_ 777 ScLocId_No_Stat 1;
BA_ "U_CD542_MY2021_Rx" SG_ 777 ScLocId_No_Stat 1;
BA_ "U_U55X_MY2022_Rx" SG_ 777 ScLocId_No_Stat 1;
BA_ "GenSigSendType" SG_ 1043 PrkBrkPerfMsgTxt_D_Rq 3;
BA_ "GenSigSendType" SG_ 1043 PrkBrkPerfMde_D_Stat 3;
BA_ "GenSigSendType" SG_ 1043 WhlSpareMsgTxt_D_Rq 3;
BA_ "U_CDX706_MY2023_Tx" SG_ 1043 WhlSpareMsgTxt_D_Rq 1;
BA_ "GenSigSendType" SG_ 1043 WhlSpareDetct_D_Dsply 3;
BA_ "U_CDX706_MY2023_Tx" SG_ 1043 WhlSpareDetct_D_Dsply 1;
BA_ "GenSigSendType" SG_ 1043 PrkBrkPerfActv_B_Stat 3;
BA_ "GenSigSendType" SG_ 1043 SelDrvMdeHmi02_D_Rq 3;
BA_ "GenSigSendType" SG_ 1043 SelDrvMdeHmi04_D_Rq 3;
BA_ "U_T6_MCA_MY2020_Tx" SG_ 1043 SelDrvMdeHmi04_D_Rq 1;
BA_ "GenSigSendType" SG_ 1043 IndvMdeSusp_No_Stat 3;
BA_ "GenSigStartValue" SG_ 1043 IndvMdeSusp_No_Stat 15;
BA_ "ECGUsedRxSignal" SG_ 1043 IndvMdeSusp_No_Stat 1;
BA_ "U_CD542_MY2021_Rx" SG_ 1043 IndvMdeSusp_No_Stat 1;
BA_ "U_CD764_MY2022_Rx" SG_ 1043 IndvMdeSusp_No_Stat 1;
BA_ "U_CDX706_MY2023_Rx" SG_ 1043 IndvMdeSusp_No_Stat 1;
BA_ "U_CDX706_MY2023_Tx" SG_ 1043 IndvMdeSusp_No_Stat 1;
BA_ "GenSigSendType" SG_ 1043 IndvMdeSte_No_Stat 3;
BA_ "GenSigStartValue" SG_ 1043 IndvMdeSte_No_Stat 15;
BA_ "ECGUsedRxSignal" SG_ 1043 IndvMdeSte_No_Stat 1;
BA_ "U_CD542_MY2021_Rx" SG_ 1043 IndvMdeSte_No_Stat 1;
BA_ "U_CD764_MY2022_Rx" SG_ 1043 IndvMdeSte_No_Stat 1;
BA_ "U_CDX706_MY2023_Rx" SG_ 1043 IndvMdeSte_No_Stat 1;
BA_ "U_CDX706_MY2023_Tx" SG_ 1043 IndvMdeSte_No_Stat 1;
BA_ "GenSigSendType" SG_ 1043 IndvMdeSel_No_Rq 3;
BA_ "GenSigStartValue" SG_ 1043 IndvMdeSel_No_Rq 15;
BA_ "U_CDX706_MY2023_Tx" SG_ 1043 IndvMdeSel_No_Rq 1;
BA_ "GenSigSendType" SG_ 1043 IndvMdeSel_D_Stat 3;
BA_ "U_CDX706_MY2023_Tx" SG_ 1043 IndvMdeSel_D_Stat 1;
BA_ "GenSigSendType" SG_ 1043 IndvMdeMsgTxt_D_Rq 3;
BA_ "U_CDX706_MY2023_Tx" SG_ 1043 IndvMdeMsgTxt_D_Rq 1;
BA_ "GenSigSendType" SG_ 1043 IndvMde5_B_Avail 3;
BA_ "U_CDX706_MY2023_Tx" SG_ 1043 IndvMde5_B_Avail 1;
BA_ "GenSigSendType" SG_ 1043 IndvMde4_B_Avail 3;
BA_ "U_CDX706_MY2023_Tx" SG_ 1043 IndvMde4_B_Avail 1;
BA_ "GenSigSendType" SG_ 1043 IndvMde3_B_Avail 3;
BA_ "U_CDX706_MY2023_Tx" SG_ 1043 IndvMde3_B_Avail 1;
BA_ "GenSigSendType" SG_ 1043 IndvMde2_B_Avail 3;
BA_ "U_CDX706_MY2023_Tx" SG_ 1043 IndvMde2_B_Avail 1;
BA_ "GenSigSendType" SG_ 1043 IndvMde1_B_Avail 3;
BA_ "U_CDX706_MY2023_Tx" SG_ 1043 IndvMde1_B_Avail 1;
BA_ "GenSigSendType" SG_ 1043 TrailOnePdlMde_D_Ind 3;
BA_ "U_T6_MCA_MY2020_Tx" SG_ 1043 TrailOnePdlMde_D_Ind 1;
BA_ "U_CDX706_MY2023_Tx" SG_ 1043 TrailOnePdlMde_D_Ind 1;
BA_ "GenSigSendType" SG_ 1043 TrailOnePdlMsgTxt_D_Rq 3;
BA_ "U_T6_MCA_MY2020_Tx" SG_ 1043 TrailOnePdlMsgTxt_D_Rq 1;
BA_ "U_CDX706_MY2023_Tx" SG_ 1043 TrailOnePdlMsgTxt_D_Rq 1;
BA_ "GenSigSendType" SG_ 1043 OrtaSwtchLamp_B_Rq 3;
BA_ "U_T6_MCA_MY2020_Rx" SG_ 1043 OrtaSwtchLamp_B_Rq 1;
BA_ "U_T6_MCA_MY2020_Tx" SG_ 1043 OrtaSwtchLamp_B_Rq 1;
BA_ "U_U55X_MY2022_Tx" SG_ 1043 OrtaSwtchLamp_B_Rq 1;
BA_ "U_CDX706_MY2023_Tx" SG_ 1043 OrtaSwtchLamp_B_Rq 1;
BA_ "GenSigSendType" SG_ 1043 OrtaMsgTxt_D_Rq 3;
BA_ "U_T6_MCA_MY2020_Tx" SG_ 1043 OrtaMsgTxt_D_Rq 1;
BA_ "U_U55X_MY2022_Tx" SG_ 1043 OrtaMsgTxt_D_Rq 1;
BA_ "U_CDX706_MY2023_Tx" SG_ 1043 OrtaMsgTxt_D_Rq 1;
BA_ "GenSigSendType" SG_ 1043 OrtaMde_D_Ind 3;
BA_ "U_T6_MCA_MY2020_Tx" SG_ 1043 OrtaMde_D_Ind 1;
BA_ "U_U55X_MY2022_Tx" SG_ 1043 OrtaMde_D_Ind 1;
BA_ "U_CDX706_MY2023_Tx" SG_ 1043 OrtaMde_D_Ind 1;
BA_ "GenSigSendType" SG_ 1833 TesterPhysicalResVDM 3;
BA_ "U_T6_MCA_MY2020_Tx" SG_ 1833 TesterPhysicalResVDM 1;
BA_ "U_U55X_MY2022_Tx" SG_ 1833 TesterPhysicalResVDM 1;
BA_ "GenSigSendType" SG_ 991 PsngrLoad_D_Stat 3;
BA_ "GenSigSendType" SG_ 991 VehPayloadScrn_D_Stat 3;
BA_ "GenSigSendType" SG_ 991 VehPayloadTireP_B_Stat 3;
BA_ "GenSigSendType" SG_ 991 VehPayloadFlat_B_Stat 3;
BA_ "GenSigSendType" SG_ 991 TrlrTngLoad_D_Stat 3;
BA_ "GenSigStartValue" SG_ 991 TrlrTngLoad_D_Stat 6;
BA_ "GenSigSendType" SG_ 991 VehPayloadStew_B_Stat 3;
BA_ "GenSigSendType" SG_ 991 VehPayloadTare_D_Stat 3;
BA_ "GenSigSendType" SG_ 991 VehPayloadGear_B_Stat 3;
BA_ "GenSigSendType" SG_ 991 VehFalr_D_Stat 3;
BA_ "GenSigSendType" SG_ 991 Trlr_M_Actl 3;
BA_ "GenSigStartValue" SG_ 991 Trlr_M_Actl 2046;
BA_ "GenSigSendType" SG_ 991 PersIndexVdm_D_Actl 3;
BA_ "GenSigStartValueInteger" SG_ 991 PersIndexVdm_D_Actl 4;
BA_ "GenSigStartValue" SG_ 991 PersIndexVdm_D_Actl 4;
BA_ "GenSigSendType" SG_ 991 FeatNoVdmActl 3;
BA_ "GenSigSendType" SG_ 991 FeatConfigVdmActl 3;
BA_ "U_T6_MCA_MY2020_Rx" SG_ 395 SelDrvMdeCnfm_D_Stat 1;
BA_ "U_U55X_MY2022_Rx" SG_ 395 SelDrvMdeCnfm_D_Stat 1;
BA_ "U_CD764_MY2022_Rx" SG_ 395 SelDrvMdeCnfm_D_Stat 1;
BA_ "U_CDX706_MY2023_Rx" SG_ 395 SelDrvMdeCnfm_D_Stat 1;
BA_ "GenSigStartValueInteger" SG_ 395 HudShifPoint_N_Rq 30;
BA_ "GenSigStartValue" SG_ 395 HudShifPoint_N_Rq 30;
BA_ "U_CD542_MY2021_Rx" SG_ 542 LocationServices_3 1;
BA_ "U_CDX706_MY2023_Rx" SG_ 542 LocationServices_3 1;
BA_ "U_T6_MCA_MY2020_Tx" SG_ 1689 UUDTAWDResponse2 1;
BA_ "GenSigSendType" SG_ 515 PtIgnSwtch_D_Stat 3;
BA_ "GenSigStartValueInteger" SG_ 515 PtIgnSwtch_D_Stat 2;
BA_ "GenSigStartValue" SG_ 515 PtIgnSwtch_D_Stat 2;
BA_ "U_T6_MCA_MY2020_Tx" SG_ 515 PtIgnSwtch_D_Stat 1;
BA_ "U_CD764_MY2022_Tx" SG_ 515 PtIgnSwtch_D_Stat 1;
BA_ "U_CDX706_MY2023_Tx" SG_ 515 PtIgnSwtch_D_Stat 1;
BA_ "U_T6_MCA_MY2020_Rx" SG_ 982 LatCtlRampType_D_Rq 1;
BA_ "U_U55X_MY2022_Rx" SG_ 982 LatCtlRampType_D_Rq 1;
BA_ "U_CD764_MY2022_Rx" SG_ 982 LatCtlRampType_D_Rq 1;
BA_ "U_CDX706_MY2023_Rx" SG_ 982 LatCtlRampType_D_Rq 1;
BA_ "U_T6_MCA_MY2020_Tx" SG_ 982 LatCtlRampType_D_Rq 1;
BA_ "U_U55X_MY2022_Tx" SG_ 982 LatCtlRampType_D_Rq 1;
BA_ "U_CD764_MY2022_Tx" SG_ 982 LatCtlRampType_D_Rq 1;
BA_ "U_CDX706_MY2023_Tx" SG_ 982 LatCtlRampType_D_Rq 1;
BA_ "GenSigStartValue" SG_ 982 LatCtlCrv_NoRate2_Actl 1024;
BA_ "U_T6_MCA_MY2020_Rx" SG_ 982 LatCtlCrv_NoRate2_Actl 1;
BA_ "U_CD542_MY2021_Rx" SG_ 982 LatCtlCrv_NoRate2_Actl 1;
BA_ "U_U55X_MY2022_Rx" SG_ 982 LatCtlCrv_NoRate2_Actl 1;
BA_ "U_CD764_MY2022_Rx" SG_ 982 LatCtlCrv_NoRate2_Actl 1;
BA_ "U_CDX706_MY2023_Rx" SG_ 982 LatCtlCrv_NoRate2_Actl 1;
BA_ "U_T6_MCA_MY2020_Tx" SG_ 982 LatCtlCrv_NoRate2_Actl 1;
BA_ "U_CD542_MY2021_Tx" SG_ 982 LatCtlCrv_NoRate2_Actl 1;
BA_ "U_U55X_MY2022_Tx" SG_ 982 LatCtlCrv_NoRate2_Actl 1;
BA_ "U_CD764_MY2022_Tx" SG_ 982 LatCtlCrv_NoRate2_Actl 1;
BA_ "U_CDX706_MY2023_Tx" SG_ 982 LatCtlCrv_NoRate2_Actl 1;
BA_ "ContentDependant" SG_ 982 LatCtlPath_No_Cnt 1;
BA_ "MetaData" SG_ 982 LatCtlPath_No_Cnt 1;
BA_ "U_T6_MCA_MY2020_Rx" SG_ 982 LatCtlPath_No_Cnt 1;
BA_ "U_U55X_MY2022_Rx" SG_ 982 LatCtlPath_No_Cnt 1;
BA_ "U_CD764_MY2022_Rx" SG_ 982 LatCtlPath_No_Cnt 1;
BA_ "U_CDX706_MY2023_Rx" SG_ 982 LatCtlPath_No_Cnt 1;
BA_ "U_T6_MCA_MY2020_Tx" SG_ 982 LatCtlPath_No_Cnt 1;
BA_ "U_CD542_MY2021_Tx" SG_ 982 LatCtlPath_No_Cnt 1;
BA_ "U_U55X_MY2022_Tx" SG_ 982 LatCtlPath_No_Cnt 1;
BA_ "U_CD764_MY2022_Tx" SG_ 982 LatCtlPath_No_Cnt 1;
BA_ "U_CDX706_MY2023_Tx" SG_ 982 LatCtlPath_No_Cnt 1;
BA_ "ContentDependant" SG_ 982 LatCtlPath_No_Cs 1;
BA_ "MetaData" SG_ 982 LatCtlPath_No_Cs 1;
BA_ "U_T6_MCA_MY2020_Rx" SG_ 982 LatCtlPath_No_Cs 1;
BA_ "U_U55X_MY2022_Rx" SG_ 982 LatCtlPath_No_Cs 1;
BA_ "U_CD764_MY2022_Rx" SG_ 982 LatCtlPath_No_Cs 1;
BA_ "U_CDX706_MY2023_Rx" SG_ 982 LatCtlPath_No_Cs 1;
BA_ "U_T6_MCA_MY2020_Tx" SG_ 982 LatCtlPath_No_Cs 1;
BA_ "U_CD542_MY2021_Tx" SG_ 982 LatCtlPath_No_Cs 1;
BA_ "U_U55X_MY2022_Tx" SG_ 982 LatCtlPath_No_Cs 1;
BA_ "U_CD764_MY2022_Tx" SG_ 982 LatCtlPath_No_Cs 1;
BA_ "U_CDX706_MY2023_Tx" SG_ 982 LatCtlPath_No_Cs 1;
BA_ "U_T6_MCA_MY2020_Rx" SG_ 982 LatCtl_D2_Rq 1;
BA_ "U_CD542_MY2021_Rx" SG_ 982 LatCtl_D2_Rq 1;
BA_ "U_U55X_MY2022_Rx" SG_ 982 LatCtl_D2_Rq 1;
BA_ "U_CD764_MY2022_Rx" SG_ 982 LatCtl_D2_Rq 1;
BA_ "U_CDX706_MY2023_Rx" SG_ 982 LatCtl_D2_Rq 1;
BA_ "U_T6_MCA_MY2020_Tx" SG_ 982 LatCtl_D2_Rq 1;
BA_ "U_CD542_MY2021_Tx" SG_ 982 LatCtl_D2_Rq 1;
BA_ "U_U55X_MY2022_Tx" SG_ 982 LatCtl_D2_Rq 1;
BA_ "U_CD764_MY2022_Tx" SG_ 982 LatCtl_D2_Rq 1;
BA_ "U_CDX706_MY2023_Tx" SG_ 982 LatCtl_D2_Rq 1;
BA_ "U_T6_MCA_MY2020_Rx" SG_ 982 LatCtlPrecision_D_Rq 1;
BA_ "U_U55X_MY2022_Rx" SG_ 982 LatCtlPrecision_D_Rq 1;
BA_ "U_CD764_MY2022_Rx" SG_ 982 LatCtlPrecision_D_Rq 1;
BA_ "U_CDX706_MY2023_Rx" SG_ 982 LatCtlPrecision_D_Rq 1;
BA_ "U_T6_MCA_MY2020_Tx" SG_ 982 LatCtlPrecision_D_Rq 1;
BA_ "U_U55X_MY2022_Tx" SG_ 982 LatCtlPrecision_D_Rq 1;
BA_ "U_CD764_MY2022_Tx" SG_ 982 LatCtlPrecision_D_Rq 1;
BA_ "U_CDX706_MY2023_Tx" SG_ 982 LatCtlPrecision_D_Rq 1;
BA_ "GenSigStartValueInteger" SG_ 982 LatCtlPathOffst_L_Actl 512;
BA_ "U_T6_MCA_MY2020_Rx" SG_ 982 LatCtlPathOffst_L_Actl 1;
BA_ "U_U55X_MY2022_Rx" SG_ 982 LatCtlPathOffst_L_Actl 1;
BA_ "U_CD764_MY2022_Rx" SG_ 982 LatCtlPathOffst_L_Actl 1;
BA_ "U_CDX706_MY2023_Rx" SG_ 982 LatCtlPathOffst_L_Actl 1;
BA_ "U_T6_MCA_MY2020_Tx" SG_ 982 LatCtlPathOffst_L_Actl 1;
BA_ "U_U55X_MY2022_Tx" SG_ 982 LatCtlPathOffst_L_Actl 1;
BA_ "U_CD764_MY2022_Tx" SG_ 982 LatCtlPathOffst_L_Actl 1;
BA_ "U_CDX706_MY2023_Tx" SG_ 982 LatCtlPathOffst_L_Actl 1;
BA_ "GenSigStartValueInteger" SG_ 982 LatCtlPath_An_Actl 1000;
BA_ "U_T6_MCA_MY2020_Rx" SG_ 982 LatCtlPath_An_Actl 1;
BA_ "U_U55X_MY2022_Rx" SG_ 982 LatCtlPath_An_Actl 1;
BA_ "U_CD764_MY2022_Rx" SG_ 982 LatCtlPath_An_Actl 1;
BA_ "U_CDX706_MY2023_Rx" SG_ 982 LatCtlPath_An_Actl 1;
BA_ "U_T6_MCA_MY2020_Tx" SG_ 982 LatCtlPath_An_Actl 1;
BA_ "U_U55X_MY2022_Tx" SG_ 982 LatCtlPath_An_Actl 1;
BA_ "U_CD764_MY2022_Tx" SG_ 982 LatCtlPath_An_Actl 1;
BA_ "U_CDX706_MY2023_Tx" SG_ 982 LatCtlPath_An_Actl 1;
BA_ "GenSigStartValueInteger" SG_ 982 LatCtlCurv_No_Actl 1000;
BA_ "U_T6_MCA_MY2020_Rx" SG_ 982 LatCtlCurv_No_Actl 1;
BA_ "U_U55X_MY2022_Rx" SG_ 982 LatCtlCurv_No_Actl 1;
BA_ "U_CD764_MY2022_Rx" SG_ 982 LatCtlCurv_No_Actl 1;
BA_ "U_CDX706_MY2023_Rx" SG_ 982 LatCtlCurv_No_Actl 1;
BA_ "U_T6_MCA_MY2020_Tx" SG_ 982 LatCtlCurv_No_Actl 1;
BA_ "U_U55X_MY2022_Tx" SG_ 982 LatCtlCurv_No_Actl 1;
BA_ "U_CD764_MY2022_Tx" SG_ 982 LatCtlCurv_No_Actl 1;
BA_ "U_CDX706_MY2023_Tx" SG_ 982 LatCtlCurv_No_Actl 1;
BA_ "U_T6_MCA_MY2020_Rx" SG_ 982 HandsOffCnfm_B_Rq 1;
BA_ "U_U55X_MY2022_Rx" SG_ 982 HandsOffCnfm_B_Rq 1;
BA_ "U_CD764_MY2022_Rx" SG_ 982 HandsOffCnfm_B_Rq 1;
BA_ "U_CDX706_MY2023_Rx" SG_ 982 HandsOffCnfm_B_Rq 1;
BA_ "U_T6_MCA_MY2020_Tx" SG_ 982 HandsOffCnfm_B_Rq 1;
BA_ "U_U55X_MY2022_Tx" SG_ 982 HandsOffCnfm_B_Rq 1;
BA_ "U_CD764_MY2022_Tx" SG_ 982 HandsOffCnfm_B_Rq 1;
BA_ "U_CDX706_MY2023_Tx" SG_ 982 HandsOffCnfm_B_Rq 1;
BA_ "ContentDependant" SG_ 1104 DrvEngageLevel_No_Cs 1;
BA_ "MetaData" SG_ 1104 DrvEngageLevel_No_Cs 1;
BA_ "U_T6_MCA_MY2020_Rx" SG_ 1104 DrvEngageLevel_No_Cs 1;
BA_ "U_CD542_MY2021_Rx" SG_ 1104 DrvEngageLevel_No_Cs 1;
BA_ "U_U55X_MY2022_Rx" SG_ 1104 DrvEngageLevel_No_Cs 1;
BA_ "U_CD764_MY2022_Rx" SG_ 1104 DrvEngageLevel_No_Cs 1;
BA_ "U_CDX706_MY2023_Rx" SG_ 1104 DrvEngageLevel_No_Cs 1;
BA_ "U_T6_MCA_MY2020_Tx" SG_ 1104 DrvEngageLevel_No_Cs 1;
BA_ "U_CD542_MY2021_Tx" SG_ 1104 DrvEngageLevel_No_Cs 1;
BA_ "U_U55X_MY2022_Tx" SG_ 1104 DrvEngageLevel_No_Cs 1;
BA_ "U_CD764_MY2022_Tx" SG_ 1104 DrvEngageLevel_No_Cs 1;
BA_ "U_CDX706_MY2023_Tx" SG_ 1104 DrvEngageLevel_No_Cs 1;
BA_ "ContentDependant" SG_ 1104 DrvEngageLevel_No_Cnt 1;
BA_ "MetaData" SG_ 1104 DrvEngageLevel_No_Cnt 1;
BA_ "U_T6_MCA_MY2020_Rx" SG_ 1104 DrvEngageLevel_No_Cnt 1;
BA_ "U_CD542_MY2021_Rx" SG_ 1104 DrvEngageLevel_No_Cnt 1;
BA_ "U_U55X_MY2022_Rx" SG_ 1104 DrvEngageLevel_No_Cnt 1;
BA_ "U_CD764_MY2022_Rx" SG_ 1104 DrvEngageLevel_No_Cnt 1;
BA_ "U_CDX706_MY2023_Rx" SG_ 1104 DrvEngageLevel_No_Cnt 1;
BA_ "U_T6_MCA_MY2020_Tx" SG_ 1104 DrvEngageLevel_No_Cnt 1;
BA_ "U_CD542_MY2021_Tx" SG_ 1104 DrvEngageLevel_No_Cnt 1;
BA_ "U_U55X_MY2022_Tx" SG_ 1104 DrvEngageLevel_No_Cnt 1;
BA_ "U_CD764_MY2022_Tx" SG_ 1104 DrvEngageLevel_No_Cnt 1;
BA_ "U_CDX706_MY2023_Tx" SG_ 1104 DrvEngageLevel_No_Cnt 1;
BA_ "U_T6_MCA_MY2020_Rx" SG_ 1104 DrvEngageLevel_D_Stat 1;
BA_ "U_CD542_MY2021_Rx" SG_ 1104 DrvEngageLevel_D_Stat 1;
BA_ "U_U55X_MY2022_Rx" SG_ 1104 DrvEngageLevel_D_Stat 1;
BA_ "U_CD764_MY2022_Rx" SG_ 1104 DrvEngageLevel_D_Stat 1;
BA_ "U_CDX706_MY2023_Rx" SG_ 1104 DrvEngageLevel_D_Stat 1;
BA_ "U_T6_MCA_MY2020_Tx" SG_ 1104 DrvEngageLevel_D_Stat 1;
BA_ "U_CD542_MY2021_Tx" SG_ 1104 DrvEngageLevel_D_Stat 1;
BA_ "U_U55X_MY2022_Tx" SG_ 1104 DrvEngageLevel_D_Stat 1;
BA_ "U_CD764_MY2022_Tx" SG_ 1104 DrvEngageLevel_D_Stat 1;
BA_ "U_CDX706_MY2023_Tx" SG_ 1104 DrvEngageLevel_D_Stat 1;
BA_ "U_T6_MCA_MY2020_Rx" SG_ 1104 DrvImpLvlConfid_D_Stat 1;
BA_ "U_CD542_MY2021_Rx" SG_ 1104 DrvImpLvlConfid_D_Stat 1;
BA_ "U_U55X_MY2022_Rx" SG_ 1104 DrvImpLvlConfid_D_Stat 1;
BA_ "U_CD764_MY2022_Rx" SG_ 1104 DrvImpLvlConfid_D_Stat 1;
BA_ "U_CDX706_MY2023_Rx" SG_ 1104 DrvImpLvlConfid_D_Stat 1;
BA_ "U_T6_MCA_MY2020_Tx" SG_ 1104 DrvImpLvlConfid_D_Stat 1;
BA_ "U_CD542_MY2021_Tx" SG_ 1104 DrvImpLvlConfid_D_Stat 1;
BA_ "U_U55X_MY2022_Tx" SG_ 1104 DrvImpLvlConfid_D_Stat 1;
BA_ "U_CD764_MY2022_Tx" SG_ 1104 DrvImpLvlConfid_D_Stat 1;
BA_ "U_CDX706_MY2023_Tx" SG_ 1104 DrvImpLvlConfid_D_Stat 1;
BA_ "U_T6_MCA_MY2020_Rx" SG_ 1104 DrvImpairLvl_D_Stat 1;
BA_ "U_CD542_MY2021_Rx" SG_ 1104 DrvImpairLvl_D_Stat 1;
BA_ "U_U55X_MY2022_Rx" SG_ 1104 DrvImpairLvl_D_Stat 1;
BA_ "U_CD764_MY2022_Rx" SG_ 1104 DrvImpairLvl_D_Stat 1;
BA_ "U_CDX706_MY2023_Rx" SG_ 1104 DrvImpairLvl_D_Stat 1;
BA_ "U_T6_MCA_MY2020_Tx" SG_ 1104 DrvImpairLvl_D_Stat 1;
BA_ "U_CD542_MY2021_Tx" SG_ 1104 DrvImpairLvl_D_Stat 1;
BA_ "U_U55X_MY2022_Tx" SG_ 1104 DrvImpairLvl_D_Stat 1;
BA_ "U_CD764_MY2022_Tx" SG_ 1104 DrvImpairLvl_D_Stat 1;
BA_ "U_CDX706_MY2023_Tx" SG_ 1104 DrvImpairLvl_D_Stat 1;
BA_ "U_T6_MCA_MY2020_Rx" SG_ 1104 DrvEngLvlConfid_D_Stat 1;
BA_ "U_CD542_MY2021_Rx" SG_ 1104 DrvEngLvlConfid_D_Stat 1;
BA_ "U_U55X_MY2022_Rx" SG_ 1104 DrvEngLvlConfid_D_Stat 1;
BA_ "U_CD764_MY2022_Rx" SG_ 1104 DrvEngLvlConfid_D_Stat 1;
BA_ "U_CDX706_MY2023_Rx" SG_ 1104 DrvEngLvlConfid_D_Stat 1;
BA_ "U_T6_MCA_MY2020_Tx" SG_ 1104 DrvEngLvlConfid_D_Stat 1;
BA_ "U_CD542_MY2021_Tx" SG_ 1104 DrvEngLvlConfid_D_Stat 1;
BA_ "U_U55X_MY2022_Tx" SG_ 1104 DrvEngLvlConfid_D_Stat 1;
BA_ "U_CD764_MY2022_Tx" SG_ 1104 DrvEngLvlConfid_D_Stat 1;
BA_ "U_CDX706_MY2023_Tx" SG_ 1104 DrvEngLvlConfid_D_Stat 1;
BA_ "U_T6_MCA_MY2020_Rx" SG_ 1104 DrvCamPassIR_D_Stat 1;
BA_ "U_CD542_MY2021_Rx" SG_ 1104 DrvCamPassIR_D_Stat 1;
BA_ "U_U55X_MY2022_Rx" SG_ 1104 DrvCamPassIR_D_Stat 1;
BA_ "U_CD764_MY2022_Rx" SG_ 1104 DrvCamPassIR_D_Stat 1;
BA_ "U_CDX706_MY2023_Rx" SG_ 1104 DrvCamPassIR_D_Stat 1;
BA_ "U_T6_MCA_MY2020_Tx" SG_ 1104 DrvCamPassIR_D_Stat 1;
BA_ "U_CD542_MY2021_Tx" SG_ 1104 DrvCamPassIR_D_Stat 1;
BA_ "U_U55X_MY2022_Tx" SG_ 1104 DrvCamPassIR_D_Stat 1;
BA_ "U_CD764_MY2022_Tx" SG_ 1104 DrvCamPassIR_D_Stat 1;
BA_ "U_CDX706_MY2023_Tx" SG_ 1104 DrvCamPassIR_D_Stat 1;
BA_ "U_T6_MCA_MY2020_Rx" SG_ 1104 DrvCamera_D_Stat 1;
BA_ "U_CD542_MY2021_Rx" SG_ 1104 DrvCamera_D_Stat 1;
BA_ "U_U55X_MY2022_Rx" SG_ 1104 DrvCamera_D_Stat 1;
BA_ "U_CD764_MY2022_Rx" SG_ 1104 DrvCamera_D_Stat 1;
BA_ "U_CDX706_MY2023_Rx" SG_ 1104 DrvCamera_D_Stat 1;
BA_ "U_T6_MCA_MY2020_Tx" SG_ 1104 DrvCamera_D_Stat 1;
BA_ "U_CD542_MY2021_Tx" SG_ 1104 DrvCamera_D_Stat 1;
BA_ "U_U55X_MY2022_Tx" SG_ 1104 DrvCamera_D_Stat 1;
BA_ "U_CD764_MY2022_Tx" SG_ 1104 DrvCamera_D_Stat 1;
BA_ "U_CDX706_MY2023_Tx" SG_ 1104 DrvCamera_D_Stat 1;
BA_ "U_T6_MCA_MY2020_Rx" SG_ 1104 DrvCamDrvIR_D_Stat 1;
BA_ "U_CD542_MY2021_Rx" SG_ 1104 DrvCamDrvIR_D_Stat 1;
BA_ "U_U55X_MY2022_Rx" SG_ 1104 DrvCamDrvIR_D_Stat 1;
BA_ "U_CD764_MY2022_Rx" SG_ 1104 DrvCamDrvIR_D_Stat 1;
BA_ "U_CDX706_MY2023_Rx" SG_ 1104 DrvCamDrvIR_D_Stat 1;
BA_ "U_T6_MCA_MY2020_Tx" SG_ 1104 DrvCamDrvIR_D_Stat 1;
BA_ "U_CD542_MY2021_Tx" SG_ 1104 DrvCamDrvIR_D_Stat 1;
BA_ "U_U55X_MY2022_Tx" SG_ 1104 DrvCamDrvIR_D_Stat 1;
BA_ "U_CD764_MY2022_Tx" SG_ 1104 DrvCamDrvIR_D_Stat 1;
BA_ "U_CDX706_MY2023_Tx" SG_ 1104 DrvCamDrvIR_D_Stat 1;
BA_ "U_T6_MCA_MY2020_Rx" SG_ 1104 DrvAttentZone_D_Stat 1;
BA_ "U_CD542_MY2021_Rx" SG_ 1104 DrvAttentZone_D_Stat 1;
BA_ "U_U55X_MY2022_Rx" SG_ 1104 DrvAttentZone_D_Stat 1;
BA_ "U_CD764_MY2022_Rx" SG_ 1104 DrvAttentZone_D_Stat 1;
BA_ "U_CDX706_MY2023_Rx" SG_ 1104 DrvAttentZone_D_Stat 1;
BA_ "U_T6_MCA_MY2020_Tx" SG_ 1104 DrvAttentZone_D_Stat 1;
BA_ "U_CD542_MY2021_Tx" SG_ 1104 DrvAttentZone_D_Stat 1;
BA_ "U_U55X_MY2022_Tx" SG_ 1104 DrvAttentZone_D_Stat 1;
BA_ "U_CD764_MY2022_Tx" SG_ 1104 DrvAttentZone_D_Stat 1;
BA_ "U_CDX706_MY2023_Tx" SG_ 1104 DrvAttentZone_D_Stat 1;
BA_ "U_T6_MCA_MY2020_Rx" SG_ 1104 DrvAlertSt_D_Stat 1;
BA_ "U_CD542_MY2021_Rx" SG_ 1104 DrvAlertSt_D_Stat 1;
BA_ "U_U55X_MY2022_Rx" SG_ 1104 DrvAlertSt_D_Stat 1;
BA_ "U_CD764_MY2022_Rx" SG_ 1104 DrvAlertSt_D_Stat 1;
BA_ "U_CDX706_MY2023_Rx" SG_ 1104 DrvAlertSt_D_Stat 1;
BA_ "U_T6_MCA_MY2020_Tx" SG_ 1104 DrvAlertSt_D_Stat 1;
BA_ "U_CD542_MY2021_Tx" SG_ 1104 DrvAlertSt_D_Stat 1;
BA_ "U_U55X_MY2022_Tx" SG_ 1104 DrvAlertSt_D_Stat 1;
BA_ "U_CD764_MY2022_Tx" SG_ 1104 DrvAlertSt_D_Stat 1;
BA_ "U_CDX706_MY2023_Tx" SG_ 1104 DrvAlertSt_D_Stat 1;
BA_ "GenSigStartValue" SG_ 829 DcdcUHi3_I_Actl 2046;
BA_ "GenSigSendType" SG_ 2611070168 PARSEDPhysGWM_ECGtoHCM 3;
BA_ "U_U55X_MY2022_Rx" SG_ 2611070168 PARSEDPhysGWM_ECGtoHCM 1;
BA_ "U_CD764_MY2022_Rx" SG_ 2611070168 PARSEDPhysGWM_ECGtoHCM 1;
BA_ "ECGUsedTxSignal" SG_ 2611070168 PARSEDPhysGWM_ECGtoHCM 1;
BA_ "U_CD542_MY2021_Tx" SG_ 2611070168 PARSEDPhysGWM_ECGtoHCM 1;
BA_ "U_U55X_MY2022_Tx" SG_ 2611070168 PARSEDPhysGWM_ECGtoHCM 1;
BA_ "U_CD764_MY2022_Tx" SG_ 2611070168 PARSEDPhysGWM_ECGtoHCM 1;
BA_ "U_CDX706_MY2023_Tx" SG_ 2611070168 PARSEDPhysGWM_ECGtoHCM 1;
BA_ "GenSigSendType" SG_ 2611175537 PARSEDPhysHCMtoGWM_ECG 3;
BA_ "ECGUsedRxSignal" SG_ 2611175537 PARSEDPhysHCMtoGWM_ECG 1;
BA_ "U_CD542_MY2021_Rx" SG_ 2611175537 PARSEDPhysHCMtoGWM_ECG 1;
BA_ "U_U55X_MY2022_Rx" SG_ 2611175537 PARSEDPhysHCMtoGWM_ECG 1;
BA_ "U_CD764_MY2022_Rx" SG_ 2611175537 PARSEDPhysHCMtoGWM_ECG 1;
BA_ "U_CDX706_MY2023_Rx" SG_ 2611175537 PARSEDPhysHCMtoGWM_ECG 1;
BA_ "U_U55X_MY2022_Tx" SG_ 2611175537 PARSEDPhysHCMtoGWM_ECG 1;
BA_ "U_CD764_MY2022_Tx" SG_ 2611175537 PARSEDPhysHCMtoGWM_ECG 1;
BA_ "GenSigSendType" SG_ 2612224113 PARSEDPushHCMtoGWM_ECG 3;
BA_ "ECGUsedRxSignal" SG_ 2612224113 PARSEDPushHCMtoGWM_ECG 1;
BA_ "U_CD542_MY2021_Rx" SG_ 2612224113 PARSEDPushHCMtoGWM_ECG 1;
BA_ "U_U55X_MY2022_Rx" SG_ 2612224113 PARSEDPushHCMtoGWM_ECG 1;
BA_ "U_CD764_MY2022_Rx" SG_ 2612224113 PARSEDPushHCMtoGWM_ECG 1;
BA_ "U_CDX706_MY2023_Rx" SG_ 2612224113 PARSEDPushHCMtoGWM_ECG 1;
BA_ "U_U55X_MY2022_Tx" SG_ 2612224113 PARSEDPushHCMtoGWM_ECG 1;
BA_ "U_CD764_MY2022_Tx" SG_ 2612224113 PARSEDPushHCMtoGWM_ECG 1;
BA_ "GenSigSendType" SG_ 2610021592 OTAPhysGWM_ECGtoHCM 3;
BA_ "U_U55X_MY2022_Rx" SG_ 2610021592 OTAPhysGWM_ECGtoHCM 1;
BA_ "U_CD764_MY2022_Rx" SG_ 2610021592 OTAPhysGWM_ECGtoHCM 1;
BA_ "ECGUsedTxSignal" SG_ 2610021592 OTAPhysGWM_ECGtoHCM 1;
BA_ "U_CD542_MY2021_Tx" SG_ 2610021592 OTAPhysGWM_ECGtoHCM 1;
BA_ "U_U55X_MY2022_Tx" SG_ 2610021592 OTAPhysGWM_ECGtoHCM 1;
BA_ "U_CDX706_MY2023_Tx" SG_ 2610021592 OTAPhysGWM_ECGtoHCM 1;
BA_ "GenSigSendType" SG_ 2610126961 OTAPhysHCMtoGWM_ECG 3;
BA_ "ECGUsedRxSignal" SG_ 2610126961 OTAPhysHCMtoGWM_ECG 1;
BA_ "U_CD542_MY2021_Rx" SG_ 2610126961 OTAPhysHCMtoGWM_ECG 1;
BA_ "U_U55X_MY2022_Rx" SG_ 2610126961 OTAPhysHCMtoGWM_ECG 1;
BA_ "U_CD764_MY2022_Rx" SG_ 2610126961 OTAPhysHCMtoGWM_ECG 1;
BA_ "U_CDX706_MY2023_Rx" SG_ 2610126961 OTAPhysHCMtoGWM_ECG 1;
BA_ "U_U55X_MY2022_Tx" SG_ 2610126961 OTAPhysHCMtoGWM_ECG 1;
BA_ "U_CD764_MY2022_Tx" SG_ 2610126961 OTAPhysHCMtoGWM_ECG 1;
BA_ "GenSigSendType" SG_ 2610975960 PARSEDPhysGWM_ECGtoCCM 3;
BA_ "U_T6_MCA_MY2020_Rx" SG_ 2610975960 PARSEDPhysGWM_ECGtoCCM 1;
BA_ "U_CD542_MY2021_Rx" SG_ 2610975960 PARSEDPhysGWM_ECGtoCCM 1;
BA_ "U_U55X_MY2022_Rx" SG_ 2610975960 PARSEDPhysGWM_ECGtoCCM 1;
BA_ "U_CD764_MY2022_Rx" SG_ 2610975960 PARSEDPhysGWM_ECGtoCCM 1;
BA_ "U_CDX706_MY2023_Rx" SG_ 2610975960 PARSEDPhysGWM_ECGtoCCM 1;
BA_ "U_T6_MCA_MY2020_Tx" SG_ 2610975960 PARSEDPhysGWM_ECGtoCCM 1;
BA_ "ECGUsedTxSignal" SG_ 2610975960 PARSEDPhysGWM_ECGtoCCM 1;
BA_ "U_CD542_MY2021_Tx" SG_ 2610975960 PARSEDPhysGWM_ECGtoCCM 1;
BA_ "U_U55X_MY2022_Tx" SG_ 2610975960 PARSEDPhysGWM_ECGtoCCM 1;
BA_ "U_CDX706_MY2023_Tx" SG_ 2610975960 PARSEDPhysGWM_ECGtoCCM 1;
BA_ "GenSigSendType" SG_ 2611175445 PARSEDPhysCCMtoGWM_ECG 3;
BA_ "U_T6_MCA_MY2020_Rx" SG_ 2611175445 PARSEDPhysCCMtoGWM_ECG 1;
BA_ "ECGUsedRxSignal" SG_ 2611175445 PARSEDPhysCCMtoGWM_ECG 1;
BA_ "U_CD542_MY2021_Rx" SG_ 2611175445 PARSEDPhysCCMtoGWM_ECG 1;
BA_ "U_U55X_MY2022_Rx" SG_ 2611175445 PARSEDPhysCCMtoGWM_ECG 1;
BA_ "U_CDX706_MY2023_Rx" SG_ 2611175445 PARSEDPhysCCMtoGWM_ECG 1;
BA_ "U_T6_MCA_MY2020_Tx" SG_ 2611175445 PARSEDPhysCCMtoGWM_ECG 1;
BA_ "U_CD542_MY2021_Tx" SG_ 2611175445 PARSEDPhysCCMtoGWM_ECG 1;
BA_ "U_U55X_MY2022_Tx" SG_ 2611175445 PARSEDPhysCCMtoGWM_ECG 1;
BA_ "U_CD764_MY2022_Tx" SG_ 2611175445 PARSEDPhysCCMtoGWM_ECG 1;
BA_ "U_CDX706_MY2023_Tx" SG_ 2611175445 PARSEDPhysCCMtoGWM_ECG 1;
BA_ "GenSigSendType" SG_ 2612224021 PARSEDPushCCMtoGWM_ECG 3;
BA_ "U_T6_MCA_MY2020_Rx" SG_ 2612224021 PARSEDPushCCMtoGWM_ECG 1;
BA_ "ECGUsedRxSignal" SG_ 2612224021 PARSEDPushCCMtoGWM_ECG 1;
BA_ "U_CD542_MY2021_Rx" SG_ 2612224021 PARSEDPushCCMtoGWM_ECG 1;
BA_ "U_U55X_MY2022_Rx" SG_ 2612224021 PARSEDPushCCMtoGWM_ECG 1;
BA_ "U_CDX706_MY2023_Rx" SG_ 2612224021 PARSEDPushCCMtoGWM_ECG 1;
BA_ "U_T6_MCA_MY2020_Tx" SG_ 2612224021 PARSEDPushCCMtoGWM_ECG 1;
BA_ "U_CD542_MY2021_Tx" SG_ 2612224021 PARSEDPushCCMtoGWM_ECG 1;
BA_ "U_U55X_MY2022_Tx" SG_ 2612224021 PARSEDPushCCMtoGWM_ECG 1;
BA_ "U_CD764_MY2022_Tx" SG_ 2612224021 PARSEDPushCCMtoGWM_ECG 1;
BA_ "U_CDX706_MY2023_Tx" SG_ 2612224021 PARSEDPushCCMtoGWM_ECG 1;
BA_ "GenSigSendType" SG_ 2611025112 PARSEDPhysGWM_ECGtoSODCMC 3;
BA_ "U_T6_MCA_MY2020_Rx" SG_ 2611025112 PARSEDPhysGWM_ECGtoSODCMC 1;
BA_ "U_U55X_MY2022_Rx" SG_ 2611025112 PARSEDPhysGWM_ECGtoSODCMC 1;
BA_ "U_CDX706_MY2023_Rx" SG_ 2611025112 PARSEDPhysGWM_ECGtoSODCMC 1;
BA_ "U_T6_MCA_MY2020_Tx" SG_ 2611025112 PARSEDPhysGWM_ECGtoSODCMC 1;
BA_ "ECGUsedTxSignal" SG_ 2611025112 PARSEDPhysGWM_ECGtoSODCMC 1;
BA_ "U_CD542_MY2021_Tx" SG_ 2611025112 PARSEDPhysGWM_ECGtoSODCMC 1;
BA_ "U_U55X_MY2022_Tx" SG_ 2611025112 PARSEDPhysGWM_ECGtoSODCMC 1;
BA_ "U_CDX706_MY2023_Tx" SG_ 2611025112 PARSEDPhysGWM_ECGtoSODCMC 1;
BA_ "GenSigSendType" SG_ 2611175493 PARSEDPhysSODCMCtoGWM_ECG 3;
BA_ "U_T6_MCA_MY2020_Rx" SG_ 2611175493 PARSEDPhysSODCMCtoGWM_ECG 1;
BA_ "ECGUsedRxSignal" SG_ 2611175493 PARSEDPhysSODCMCtoGWM_ECG 1;
BA_ "U_CD542_MY2021_Rx" SG_ 2611175493 PARSEDPhysSODCMCtoGWM_ECG 1;
BA_ "U_U55X_MY2022_Rx" SG_ 2611175493 PARSEDPhysSODCMCtoGWM_ECG 1;
BA_ "U_CDX706_MY2023_Rx" SG_ 2611175493 PARSEDPhysSODCMCtoGWM_ECG 1;
BA_ "U_T6_MCA_MY2020_Tx" SG_ 2611175493 PARSEDPhysSODCMCtoGWM_ECG 1;
BA_ "U_CD542_MY2021_Tx" SG_ 2611175493 PARSEDPhysSODCMCtoGWM_ECG 1;
BA_ "U_U55X_MY2022_Tx" SG_ 2611175493 PARSEDPhysSODCMCtoGWM_ECG 1;
BA_ "U_CD764_MY2022_Tx" SG_ 2611175493 PARSEDPhysSODCMCtoGWM_ECG 1;
BA_ "U_CDX706_MY2023_Tx" SG_ 2611175493 PARSEDPhysSODCMCtoGWM_ECG 1;
BA_ "GenSigSendType" SG_ 2612224069 PARSEDPushSODCMCtoGWM 3;
BA_ "U_T6_MCA_MY2020_Rx" SG_ 2612224069 PARSEDPushSODCMCtoGWM 1;
BA_ "ECGUsedRxSignal" SG_ 2612224069 PARSEDPushSODCMCtoGWM 1;
BA_ "U_CD542_MY2021_Rx" SG_ 2612224069 PARSEDPushSODCMCtoGWM 1;
BA_ "U_U55X_MY2022_Rx" SG_ 2612224069 PARSEDPushSODCMCtoGWM 1;
BA_ "U_CDX706_MY2023_Rx" SG_ 2612224069 PARSEDPushSODCMCtoGWM 1;
BA_ "U_T6_MCA_MY2020_Tx" SG_ 2612224069 PARSEDPushSODCMCtoGWM 1;
BA_ "U_CD542_MY2021_Tx" SG_ 2612224069 PARSEDPushSODCMCtoGWM 1;
BA_ "U_U55X_MY2022_Tx" SG_ 2612224069 PARSEDPushSODCMCtoGWM 1;
BA_ "U_CD764_MY2022_Tx" SG_ 2612224069 PARSEDPushSODCMCtoGWM 1;
BA_ "U_CDX706_MY2023_Tx" SG_ 2612224069 PARSEDPushSODCMCtoGWM 1;
BA_ "GenSigSendType" SG_ 1787 TesterPhysicalResSODCMD 3;
BA_ "U_T6_MCA_MY2020_Tx" SG_ 1787 TesterPhysicalResSODCMD 1;
BA_ "U_CD542_MY2021_Tx" SG_ 1787 TesterPhysicalResSODCMD 1;
BA_ "U_U55X_MY2022_Tx" SG_ 1787 TesterPhysicalResSODCMD 1;
BA_ "U_CD764_MY2022_Tx" SG_ 1787 TesterPhysicalResSODCMD 1;
BA_ "U_CDX706_MY2023_Tx" SG_ 1787 TesterPhysicalResSODCMD 1;
BA_ "GenSigSendType" SG_ 1779 TesterPhysicalReqSODCMD 3;
BA_ "U_T6_MCA_MY2020_Rx" SG_ 1779 TesterPhysicalReqSODCMD 1;
BA_ "U_CD542_MY2021_Rx" SG_ 1779 TesterPhysicalReqSODCMD 1;
BA_ "U_U55X_MY2022_Rx" SG_ 1779 TesterPhysicalReqSODCMD 1;
BA_ "U_CD764_MY2022_Rx" SG_ 1779 TesterPhysicalReqSODCMD 1;
BA_ "U_CDX706_MY2023_Rx" SG_ 1779 TesterPhysicalReqSODCMD 1;
BA_ "GenSigSendType" SG_ 1786 TesterPhysicalResSODCMC 3;
BA_ "U_T6_MCA_MY2020_Tx" SG_ 1786 TesterPhysicalResSODCMC 1;
BA_ "U_CD542_MY2021_Tx" SG_ 1786 TesterPhysicalResSODCMC 1;
BA_ "U_U55X_MY2022_Tx" SG_ 1786 TesterPhysicalResSODCMC 1;
BA_ "U_CD764_MY2022_Tx" SG_ 1786 TesterPhysicalResSODCMC 1;
BA_ "U_CDX706_MY2023_Tx" SG_ 1786 TesterPhysicalResSODCMC 1;
BA_ "GenSigStartValueInteger" SG_ 1089 Mtr2Aout_W_ActlMntr 1023;
BA_ "GenSigStartValue" SG_ 1089 Mtr2Aout_W_ActlMntr 1023;
BA_ "ECGUsedRxSignal" SG_ 1089 Mtr2Aout_W_ActlMntr 1;
BA_ "U_CD542_MY2021_Rx" SG_ 1089 Mtr2Aout_W_ActlMntr 1;
BA_ "U_U55X_MY2022_Rx" SG_ 1089 Mtr2Aout_W_ActlMntr 1;
BA_ "U_CDX706_MY2023_Rx" SG_ 1089 Mtr2Aout_W_ActlMntr 1;
BA_ "U_CX727_MY2021_Tx" SG_ 1089 Mtr2Aout_W_ActlMntr 1;
BA_ "U_P702_MY2021_Tx" SG_ 1089 Mtr2Aout_W_ActlMntr 1;
BA_ "U_CD542_MY2021_Tx" SG_ 1089 Mtr2Aout_W_ActlMntr 1;
BA_ "U_CDX706_MY2023_Tx" SG_ 1089 Mtr2Aout_W_ActlMntr 1;
BA_ "GenSigStartValueInteger" SG_ 1089 Inv1_Te_Actl 254;
BA_ "GenSigStartValue" SG_ 1089 Inv1_Te_Actl 254;
BA_ "U_CX727_MY2021_Tx" SG_ 1089 Inv1_Te_Actl 1;
BA_ "U_P702_MY2021_Tx" SG_ 1089 Inv1_Te_Actl 1;
BA_ "U_CD542_MY2021_Tx" SG_ 1089 Inv1_Te_Actl 1;
BA_ "U_CDX706_MY2023_Tx" SG_ 1089 Inv1_Te_Actl 1;
BA_ "GenSigStartValueInteger" SG_ 1089 MtrTrac2Coil_Te_Actl 254;
BA_ "GenSigStartValue" SG_ 1089 MtrTrac2Coil_Te_Actl 254;
BA_ "ECGUsedRxSignal" SG_ 1089 MtrTrac2Coil_Te_Actl 1;
BA_ "U_CD542_MY2021_Rx" SG_ 1089 MtrTrac2Coil_Te_Actl 1;
BA_ "U_U55X_MY2022_Rx" SG_ 1089 MtrTrac2Coil_Te_Actl 1;
BA_ "U_CDX706_MY2023_Rx" SG_ 1089 MtrTrac2Coil_Te_Actl 1;
BA_ "U_CX727_MY2021_Tx" SG_ 1089 MtrTrac2Coil_Te_Actl 1;
BA_ "U_P702_MY2021_Tx" SG_ 1089 MtrTrac2Coil_Te_Actl 1;
BA_ "U_CD542_MY2021_Tx" SG_ 1089 MtrTrac2Coil_Te_Actl 1;
BA_ "U_CDX706_MY2023_Tx" SG_ 1089 MtrTrac2Coil_Te_Actl 1;
BA_ "GenSigStartValueInteger" SG_ 1089 MtrTrac2_U_Actl 1023;
BA_ "GenSigStartValue" SG_ 1089 MtrTrac2_U_Actl 1023;
BA_ "U_CX727_MY2021_Tx" SG_ 1089 MtrTrac2_U_Actl 1;
BA_ "U_P702_MY2021_Tx" SG_ 1089 MtrTrac2_U_Actl 1;
BA_ "U_CD542_MY2021_Tx" SG_ 1089 MtrTrac2_U_Actl 1;
BA_ "U_CDX706_MY2023_Tx" SG_ 1089 MtrTrac2_U_Actl 1;
BA_ "U_CX727_MY2021_Tx" SG_ 1089 MtrTrac2Falt_B_Stat 1;
BA_ "U_P702_MY2021_Tx" SG_ 1089 MtrTrac2Falt_B_Stat 1;
BA_ "U_CD542_MY2021_Tx" SG_ 1089 MtrTrac2Falt_B_Stat 1;
BA_ "U_CDX706_MY2023_Tx" SG_ 1089 MtrTrac2Falt_B_Stat 1;
BA_ "ECGUsedRxSignal" SG_ 1089 MtrTrac2TeAlrm_B_Stat 1;
BA_ "U_CD542_MY2021_Rx" SG_ 1089 MtrTrac2TeAlrm_B_Stat 1;
BA_ "U_U55X_MY2022_Rx" SG_ 1089 MtrTrac2TeAlrm_B_Stat 1;
BA_ "U_CDX706_MY2023_Rx" SG_ 1089 MtrTrac2TeAlrm_B_Stat 1;
BA_ "U_CX727_MY2021_Tx" SG_ 1089 MtrTrac2TeAlrm_B_Stat 1;
BA_ "U_P702_MY2021_Tx" SG_ 1089 MtrTrac2TeAlrm_B_Stat 1;
BA_ "U_CD542_MY2021_Tx" SG_ 1089 MtrTrac2TeAlrm_B_Stat 1;
BA_ "U_CDX706_MY2023_Tx" SG_ 1089 MtrTrac2TeAlrm_B_Stat 1;
BA_ "ECGUsedRxSignal" SG_ 1089 Mtr2CntlTeAlrm_B_Stat 1;
BA_ "U_CD542_MY2021_Rx" SG_ 1089 Mtr2CntlTeAlrm_B_Stat 1;
BA_ "U_U55X_MY2022_Rx" SG_ 1089 Mtr2CntlTeAlrm_B_Stat 1;
BA_ "U_CDX706_MY2023_Rx" SG_ 1089 Mtr2CntlTeAlrm_B_Stat 1;
BA_ "U_CX727_MY2021_Tx" SG_ 1089 Mtr2CntlTeAlrm_B_Stat 1;
BA_ "U_P702_MY2021_Tx" SG_ 1089 Mtr2CntlTeAlrm_B_Stat 1;
BA_ "U_CD542_MY2021_Tx" SG_ 1089 Mtr2CntlTeAlrm_B_Stat 1;
BA_ "U_CDX706_MY2023_Tx" SG_ 1089 Mtr2CntlTeAlrm_B_Stat 1;
BA_ "GenSigStartValueInteger" SG_ 1089 MtrTrac2Inv_Te_Actl 214;
BA_ "GenSigStartValue" SG_ 1089 MtrTrac2Inv_Te_Actl 214;
BA_ "ECGUsedRxSignal" SG_ 1089 MtrTrac2Inv_Te_Actl 1;
BA_ "U_CD542_MY2021_Rx" SG_ 1089 MtrTrac2Inv_Te_Actl 1;
BA_ "U_U55X_MY2022_Rx" SG_ 1089 MtrTrac2Inv_Te_Actl 1;
BA_ "U_CDX706_MY2023_Rx" SG_ 1089 MtrTrac2Inv_Te_Actl 1;
BA_ "U_CX727_MY2021_Tx" SG_ 1089 MtrTrac2Inv_Te_Actl 1;
BA_ "U_P702_MY2021_Tx" SG_ 1089 MtrTrac2Inv_Te_Actl 1;
BA_ "U_CD542_MY2021_Tx" SG_ 1089 MtrTrac2Inv_Te_Actl 1;
BA_ "U_CDX706_MY2023_Tx" SG_ 1089 MtrTrac2Inv_Te_Actl 1;
BA_ "GenSigStartValueInteger" SG_ 1089 MtrTrac2_I_Actl 10000;
BA_ "U_CX727_MY2021_Tx" SG_ 1089 MtrTrac2_I_Actl 1;
BA_ "U_P702_MY2021_Tx" SG_ 1089 MtrTrac2_I_Actl 1;
BA_ "U_CD542_MY2021_Tx" SG_ 1089 MtrTrac2_I_Actl 1;
BA_ "U_CDX706_MY2023_Tx" SG_ 1089 MtrTrac2_I_Actl 1;
BA_ "GenSigSendType" SG_ 1778 TesterPhysicalReqSODCMC 3;
BA_ "U_T6_MCA_MY2020_Rx" SG_ 1778 TesterPhysicalReqSODCMC 1;
BA_ "U_CD542_MY2021_Rx" SG_ 1778 TesterPhysicalReqSODCMC 1;
BA_ "U_U55X_MY2022_Rx" SG_ 1778 TesterPhysicalReqSODCMC 1;
BA_ "U_CD764_MY2022_Rx" SG_ 1778 TesterPhysicalReqSODCMC 1;
BA_ "U_CDX706_MY2023_Rx" SG_ 1778 TesterPhysicalReqSODCMC 1;
BA_ "GenSigSendType" SG_ 776 ScMnSoc_Pc_RqCld 3;
BA_ "GenSigStartValue" SG_ 776 ScMnSoc_Pc_RqCld 100;
BA_ "ECGUsedTxSignal" SG_ 776 ScMnSoc_Pc_RqCld 1;
BA_ "U_CD542_MY2021_Tx" SG_ 776 ScMnSoc_Pc_RqCld 1;
BA_ "U_U55X_MY2022_Tx" SG_ 776 ScMnSoc_Pc_RqCld 1;
BA_ "ECGUsedTxSignal" SG_ 776 ScChrgrPwMax_Pw_RqCld 1;
BA_ "U_CD542_MY2021_Tx" SG_ 776 ScChrgrPwMax_Pw_RqCld 1;
BA_ "U_U55X_MY2022_Tx" SG_ 776 ScChrgrPwMax_Pw_RqCld 1;
BA_ "GenSigSendType" SG_ 776 ScLocPwId_No_RqCld 3;
BA_ "ECGUsedTxSignal" SG_ 776 ScLocPwId_No_RqCld 1;
BA_ "U_CD542_MY2021_Tx" SG_ 776 ScLocPwId_No_RqCld 1;
BA_ "U_U55X_MY2022_Tx" SG_ 776 ScLocPwId_No_RqCld 1;
BA_ "GenSigSendType" SG_ 776 PrcondEdit_D_RqCld 3;
BA_ "ECGUsedTxSignal" SG_ 776 PrcondEdit_D_RqCld 1;
BA_ "U_CD542_MY2021_Tx" SG_ 776 PrcondEdit_D_RqCld 1;
BA_ "U_U55X_MY2022_Tx" SG_ 776 PrcondEdit_D_RqCld 1;
BA_ "GenSigSendType" SG_ 776 GoTEditMnte_T_RqCld 3;
BA_ "GenSigStartValue" SG_ 776 GoTEditMnte_T_RqCld 14;
BA_ "ECGUsedTxSignal" SG_ 776 GoTEditMnte_T_RqCld 1;
BA_ "U_CD542_MY2021_Tx" SG_ 776 GoTEditMnte_T_RqCld 1;
BA_ "U_U55X_MY2022_Tx" SG_ 776 GoTEditMnte_T_RqCld 1;
BA_ "GenSigSendType" SG_ 776 GoTEditHr_T_RqCld 3;
BA_ "GenSigStartValue" SG_ 776 GoTEditHr_T_RqCld 30;
BA_ "ECGUsedTxSignal" SG_ 776 GoTEditHr_T_RqCld 1;
BA_ "U_CD542_MY2021_Tx" SG_ 776 GoTEditHr_T_RqCld 1;
BA_ "U_U55X_MY2022_Tx" SG_ 776 GoTEditHr_T_RqCld 1;
BA_ "GenSigSendType" SG_ 776 ChrgToPcEdit_Pc_RqCld 3;
BA_ "GenSigStartValue" SG_ 776 ChrgToPcEdit_Pc_RqCld 126;
BA_ "ECGUsedTxSignal" SG_ 776 ChrgToPcEdit_Pc_RqCld 1;
BA_ "U_CD542_MY2021_Tx" SG_ 776 ChrgToPcEdit_Pc_RqCld 1;
BA_ "U_U55X_MY2022_Tx" SG_ 776 ChrgToPcEdit_Pc_RqCld 1;
BA_ "GenSigSendType" SG_ 776 AirAmb_Te_ActlCld 3;
BA_ "GenSigStartValueInteger" SG_ 776 AirAmb_Te_ActlCld 512;
BA_ "ECGUsedTxSignal" SG_ 776 AirAmb_Te_ActlCld 1;
BA_ "U_CD542_MY2021_Tx" SG_ 776 AirAmb_Te_ActlCld 1;
BA_ "U_U55X_MY2022_Tx" SG_ 776 AirAmb_Te_ActlCld 1;
BA_ "GenSigSendType" SG_ 776 ScFreshDataEnbl_B_Rq 3;
BA_ "ECGUsedTxSignal" SG_ 776 ScFreshDataEnbl_B_Rq 1;
BA_ "U_CD542_MY2021_Tx" SG_ 776 ScFreshDataEnbl_B_Rq 1;
BA_ "U_U55X_MY2022_Tx" SG_ 776 ScFreshDataEnbl_B_Rq 1;
BA_ "GenSigSendType" SG_ 776 ScEnbl_D_RqCld 3;
BA_ "GenSigStartValue" SG_ 776 ScEnbl_D_RqCld 1;
BA_ "ECGUsedTxSignal" SG_ 776 ScEnbl_D_RqCld 1;
BA_ "U_CD542_MY2021_Tx" SG_ 776 ScEnbl_D_RqCld 1;
BA_ "U_U55X_MY2022_Tx" SG_ 776 ScEnbl_D_RqCld 1;
BA_ "GenSigStartValue" SG_ 1088 TrlrRng_L_Dsply 8190;
BA_ "WakeupSignal" SG_ 1088 ChrgStat_D2_Dsply 1;
BA_ "ECGUsedRxSignal" SG_ 1088 ChrgStat_D2_Dsply 1;
BA_ "U_CD542_MY2021_Rx" SG_ 1088 ChrgStat_D2_Dsply 1;
BA_ "U_U55X_MY2022_Rx" SG_ 1088 ChrgStat_D2_Dsply 1;
BA_ "U_CD764_MY2022_Rx" SG_ 1088 ChrgStat_D2_Dsply 1;
BA_ "U_CX727_MY2021_Tx" SG_ 1088 ChrgStat_D2_Dsply 1;
BA_ "U_P702_MY2021_Tx" SG_ 1088 ChrgStat_D2_Dsply 1;
BA_ "U_CD542_MY2021_Tx" SG_ 1088 ChrgStat_D2_Dsply 1;
BA_ "U_CX727_MY2021_Tx" SG_ 1088 ChrgTMatch_B_Stat 1;
BA_ "U_CD542_MY2021_Tx" SG_ 1088 ChrgTMatch_B_Stat 1;
BA_ "U_CX727_MY2021_Tx" SG_ 1088 HvacPrecondRecirc_D_Rq 1;
BA_ "U_P702_MY2021_Tx" SG_ 1088 HvacPrecondRecirc_D_Rq 1;
BA_ "U_CD542_MY2021_Tx" SG_ 1088 HvacPrecondRecirc_D_Rq 1;
BA_ "WakeupSignal" SG_ 1088 HvacPrecondMode2_D_Rq 1;
BA_ "ContentDependant" SG_ 1088 HvacPrecondMode2_D_Rq 1;
BA_ "U_CX727_MY2021_Tx" SG_ 1088 HvacPrecondMode2_D_Rq 1;
BA_ "U_P702_MY2021_Tx" SG_ 1088 HvacPrecondMode2_D_Rq 1;
BA_ "U_CD542_MY2021_Tx" SG_ 1088 HvacPrecondMode2_D_Rq 1;
BA_ "WakeupSignal" SG_ 1088 HvacPrecondBlwr2_D_Rq 1;
BA_ "ContentDependant" SG_ 1088 HvacPrecondBlwr2_D_Rq 1;
BA_ "U_CX727_MY2021_Tx" SG_ 1088 HvacPrecondBlwr2_D_Rq 1;
BA_ "U_P702_MY2021_Tx" SG_ 1088 HvacPrecondBlwr2_D_Rq 1;
BA_ "U_CD542_MY2021_Tx" SG_ 1088 HvacPrecondBlwr2_D_Rq 1;
BA_ "U_CX727_MY2021_Tx" SG_ 1088 HvacPrecondAC_D_Rq 1;
BA_ "U_P702_MY2021_Tx" SG_ 1088 HvacPrecondAC_D_Rq 1;
BA_ "U_CD542_MY2021_Tx" SG_ 1088 HvacPrecondAC_D_Rq 1;
BA_ "GenSigStartValueInteger" SG_ 1088 HvacPrecond_Te_Rq 2;
BA_ "GenSigStartValue" SG_ 1088 HvacPrecond_Te_Rq 2;
BA_ "U_CX727_MY2021_Tx" SG_ 1088 HvacPrecond_Te_Rq 1;
BA_ "U_P702_MY2021_Tx" SG_ 1088 HvacPrecond_Te_Rq 1;
BA_ "U_CD542_MY2021_Tx" SG_ 1088 HvacPrecond_Te_Rq 1;
BA_ "U_CX727_MY2021_Tx" SG_ 1088 BattChrgInhbt_D_Rq 1;
BA_ "U_P702_MY2021_Tx" SG_ 1088 BattChrgInhbt_D_Rq 1;
BA_ "U_CD542_MY2021_Tx" SG_ 1088 BattChrgInhbt_D_Rq 1;
BA_ "GenSigStartValue" SG_ 1088 BattDcChrgRms_I_Lim 32766;
BA_ "GenSigStartValue" SG_ 850 VehElRngeNut_L2_Dsply 8190;
BA_ "U_CX727_MY2021_Tx" SG_ 850 VehElRngeNut_L_Dsply 1;
BA_ "U_CD542_MY2021_Tx" SG_ 850 VehElRngeNut_L_Dsply 1;
BA_ "U_CX727_MY2021_Tx" SG_ 850 NxtUsgSocEst_Pc_Dsply 1;
BA_ "U_CD542_MY2021_Tx" SG_ 850 NxtUsgSocEst_Pc_Dsply 1;
BA_ "ECGUsedRxSignal" SG_ 850 EstmChrgTimeLP_St 1;
BA_ "U_CD542_MY2021_Rx" SG_ 850 EstmChrgTimeLP_St 1;
BA_ "U_U55X_MY2022_Rx" SG_ 850 EstmChrgTimeLP_St 1;
BA_ "U_CX727_MY2021_Tx" SG_ 850 EstmChrgTimeLP_St 1;
BA_ "U_CD542_MY2021_Tx" SG_ 850 EstmChrgTimeLP_St 1;
BA_ "ECGUsedRxSignal" SG_ 850 EstmChrgTimeHP_St 1;
BA_ "U_CD542_MY2021_Rx" SG_ 850 EstmChrgTimeHP_St 1;
BA_ "U_U55X_MY2022_Rx" SG_ 850 EstmChrgTimeHP_St 1;
BA_ "U_CX727_MY2021_Tx" SG_ 850 EstmChrgTimeHP_St 1;
BA_ "U_CD542_MY2021_Tx" SG_ 850 EstmChrgTimeHP_St 1;
BA_ "ECGUsedRxSignal" SG_ 850 ChargeNowDuration_St 1;
BA_ "U_CD542_MY2021_Rx" SG_ 850 ChargeNowDuration_St 1;
BA_ "U_U55X_MY2022_Rx" SG_ 850 ChargeNowDuration_St 1;
BA_ "U_CX727_MY2021_Tx" SG_ 850 ChargeNowDuration_St 1;
BA_ "U_CD542_MY2021_Tx" SG_ 850 ChargeNowDuration_St 1;
BA_ "GenSigStartValueInteger" SG_ 1070 BattULo24_Te_Actl 127;
BA_ "GenSigStartValue" SG_ 1070 BattULo24_Te_Actl 127;
BA_ "U_CDX706_MY2023_Rx" SG_ 1070 BattULo24_Te_Actl 1;
BA_ "GenSigStartValueInteger" SG_ 1070 BattULo24State_D_Qlty 1;
BA_ "GenSigStartValue" SG_ 1070 BattULo24State_D_Qlty 1;
BA_ "U_P702_MY2021_Rx" SG_ 1070 BattULo24State_D_Qlty 1;
BA_ "U_CDX706_MY2023_Rx" SG_ 1070 BattULo24State_D_Qlty 1;
BA_ "U_P702_MY2021_Rx" SG_ 1070 BattULo24Soc_Pc_Actl 1;
BA_ "U_CDX706_MY2023_Rx" SG_ 1070 BattULo24Soc_Pc_Actl 1;
BA_ "GenSigStartValue" SG_ 1070 BattULo24_I_Actl 8192;
BA_ "U_P702_MY2021_Rx" SG_ 1070 BattULo24_I_Actl 1;
BA_ "U_CDX706_MY2023_Rx" SG_ 1070 BattULo24_I_Actl 1;
BA_ "U_P702_MY2021_Rx" SG_ 1070 BattULo24_B_Falt 1;
BA_ "U_CDX706_MY2023_Rx" SG_ 1070 BattULo24_B_Falt 1;
BA_ "GenSigStartValue" SG_ 1070 BattULo24_Ah_DeltaRide 12800;
BA_ "U_P702_MY2021_Rx" SG_ 1070 BattULo24_Ah_DeltaRide 1;
BA_ "U_CDX706_MY2023_Rx" SG_ 1070 BattULo24_Ah_DeltaRide 1;
BA_ "U_CDX706_MY2023_Rx" SG_ 1070 BattULo24_D_Falt 1;
BA_ "GenSigStartValueInteger" SG_ 868 BattRgenLoStat_D_Qlty 1;
BA_ "GenSigStartValue" SG_ 868 BattRgenLoStat_D_Qlty 1;
BA_ "U_P702_MY2021_Rx" SG_ 868 BattRgenLoStat_D_Qlty 1;
BA_ "GenSigStartValueInteger" SG_ 868 BattRgenLoSoc_Pc_Actl 50;
BA_ "GenSigStartValue" SG_ 868 BattRgenLoSoc_Pc_Actl 50;
BA_ "U_P702_MY2021_Rx" SG_ 868 BattRgenLoSoc_Pc_Actl 1;
BA_ "GenSigStartValue" SG_ 868 BattRgenLoPulse_U_Pred 216;
BA_ "U_P702_MY2021_Rx" SG_ 868 BattRgenLoPulse_U_Pred 1;
BA_ "U_P702_MY2021_Rx" SG_ 868 BattRgenLoPrtct_B_Stat 1;
BA_ "U_P702_MY2021_Rx" SG_ 868 BattRgenLoDChrg_D_Stat 1;
BA_ "U_P702_MY2021_Rx" SG_ 868 BattRgenLoDchrg_B_Rq 1;
BA_ "U_P702_MY2021_Rx" SG_ 868 BattRgenLoChrg_D_Stat 1;
BA_ "U_P702_MY2021_Rx" SG_ 868 BattRgenLoChrg_B_Rq 1;
BA_ "U_P702_MY2021_Rx" SG_ 868 BattRgenLo_T_Est 1;
BA_ "U_P702_MY2021_Rx" SG_ 868 BattRgenLo_B_Falt 1;
BA_ "GenSigSendType" SG_ 1795 TesterPhysicalReqAWD 3;
BA_ "U_T6_MCA_MY2020_Rx" SG_ 1795 TesterPhysicalReqAWD 1;
BA_ "GenSigSendType" SG_ 1803 TesterPhysicalResAWD 3;
BA_ "U_T6_MCA_MY2020_Tx" SG_ 1803 TesterPhysicalResAWD 1;
BA_ "GenSigSendType" SG_ 2611026136 PARSEDPhysGWM_ECGtoSODCMD 3;
BA_ "U_T6_MCA_MY2020_Rx" SG_ 2611026136 PARSEDPhysGWM_ECGtoSODCMD 1;
BA_ "U_CD542_MY2021_Rx" SG_ 2611026136 PARSEDPhysGWM_ECGtoSODCMD 1;
BA_ "U_U55X_MY2022_Rx" SG_ 2611026136 PARSEDPhysGWM_ECGtoSODCMD 1;
BA_ "U_CD764_MY2022_Rx" SG_ 2611026136 PARSEDPhysGWM_ECGtoSODCMD 1;
BA_ "U_CDX706_MY2023_Rx" SG_ 2611026136 PARSEDPhysGWM_ECGtoSODCMD 1;
BA_ "U_T6_MCA_MY2020_Tx" SG_ 2611026136 PARSEDPhysGWM_ECGtoSODCMD 1;
BA_ "ECGUsedTxSignal" SG_ 2611026136 PARSEDPhysGWM_ECGtoSODCMD 1;
BA_ "U_CD542_MY2021_Tx" SG_ 2611026136 PARSEDPhysGWM_ECGtoSODCMD 1;
BA_ "U_U55X_MY2022_Tx" SG_ 2611026136 PARSEDPhysGWM_ECGtoSODCMD 1;
BA_ "U_CDX706_MY2023_Tx" SG_ 2611026136 PARSEDPhysGWM_ECGtoSODCMD 1;
BA_ "GenSigSendType" SG_ 2611175494 PARSEDPhysSODCMDtoGWM_ECG 3;
BA_ "U_T6_MCA_MY2020_Rx" SG_ 2611175494 PARSEDPhysSODCMDtoGWM_ECG 1;
BA_ "ECGUsedRxSignal" SG_ 2611175494 PARSEDPhysSODCMDtoGWM_ECG 1;
BA_ "U_CD542_MY2021_Rx" SG_ 2611175494 PARSEDPhysSODCMDtoGWM_ECG 1;
BA_ "U_U55X_MY2022_Rx" SG_ 2611175494 PARSEDPhysSODCMDtoGWM_ECG 1;
BA_ "U_CDX706_MY2023_Rx" SG_ 2611175494 PARSEDPhysSODCMDtoGWM_ECG 1;
BA_ "U_T6_MCA_MY2020_Tx" SG_ 2611175494 PARSEDPhysSODCMDtoGWM_ECG 1;
BA_ "U_CD542_MY2021_Tx" SG_ 2611175494 PARSEDPhysSODCMDtoGWM_ECG 1;
BA_ "U_U55X_MY2022_Tx" SG_ 2611175494 PARSEDPhysSODCMDtoGWM_ECG 1;
BA_ "U_CD764_MY2022_Tx" SG_ 2611175494 PARSEDPhysSODCMDtoGWM_ECG 1;
BA_ "U_CDX706_MY2023_Tx" SG_ 2611175494 PARSEDPhysSODCMDtoGWM_ECG 1;
BA_ "GenSigSendType" SG_ 2612224070 PARSEDPushSODCMDtoGWM 3;
BA_ "U_T6_MCA_MY2020_Rx" SG_ 2612224070 PARSEDPushSODCMDtoGWM 1;
BA_ "ECGUsedRxSignal" SG_ 2612224070 PARSEDPushSODCMDtoGWM 1;
BA_ "U_CD542_MY2021_Rx" SG_ 2612224070 PARSEDPushSODCMDtoGWM 1;
BA_ "U_U55X_MY2022_Rx" SG_ 2612224070 PARSEDPushSODCMDtoGWM 1;
BA_ "U_CDX706_MY2023_Rx" SG_ 2612224070 PARSEDPushSODCMDtoGWM 1;
BA_ "U_T6_MCA_MY2020_Tx" SG_ 2612224070 PARSEDPushSODCMDtoGWM 1;
BA_ "U_CD542_MY2021_Tx" SG_ 2612224070 PARSEDPushSODCMDtoGWM 1;
BA_ "U_U55X_MY2022_Tx" SG_ 2612224070 PARSEDPushSODCMDtoGWM 1;
BA_ "U_CD764_MY2022_Tx" SG_ 2612224070 PARSEDPushSODCMDtoGWM 1;
BA_ "U_CDX706_MY2023_Tx" SG_ 2612224070 PARSEDPushSODCMDtoGWM 1;
BA_ "GenSigSendType" SG_ 2611054808 PARSEDPhysGWM_ECGtoSODL 3;
BA_ "U_T6_MCA_MY2020_Rx" SG_ 2611054808 PARSEDPhysGWM_ECGtoSODL 1;
BA_ "U_CD542_MY2021_Rx" SG_ 2611054808 PARSEDPhysGWM_ECGtoSODL 1;
BA_ "U_U55X_MY2022_Rx" SG_ 2611054808 PARSEDPhysGWM_ECGtoSODL 1;
BA_ "U_CD764_MY2022_Rx" SG_ 2611054808 PARSEDPhysGWM_ECGtoSODL 1;
BA_ "U_CDX706_MY2023_Rx" SG_ 2611054808 PARSEDPhysGWM_ECGtoSODL 1;
BA_ "U_T6_MCA_MY2020_Tx" SG_ 2611054808 PARSEDPhysGWM_ECGtoSODL 1;
BA_ "ECGUsedTxSignal" SG_ 2611054808 PARSEDPhysGWM_ECGtoSODL 1;
BA_ "U_CD542_MY2021_Tx" SG_ 2611054808 PARSEDPhysGWM_ECGtoSODL 1;
BA_ "U_U55X_MY2022_Tx" SG_ 2611054808 PARSEDPhysGWM_ECGtoSODL 1;
BA_ "U_CDX706_MY2023_Tx" SG_ 2611054808 PARSEDPhysGWM_ECGtoSODL 1;
BA_ "GenSigSendType" SG_ 2611175523 PARSEDPhysSODRtoGWM_ECG 3;
BA_ "U_T6_MCA_MY2020_Rx" SG_ 2611175523 PARSEDPhysSODRtoGWM_ECG 1;
BA_ "ECGUsedRxSignal" SG_ 2611175523 PARSEDPhysSODRtoGWM_ECG 1;
BA_ "U_CD542_MY2021_Rx" SG_ 2611175523 PARSEDPhysSODRtoGWM_ECG 1;
BA_ "U_U55X_MY2022_Rx" SG_ 2611175523 PARSEDPhysSODRtoGWM_ECG 1;
BA_ "U_CDX706_MY2023_Rx" SG_ 2611175523 PARSEDPhysSODRtoGWM_ECG 1;
BA_ "U_T6_MCA_MY2020_Tx" SG_ 2611175523 PARSEDPhysSODRtoGWM_ECG 1;
BA_ "U_CD542_MY2021_Tx" SG_ 2611175523 PARSEDPhysSODRtoGWM_ECG 1;
BA_ "U_U55X_MY2022_Tx" SG_ 2611175523 PARSEDPhysSODRtoGWM_ECG 1;
BA_ "U_CD764_MY2022_Tx" SG_ 2611175523 PARSEDPhysSODRtoGWM_ECG 1;
BA_ "U_CDX706_MY2023_Tx" SG_ 2611175523 PARSEDPhysSODRtoGWM_ECG 1;
BA_ "GenSigSendType" SG_ 2612224099 PARSEDPushSODRtoGWM_ECG 3;
BA_ "U_T6_MCA_MY2020_Rx" SG_ 2612224099 PARSEDPushSODRtoGWM_ECG 1;
BA_ "ECGUsedRxSignal" SG_ 2612224099 PARSEDPushSODRtoGWM_ECG 1;
BA_ "U_CD542_MY2021_Rx" SG_ 2612224099 PARSEDPushSODRtoGWM_ECG 1;
BA_ "U_U55X_MY2022_Rx" SG_ 2612224099 PARSEDPushSODRtoGWM_ECG 1;
BA_ "U_CDX706_MY2023_Rx" SG_ 2612224099 PARSEDPushSODRtoGWM_ECG 1;
BA_ "U_T6_MCA_MY2020_Tx" SG_ 2612224099 PARSEDPushSODRtoGWM_ECG 1;
BA_ "U_CD542_MY2021_Tx" SG_ 2612224099 PARSEDPushSODRtoGWM_ECG 1;
BA_ "U_U55X_MY2022_Tx" SG_ 2612224099 PARSEDPushSODRtoGWM_ECG 1;
BA_ "U_CD764_MY2022_Tx" SG_ 2612224099 PARSEDPushSODRtoGWM_ECG 1;
BA_ "U_CDX706_MY2023_Tx" SG_ 2612224099 PARSEDPushSODRtoGWM_ECG 1;
BA_ "GenSigSendType" SG_ 2611055832 PARSEDPhysGWM_ECGtoSODR 3;
BA_ "U_T6_MCA_MY2020_Rx" SG_ 2611055832 PARSEDPhysGWM_ECGtoSODR 1;
BA_ "U_CD542_MY2021_Rx" SG_ 2611055832 PARSEDPhysGWM_ECGtoSODR 1;
BA_ "U_U55X_MY2022_Rx" SG_ 2611055832 PARSEDPhysGWM_ECGtoSODR 1;
BA_ "U_CD764_MY2022_Rx" SG_ 2611055832 PARSEDPhysGWM_ECGtoSODR 1;
BA_ "U_CDX706_MY2023_Rx" SG_ 2611055832 PARSEDPhysGWM_ECGtoSODR 1;
BA_ "U_T6_MCA_MY2020_Tx" SG_ 2611055832 PARSEDPhysGWM_ECGtoSODR 1;
BA_ "ECGUsedTxSignal" SG_ 2611055832 PARSEDPhysGWM_ECGtoSODR 1;
BA_ "U_CD542_MY2021_Tx" SG_ 2611055832 PARSEDPhysGWM_ECGtoSODR 1;
BA_ "U_U55X_MY2022_Tx" SG_ 2611055832 PARSEDPhysGWM_ECGtoSODR 1;
BA_ "U_CDX706_MY2023_Tx" SG_ 2611055832 PARSEDPhysGWM_ECGtoSODR 1;
BA_ "GenSigSendType" SG_ 2611175522 PARSEDPhysSODLtoGWM_ECG 3;
BA_ "U_T6_MCA_MY2020_Rx" SG_ 2611175522 PARSEDPhysSODLtoGWM_ECG 1;
BA_ "ECGUsedRxSignal" SG_ 2611175522 PARSEDPhysSODLtoGWM_ECG 1;
BA_ "U_CD542_MY2021_Rx" SG_ 2611175522 PARSEDPhysSODLtoGWM_ECG 1;
BA_ "U_U55X_MY2022_Rx" SG_ 2611175522 PARSEDPhysSODLtoGWM_ECG 1;
BA_ "U_CDX706_MY2023_Rx" SG_ 2611175522 PARSEDPhysSODLtoGWM_ECG 1;
BA_ "U_T6_MCA_MY2020_Tx" SG_ 2611175522 PARSEDPhysSODLtoGWM_ECG 1;
BA_ "U_CD542_MY2021_Tx" SG_ 2611175522 PARSEDPhysSODLtoGWM_ECG 1;
BA_ "U_U55X_MY2022_Tx" SG_ 2611175522 PARSEDPhysSODLtoGWM_ECG 1;
BA_ "U_CD764_MY2022_Tx" SG_ 2611175522 PARSEDPhysSODLtoGWM_ECG 1;
BA_ "U_CDX706_MY2023_Tx" SG_ 2611175522 PARSEDPhysSODLtoGWM_ECG 1;
BA_ "GenSigSendType" SG_ 2612224098 PARSEDPushSODLtoGWM_ECG 3;
BA_ "U_T6_MCA_MY2020_Rx" SG_ 2612224098 PARSEDPushSODLtoGWM_ECG 1;
BA_ "ECGUsedRxSignal" SG_ 2612224098 PARSEDPushSODLtoGWM_ECG 1;
BA_ "U_CD542_MY2021_Rx" SG_ 2612224098 PARSEDPushSODLtoGWM_ECG 1;
BA_ "U_U55X_MY2022_Rx" SG_ 2612224098 PARSEDPushSODLtoGWM_ECG 1;
BA_ "U_CDX706_MY2023_Rx" SG_ 2612224098 PARSEDPushSODLtoGWM_ECG 1;
BA_ "U_T6_MCA_MY2020_Tx" SG_ 2612224098 PARSEDPushSODLtoGWM_ECG 1;
BA_ "U_CD542_MY2021_Tx" SG_ 2612224098 PARSEDPushSODLtoGWM_ECG 1;
BA_ "U_U55X_MY2022_Tx" SG_ 2612224098 PARSEDPushSODLtoGWM_ECG 1;
BA_ "U_CD764_MY2022_Tx" SG_ 2612224098 PARSEDPushSODLtoGWM_ECG 1;
BA_ "U_CDX706_MY2023_Tx" SG_ 2612224098 PARSEDPushSODLtoGWM_ECG 1;
BA_ "GenSigSendType" SG_ 2609927384 OTAPhysGWM_ECGtoCCM 3;
BA_ "U_T6_MCA_MY2020_Rx" SG_ 2609927384 OTAPhysGWM_ECGtoCCM 1;
BA_ "U_CD542_MY2021_Rx" SG_ 2609927384 OTAPhysGWM_ECGtoCCM 1;
BA_ "U_U55X_MY2022_Rx" SG_ 2609927384 OTAPhysGWM_ECGtoCCM 1;
BA_ "U_CD764_MY2022_Rx" SG_ 2609927384 OTAPhysGWM_ECGtoCCM 1;
BA_ "U_CDX706_MY2023_Rx" SG_ 2609927384 OTAPhysGWM_ECGtoCCM 1;
BA_ "U_T6_MCA_MY2020_Tx" SG_ 2609927384 OTAPhysGWM_ECGtoCCM 1;
BA_ "ECGUsedTxSignal" SG_ 2609927384 OTAPhysGWM_ECGtoCCM 1;
BA_ "U_CD542_MY2021_Tx" SG_ 2609927384 OTAPhysGWM_ECGtoCCM 1;
BA_ "U_U55X_MY2022_Tx" SG_ 2609927384 OTAPhysGWM_ECGtoCCM 1;
BA_ "U_CDX706_MY2023_Tx" SG_ 2609927384 OTAPhysGWM_ECGtoCCM 1;
BA_ "GenSigSendType" SG_ 2610126869 OTAPhysCCMtoGWM_ECG 3;
BA_ "U_T6_MCA_MY2020_Rx" SG_ 2610126869 OTAPhysCCMtoGWM_ECG 1;
BA_ "ECGUsedRxSignal" SG_ 2610126869 OTAPhysCCMtoGWM_ECG 1;
BA_ "U_CD542_MY2021_Rx" SG_ 2610126869 OTAPhysCCMtoGWM_ECG 1;
BA_ "U_U55X_MY2022_Rx" SG_ 2610126869 OTAPhysCCMtoGWM_ECG 1;
BA_ "U_CDX706_MY2023_Rx" SG_ 2610126869 OTAPhysCCMtoGWM_ECG 1;
BA_ "U_T6_MCA_MY2020_Tx" SG_ 2610126869 OTAPhysCCMtoGWM_ECG 1;
BA_ "U_CD542_MY2021_Tx" SG_ 2610126869 OTAPhysCCMtoGWM_ECG 1;
BA_ "U_U55X_MY2022_Tx" SG_ 2610126869 OTAPhysCCMtoGWM_ECG 1;
BA_ "U_CD764_MY2022_Tx" SG_ 2610126869 OTAPhysCCMtoGWM_ECG 1;
BA_ "U_CDX706_MY2023_Tx" SG_ 2610126869 OTAPhysCCMtoGWM_ECG 1;
BA_ "GenSigSendType" SG_ 2609976536 OTAPhysGWM_ECGtoSODCMC 3;
BA_ "U_T6_MCA_MY2020_Rx" SG_ 2609976536 OTAPhysGWM_ECGtoSODCMC 1;
BA_ "U_CD542_MY2021_Rx" SG_ 2609976536 OTAPhysGWM_ECGtoSODCMC 1;
BA_ "U_U55X_MY2022_Rx" SG_ 2609976536 OTAPhysGWM_ECGtoSODCMC 1;
BA_ "U_CD764_MY2022_Rx" SG_ 2609976536 OTAPhysGWM_ECGtoSODCMC 1;
BA_ "U_CDX706_MY2023_Rx" SG_ 2609976536 OTAPhysGWM_ECGtoSODCMC 1;
BA_ "U_T6_MCA_MY2020_Tx" SG_ 2609976536 OTAPhysGWM_ECGtoSODCMC 1;
BA_ "ECGUsedTxSignal" SG_ 2609976536 OTAPhysGWM_ECGtoSODCMC 1;
BA_ "U_CD542_MY2021_Tx" SG_ 2609976536 OTAPhysGWM_ECGtoSODCMC 1;
BA_ "U_U55X_MY2022_Tx" SG_ 2609976536 OTAPhysGWM_ECGtoSODCMC 1;
BA_ "U_CDX706_MY2023_Tx" SG_ 2609976536 OTAPhysGWM_ECGtoSODCMC 1;
BA_ "GenSigSendType" SG_ 2610126917 OTAPhysSODCMCtoGWM_ECG 3;
BA_ "U_T6_MCA_MY2020_Rx" SG_ 2610126917 OTAPhysSODCMCtoGWM_ECG 1;
BA_ "ECGUsedRxSignal" SG_ 2610126917 OTAPhysSODCMCtoGWM_ECG 1;
BA_ "U_CD542_MY2021_Rx" SG_ 2610126917 OTAPhysSODCMCtoGWM_ECG 1;
BA_ "U_U55X_MY2022_Rx" SG_ 2610126917 OTAPhysSODCMCtoGWM_ECG 1;
BA_ "U_T6_MCA_MY2020_Tx" SG_ 2610126917 OTAPhysSODCMCtoGWM_ECG 1;
BA_ "U_CD542_MY2021_Tx" SG_ 2610126917 OTAPhysSODCMCtoGWM_ECG 1;
BA_ "U_U55X_MY2022_Tx" SG_ 2610126917 OTAPhysSODCMCtoGWM_ECG 1;
BA_ "U_CD764_MY2022_Tx" SG_ 2610126917 OTAPhysSODCMCtoGWM_ECG 1;
BA_ "U_CDX706_MY2023_Tx" SG_ 2610126917 OTAPhysSODCMCtoGWM_ECG 1;
BA_ "GenSigSendType" SG_ 2609977560 OTAPhysGWM_ECGtoSODCMD 3;
BA_ "U_T6_MCA_MY2020_Rx" SG_ 2609977560 OTAPhysGWM_ECGtoSODCMD 1;
BA_ "U_CD542_MY2021_Rx" SG_ 2609977560 OTAPhysGWM_ECGtoSODCMD 1;
BA_ "U_U55X_MY2022_Rx" SG_ 2609977560 OTAPhysGWM_ECGtoSODCMD 1;
BA_ "U_CD764_MY2022_Rx" SG_ 2609977560 OTAPhysGWM_ECGtoSODCMD 1;
BA_ "U_CDX706_MY2023_Rx" SG_ 2609977560 OTAPhysGWM_ECGtoSODCMD 1;
BA_ "U_T6_MCA_MY2020_Tx" SG_ 2609977560 OTAPhysGWM_ECGtoSODCMD 1;
BA_ "ECGUsedTxSignal" SG_ 2609977560 OTAPhysGWM_ECGtoSODCMD 1;
BA_ "U_CD542_MY2021_Tx" SG_ 2609977560 OTAPhysGWM_ECGtoSODCMD 1;
BA_ "U_U55X_MY2022_Tx" SG_ 2609977560 OTAPhysGWM_ECGtoSODCMD 1;
BA_ "U_CDX706_MY2023_Tx" SG_ 2609977560 OTAPhysGWM_ECGtoSODCMD 1;
BA_ "GenSigSendType" SG_ 2610126918 OTAPhysSODCMDtoGWM_ECG 3;
BA_ "U_T6_MCA_MY2020_Rx" SG_ 2610126918 OTAPhysSODCMDtoGWM_ECG 1;
BA_ "ECGUsedRxSignal" SG_ 2610126918 OTAPhysSODCMDtoGWM_ECG 1;
BA_ "U_CD542_MY2021_Rx" SG_ 2610126918 OTAPhysSODCMDtoGWM_ECG 1;
BA_ "U_U55X_MY2022_Rx" SG_ 2610126918 OTAPhysSODCMDtoGWM_ECG 1;
BA_ "U_T6_MCA_MY2020_Tx" SG_ 2610126918 OTAPhysSODCMDtoGWM_ECG 1;
BA_ "U_CD542_MY2021_Tx" SG_ 2610126918 OTAPhysSODCMDtoGWM_ECG 1;
BA_ "U_U55X_MY2022_Tx" SG_ 2610126918 OTAPhysSODCMDtoGWM_ECG 1;
BA_ "U_CD764_MY2022_Tx" SG_ 2610126918 OTAPhysSODCMDtoGWM_ECG 1;
BA_ "U_CDX706_MY2023_Tx" SG_ 2610126918 OTAPhysSODCMDtoGWM_ECG 1;
BA_ "GenSigSendType" SG_ 2610007256 OTAPhysGWM_ECGtoSODR 3;
BA_ "U_T6_MCA_MY2020_Rx" SG_ 2610007256 OTAPhysGWM_ECGtoSODR 1;
BA_ "U_CD542_MY2021_Rx" SG_ 2610007256 OTAPhysGWM_ECGtoSODR 1;
BA_ "U_U55X_MY2022_Rx" SG_ 2610007256 OTAPhysGWM_ECGtoSODR 1;
BA_ "U_CD764_MY2022_Rx" SG_ 2610007256 OTAPhysGWM_ECGtoSODR 1;
BA_ "U_CDX706_MY2023_Rx" SG_ 2610007256 OTAPhysGWM_ECGtoSODR 1;
BA_ "U_T6_MCA_MY2020_Tx" SG_ 2610007256 OTAPhysGWM_ECGtoSODR 1;
BA_ "ECGUsedTxSignal" SG_ 2610007256 OTAPhysGWM_ECGtoSODR 1;
BA_ "U_CD542_MY2021_Tx" SG_ 2610007256 OTAPhysGWM_ECGtoSODR 1;
BA_ "U_U55X_MY2022_Tx" SG_ 2610007256 OTAPhysGWM_ECGtoSODR 1;
BA_ "U_CDX706_MY2023_Tx" SG_ 2610007256 OTAPhysGWM_ECGtoSODR 1;
BA_ "GenSigSendType" SG_ 2610126947 OTAPhysSODRtoGWM_ECG 3;
BA_ "U_T6_MCA_MY2020_Rx" SG_ 2610126947 OTAPhysSODRtoGWM_ECG 1;
BA_ "ECGUsedRxSignal" SG_ 2610126947 OTAPhysSODRtoGWM_ECG 1;
BA_ "U_CD542_MY2021_Rx" SG_ 2610126947 OTAPhysSODRtoGWM_ECG 1;
BA_ "U_U55X_MY2022_Rx" SG_ 2610126947 OTAPhysSODRtoGWM_ECG 1;
BA_ "U_CDX706_MY2023_Rx" SG_ 2610126947 OTAPhysSODRtoGWM_ECG 1;
BA_ "U_T6_MCA_MY2020_Tx" SG_ 2610126947 OTAPhysSODRtoGWM_ECG 1;
BA_ "U_CD542_MY2021_Tx" SG_ 2610126947 OTAPhysSODRtoGWM_ECG 1;
BA_ "U_U55X_MY2022_Tx" SG_ 2610126947 OTAPhysSODRtoGWM_ECG 1;
BA_ "U_CD764_MY2022_Tx" SG_ 2610126947 OTAPhysSODRtoGWM_ECG 1;
BA_ "U_CDX706_MY2023_Tx" SG_ 2610126947 OTAPhysSODRtoGWM_ECG 1;
BA_ "GenSigSendType" SG_ 2612224017 PARSEDPushSOBDMCtoGWM_ECG 3;
BA_ "ECGUsedRxSignal" SG_ 2612224017 PARSEDPushSOBDMCtoGWM_ECG 1;
BA_ "U_CD542_MY2021_Rx" SG_ 2612224017 PARSEDPushSOBDMCtoGWM_ECG 1;
BA_ "U_U55X_MY2022_Rx" SG_ 2612224017 PARSEDPushSOBDMCtoGWM_ECG 1;
BA_ "U_CDX706_MY2023_Tx" SG_ 2612224017 PARSEDPushSOBDMCtoGWM_ECG 1;
BA_ "U_T6_MCA_MY2020_Tx" SG_ 981 AdbRamping_T_Rq 1;
BA_ "U_CD542_MY2021_Tx" SG_ 981 AdbRamping_T_Rq 1;
BA_ "U_U55X_MY2022_Tx" SG_ 981 AdbRamping_T_Rq 1;
BA_ "U_CD764_MY2022_Tx" SG_ 981 AdbRamping_T_Rq 1;
BA_ "U_CDX706_MY2023_Tx" SG_ 981 AdbRamping_T_Rq 1;
BA_ "GenSigStartValue" SG_ 981 AdbBrdrTop_An_Rq 254;
BA_ "U_T6_MCA_MY2020_Tx" SG_ 981 AdbBrdrTop_An_Rq 1;
BA_ "U_CD542_MY2021_Tx" SG_ 981 AdbBrdrTop_An_Rq 1;
BA_ "U_U55X_MY2022_Tx" SG_ 981 AdbBrdrTop_An_Rq 1;
BA_ "U_CD764_MY2022_Tx" SG_ 981 AdbBrdrTop_An_Rq 1;
BA_ "U_CDX706_MY2023_Tx" SG_ 981 AdbBrdrTop_An_Rq 1;
BA_ "GenSigStartValue" SG_ 981 AdbBrdrRight_L_Stat 510;
BA_ "U_T6_MCA_MY2020_Tx" SG_ 981 AdbBrdrRight_L_Stat 1;
BA_ "U_CD542_MY2021_Tx" SG_ 981 AdbBrdrRight_L_Stat 1;
BA_ "U_U55X_MY2022_Tx" SG_ 981 AdbBrdrRight_L_Stat 1;
BA_ "U_CD764_MY2022_Tx" SG_ 981 AdbBrdrRight_L_Stat 1;
BA_ "U_CDX706_MY2023_Tx" SG_ 981 AdbBrdrRight_L_Stat 1;
BA_ "GenSigStartValue" SG_ 981 AdbBrdrRight_An_Rq 1022;
BA_ "U_T6_MCA_MY2020_Tx" SG_ 981 AdbBrdrRight_An_Rq 1;
BA_ "U_CD542_MY2021_Tx" SG_ 981 AdbBrdrRight_An_Rq 1;
BA_ "U_U55X_MY2022_Tx" SG_ 981 AdbBrdrRight_An_Rq 1;
BA_ "U_CD764_MY2022_Tx" SG_ 981 AdbBrdrRight_An_Rq 1;
BA_ "U_CDX706_MY2023_Tx" SG_ 981 AdbBrdrRight_An_Rq 1;
BA_ "GenSigStartValue" SG_ 981 AdbBrdrLeft_L_Stat 510;
BA_ "U_T6_MCA_MY2020_Tx" SG_ 981 AdbBrdrLeft_L_Stat 1;
BA_ "U_CD542_MY2021_Tx" SG_ 981 AdbBrdrLeft_L_Stat 1;
BA_ "U_U55X_MY2022_Tx" SG_ 981 AdbBrdrLeft_L_Stat 1;
BA_ "U_CD764_MY2022_Tx" SG_ 981 AdbBrdrLeft_L_Stat 1;
BA_ "U_CDX706_MY2023_Tx" SG_ 981 AdbBrdrLeft_L_Stat 1;
BA_ "GenSigStartValue" SG_ 981 AdbBrdrLeft_An_Rq 1022;
BA_ "U_T6_MCA_MY2020_Tx" SG_ 981 AdbBrdrLeft_An_Rq 1;
BA_ "U_CD542_MY2021_Tx" SG_ 981 AdbBrdrLeft_An_Rq 1;
BA_ "U_U55X_MY2022_Tx" SG_ 981 AdbBrdrLeft_An_Rq 1;
BA_ "U_CD764_MY2022_Tx" SG_ 981 AdbBrdrLeft_An_Rq 1;
BA_ "U_CDX706_MY2023_Tx" SG_ 981 AdbBrdrLeft_An_Rq 1;
BA_ "GenSigStartValue" SG_ 981 AdbBrdrBottom_An_Rq 62;
BA_ "U_T6_MCA_MY2020_Tx" SG_ 981 AdbBrdrBottom_An_Rq 1;
BA_ "U_CD542_MY2021_Tx" SG_ 981 AdbBrdrBottom_An_Rq 1;
BA_ "U_U55X_MY2022_Tx" SG_ 981 AdbBrdrBottom_An_Rq 1;
BA_ "U_CD764_MY2022_Tx" SG_ 981 AdbBrdrBottom_An_Rq 1;
BA_ "U_CDX706_MY2023_Tx" SG_ 981 AdbBrdrBottom_An_Rq 1;
BA_ "U_T6_MCA_MY2020_Tx" SG_ 981 AdbBeam_D_Rq 1;
BA_ "U_CD542_MY2021_Tx" SG_ 981 AdbBeam_D_Rq 1;
BA_ "U_U55X_MY2022_Tx" SG_ 981 AdbBeam_D_Rq 1;
BA_ "U_CD764_MY2022_Tx" SG_ 981 AdbBeam_D_Rq 1;
BA_ "U_CDX706_MY2023_Tx" SG_ 981 AdbBeam_D_Rq 1;
BA_ "GenSigSendType" SG_ 810 VehHorn_B_RqOccAlrt 3;
BA_ "WakeupSignal" SG_ 810 VehHorn_B_RqOccAlrt 1;
BA_ "ECGUsedTxSignal" SG_ 810 VehHorn_B_RqOccAlrt 1;
BA_ "U_CDX706_MY2023_Tx" SG_ 810 VehHorn_B_RqOccAlrt 1;
BA_ "GenSigSendType" SG_ 810 RmtViewMde_B_Rq 3;
BA_ "ECGUsedTxSignal" SG_ 810 RmtViewMde_B_Rq 1;
BA_ "U_CD542_MY2021_Tx" SG_ 810 RmtViewMde_B_Rq 1;
BA_ "U_CDX706_MY2023_Tx" SG_ 810 RmtViewMde_B_Rq 1;
BA_ "GenSigSendType" SG_ 810 DteCldAcceptData_B_Rq 3;
BA_ "ECGUsedTxSignal" SG_ 810 DteCldAcceptData_B_Rq 1;
BA_ "U_CD542_MY2021_Tx" SG_ 810 DteCldAcceptData_B_Rq 1;
BA_ "U_CD764_MY2022_Tx" SG_ 810 DteCldAcceptData_B_Rq 1;
BA_ "U_CDX706_MY2023_Tx" SG_ 810 DteCldAcceptData_B_Rq 1;
BA_ "GenSigSendType" SG_ 810 DteCldCnclRoute_B_Rq 3;
BA_ "ECGUsedTxSignal" SG_ 810 DteCldCnclRoute_B_Rq 1;
BA_ "U_CD542_MY2021_Tx" SG_ 810 DteCldCnclRoute_B_Rq 1;
BA_ "U_U55X_MY2022_Tx" SG_ 810 DteCldCnclRoute_B_Rq 1;
BA_ "U_CD764_MY2022_Tx" SG_ 810 DteCldCnclRoute_B_Rq 1;
BA_ "U_CDX706_MY2023_Tx" SG_ 810 DteCldCnclRoute_B_Rq 1;
BA_ "GenSigSendType" SG_ 810 NtfyDrvTrgtDist_L_Rq 3;
BA_ "WakeupSignal" SG_ 810 NtfyDrvTrgtDist_L_Rq 1;
BA_ "GenSigStartValueInteger" SG_ 810 NtfyDrvTrgtDist_L_Rq 1;
BA_ "GenSigStartValue" SG_ 810 NtfyDrvTrgtDist_L_Rq 4095;
BA_ "ECGUsedTxSignal" SG_ 810 NtfyDrvTrgtDist_L_Rq 1;
BA_ "U_CD542_MY2021_Tx" SG_ 810 NtfyDrvTrgtDist_L_Rq 1;
BA_ "U_U55X_MY2022_Tx" SG_ 810 NtfyDrvTrgtDist_L_Rq 1;
BA_ "GenSigSendType" SG_ 810 NtfyDrvSocLvl1_Pc_Rq 3;
BA_ "WakeupSignal" SG_ 810 NtfyDrvSocLvl1_Pc_Rq 1;
BA_ "GenSigStartValueInteger" SG_ 810 NtfyDrvSocLvl1_Pc_Rq 1;
BA_ "GenSigStartValue" SG_ 810 NtfyDrvSocLvl1_Pc_Rq 127;
BA_ "ECGUsedTxSignal" SG_ 810 NtfyDrvSocLvl1_Pc_Rq 1;
BA_ "U_CD542_MY2021_Tx" SG_ 810 NtfyDrvSocLvl1_Pc_Rq 1;
BA_ "U_U55X_MY2022_Tx" SG_ 810 NtfyDrvSocLvl1_Pc_Rq 1;
BA_ "GenSigSendType" SG_ 810 PtRmtRprt_D_Stat 3;
BA_ "WakeupSignal" SG_ 810 PtRmtRprt_D_Stat 1;
BA_ "ECGUsedTxSignal" SG_ 810 PtRmtRprt_D_Stat 1;
BA_ "U_CD542_MY2021_Tx" SG_ 810 PtRmtRprt_D_Stat 1;
BA_ "U_U55X_MY2022_Tx" SG_ 810 PtRmtRprt_D_Stat 1;
BA_ "U_CDX706_MY2023_Tx" SG_ 810 PtRmtRprt_D_Stat 1;
BA_ "GenSigSendType" SG_ 810 ChrgrPncEnbl_D_Rq 3;
BA_ "GenSigStartValueInteger" SG_ 810 ChrgrPncEnbl_D_Rq 3;
BA_ "GenSigStartValue" SG_ 810 ChrgrPncEnbl_D_Rq 3;
BA_ "ECGUsedTxSignal" SG_ 810 ChrgrPncEnbl_D_Rq 1;
BA_ "U_CD542_MY2021_Tx" SG_ 810 ChrgrPncEnbl_D_Rq 1;
BA_ "U_U55X_MY2022_Tx" SG_ 810 ChrgrPncEnbl_D_Rq 1;
BA_ "U_CD764_MY2022_Tx" SG_ 810 ChrgrPncEnbl_D_Rq 1;
BA_ "U_CDX706_MY2023_Tx" SG_ 810 ChrgrPncEnbl_D_Rq 1;
BA_ "GenSigSendType" SG_ 810 OneTEditActv_B_RqCld 3;
BA_ "ECGUsedTxSignal" SG_ 810 OneTEditActv_B_RqCld 1;
BA_ "U_CD542_MY2021_Tx" SG_ 810 OneTEditActv_B_RqCld 1;
BA_ "U_U55X_MY2022_Tx" SG_ 810 OneTEditActv_B_RqCld 1;
BA_ "U_CDX706_MY2023_Tx" SG_ 810 OneTEditActv_B_RqCld 1;
BA_ "GenSigSendType" SG_ 810 GoTElementEdit_No_RqCld 3;
BA_ "ECGUsedTxSignal" SG_ 810 GoTElementEdit_No_RqCld 1;
BA_ "U_CD542_MY2021_Tx" SG_ 810 GoTElementEdit_No_RqCld 1;
BA_ "U_U55X_MY2022_Tx" SG_ 810 GoTElementEdit_No_RqCld 1;
BA_ "U_CD764_MY2022_Tx" SG_ 810 GoTElementEdit_No_RqCld 1;
BA_ "U_CDX706_MY2023_Tx" SG_ 810 GoTElementEdit_No_RqCld 1;
BA_ "GenSigSendType" SG_ 810 OBCCSerial_D_Rq 3;
BA_ "ECGUsedTxSignal" SG_ 810 OBCCSerial_D_Rq 1;
BA_ "U_CD542_MY2021_Tx" SG_ 810 OBCCSerial_D_Rq 1;
BA_ "U_U55X_MY2022_Tx" SG_ 810 OBCCSerial_D_Rq 1;
BA_ "U_CDX706_MY2023_Tx" SG_ 810 OBCCSerial_D_Rq 1;
BA_ "GenSigSendType" SG_ 810 ExtLghtDsply_B_StatArb 3;
BA_ "WakeupSignal" SG_ 810 ExtLghtDsply_B_StatArb 1;
BA_ "U_T6_MCA_MY2020_Tx" SG_ 810 ExtLghtDsply_B_StatArb 1;
BA_ "ECGUsedTxSignal" SG_ 810 ExtLghtDsply_B_StatArb 1;
BA_ "U_CD542_MY2021_Tx" SG_ 810 ExtLghtDsply_B_StatArb 1;
BA_ "U_U55X_MY2022_Tx" SG_ 810 ExtLghtDsply_B_StatArb 1;
BA_ "U_CD764_MY2022_Tx" SG_ 810 ExtLghtDsply_B_StatArb 1;
BA_ "U_CDX706_MY2023_Tx" SG_ 810 ExtLghtDsply_B_StatArb 1;
BA_ "GenSigSendType" SG_ 810 ExtLghtRight_D_RqOta 3;
BA_ "WakeupSignal" SG_ 810 ExtLghtRight_D_RqOta 1;
BA_ "U_T6_MCA_MY2020_Tx" SG_ 810 ExtLghtRight_D_RqOta 1;
BA_ "ECGUsedTxSignal" SG_ 810 ExtLghtRight_D_RqOta 1;
BA_ "U_CD542_MY2021_Tx" SG_ 810 ExtLghtRight_D_RqOta 1;
BA_ "U_U55X_MY2022_Tx" SG_ 810 ExtLghtRight_D_RqOta 1;
BA_ "U_CD764_MY2022_Tx" SG_ 810 ExtLghtRight_D_RqOta 1;
BA_ "U_CDX706_MY2023_Tx" SG_ 810 ExtLghtRight_D_RqOta 1;
BA_ "GenSigSendType" SG_ 810 ExtLghtRear_D_RqOta 3;
BA_ "WakeupSignal" SG_ 810 ExtLghtRear_D_RqOta 1;
BA_ "U_T6_MCA_MY2020_Tx" SG_ 810 ExtLghtRear_D_RqOta 1;
BA_ "ECGUsedTxSignal" SG_ 810 ExtLghtRear_D_RqOta 1;
BA_ "U_CD542_MY2021_Tx" SG_ 810 ExtLghtRear_D_RqOta 1;
BA_ "U_U55X_MY2022_Tx" SG_ 810 ExtLghtRear_D_RqOta 1;
BA_ "U_CD764_MY2022_Tx" SG_ 810 ExtLghtRear_D_RqOta 1;
BA_ "U_CDX706_MY2023_Tx" SG_ 810 ExtLghtRear_D_RqOta 1;
BA_ "GenSigSendType" SG_ 810 ExtLghtLeft_D_RqOta 3;
BA_ "WakeupSignal" SG_ 810 ExtLghtLeft_D_RqOta 1;
BA_ "U_T6_MCA_MY2020_Tx" SG_ 810 ExtLghtLeft_D_RqOta 1;
BA_ "ECGUsedTxSignal" SG_ 810 ExtLghtLeft_D_RqOta 1;
BA_ "U_CD542_MY2021_Tx" SG_ 810 ExtLghtLeft_D_RqOta 1;
BA_ "U_U55X_MY2022_Tx" SG_ 810 ExtLghtLeft_D_RqOta 1;
BA_ "U_CD764_MY2022_Tx" SG_ 810 ExtLghtLeft_D_RqOta 1;
BA_ "U_CDX706_MY2023_Tx" SG_ 810 ExtLghtLeft_D_RqOta 1;
BA_ "GenSigSendType" SG_ 810 ExtLghtFront_D_RqOta 3;
BA_ "WakeupSignal" SG_ 810 ExtLghtFront_D_RqOta 1;
BA_ "U_T6_MCA_MY2020_Tx" SG_ 810 ExtLghtFront_D_RqOta 1;
BA_ "ECGUsedTxSignal" SG_ 810 ExtLghtFront_D_RqOta 1;
BA_ "U_CD542_MY2021_Tx" SG_ 810 ExtLghtFront_D_RqOta 1;
BA_ "U_U55X_MY2022_Tx" SG_ 810 ExtLghtFront_D_RqOta 1;
BA_ "U_CD764_MY2022_Tx" SG_ 810 ExtLghtFront_D_RqOta 1;
BA_ "U_CDX706_MY2023_Tx" SG_ 810 ExtLghtFront_D_RqOta 1;
BA_ "GenSigSendType" SG_ 810 TlghtTest_D_RqArb 3;
BA_ "U_T6_MCA_MY2020_Tx" SG_ 810 TlghtTest_D_RqArb 1;
BA_ "ECGUsedTxSignal" SG_ 810 TlghtTest_D_RqArb 1;
BA_ "U_CD542_MY2021_Tx" SG_ 810 TlghtTest_D_RqArb 1;
BA_ "U_U55X_MY2022_Tx" SG_ 810 TlghtTest_D_RqArb 1;
BA_ "U_CDX706_MY2023_Tx" SG_ 810 TlghtTest_D_RqArb 1;
BA_ "GenSigSendType" SG_ 810 ChrgrPncSustn_B_Rq 3;
BA_ "GenSigStartValueInteger" SG_ 810 ChrgrPncSustn_B_Rq 3;
BA_ "ECGUsedTxSignal" SG_ 810 ChrgrPncSustn_B_Rq 1;
BA_ "U_CD542_MY2021_Tx" SG_ 810 ChrgrPncSustn_B_Rq 1;
BA_ "U_U55X_MY2022_Tx" SG_ 810 ChrgrPncSustn_B_Rq 1;
BA_ "U_CD764_MY2022_Tx" SG_ 810 ChrgrPncSustn_B_Rq 1;
BA_ "U_CDX706_MY2023_Tx" SG_ 810 ChrgrPncSustn_B_Rq 1;
BA_ "GenSigSendType" SG_ 810 GoTAirAmb_Te_ActlCld 3;
BA_ "GenSigStartValue" SG_ 810 GoTAirAmb_Te_ActlCld 512;
BA_ "ECGUsedTxSignal" SG_ 810 GoTAirAmb_Te_ActlCld 1;
BA_ "U_CD542_MY2021_Tx" SG_ 810 GoTAirAmb_Te_ActlCld 1;
BA_ "U_U55X_MY2022_Tx" SG_ 810 GoTAirAmb_Te_ActlCld 1;
BA_ "U_CD764_MY2022_Tx" SG_ 810 GoTAirAmb_Te_ActlCld 1;
BA_ "U_CDX706_MY2023_Tx" SG_ 810 GoTAirAmb_Te_ActlCld 1;
BA_ "GenSigSendType" SG_ 563 BattChrgStrtStop_D2_Rq 3;
BA_ "ECGUsedTxSignal" SG_ 563 BattChrgStrtStop_D2_Rq 1;
BA_ "U_CDX706_MY2023_Tx" SG_ 563 BattChrgStrtStop_D2_Rq 1;
BA_ "GenSigSendType" SG_ 563 DrvBhavAudioAlrt_D_Rq 3;
BA_ "ECGUsedTxSignal" SG_ 563 DrvBhavAudioAlrt_D_Rq 1;
BA_ "U_CDX706_MY2023_Tx" SG_ 563 DrvBhavAudioAlrt_D_Rq 1;
BA_ "GenSigSendType" SG_ 563 NtfyDrvTrgtDist_L2_Rq 3;
BA_ "WakeupSignal" SG_ 563 NtfyDrvTrgtDist_L2_Rq 1;
BA_ "GenSigStartValueInteger" SG_ 563 NtfyDrvTrgtDist_L2_Rq 1;
BA_ "GenSigStartValue" SG_ 563 NtfyDrvTrgtDist_L2_Rq 8190;
BA_ "ECGUsedTxSignal" SG_ 563 NtfyDrvTrgtDist_L2_Rq 1;
BA_ "U_CD542_MY2021_Tx" SG_ 563 NtfyDrvTrgtDist_L2_Rq 1;
BA_ "U_CDX706_MY2023_Tx" SG_ 563 NtfyDrvTrgtDist_L2_Rq 1;
BA_ "GenSigSendType" SG_ 563 BattChrgStrtStop_D_Rq 3;
BA_ "U_T6_MCA_MY2020_Tx" SG_ 563 BattChrgStrtStop_D_Rq 1;
BA_ "ECGUsedTxSignal" SG_ 563 BattChrgStrtStop_D_Rq 1;
BA_ "U_CD542_MY2021_Tx" SG_ 563 BattChrgStrtStop_D_Rq 1;
BA_ "U_U55X_MY2022_Tx" SG_ 563 BattChrgStrtStop_D_Rq 1;
BA_ "U_CDX706_MY2023_Tx" SG_ 563 BattChrgStrtStop_D_Rq 1;
BA_ "GenSigSendType" SG_ 563 DrvBhavWarn_B_Rq 3;
BA_ "U_T6_MCA_MY2020_Tx" SG_ 563 DrvBhavWarn_B_Rq 1;
BA_ "ECGUsedTxSignal" SG_ 563 DrvBhavWarn_B_Rq 1;
BA_ "U_CD542_MY2021_Tx" SG_ 563 DrvBhavWarn_B_Rq 1;
BA_ "U_U55X_MY2022_Tx" SG_ 563 DrvBhavWarn_B_Rq 1;
BA_ "U_CDX706_MY2023_Tx" SG_ 563 DrvBhavWarn_B_Rq 1;
BA_ "GenSigSendType" SG_ 563 OfbChrgSetSync_D_Rq 3;
BA_ "ECGUsedTxSignal" SG_ 563 OfbChrgSetSync_D_Rq 1;
BA_ "U_CD542_MY2021_Tx" SG_ 563 OfbChrgSetSync_D_Rq 1;
BA_ "U_U55X_MY2022_Tx" SG_ 563 OfbChrgSetSync_D_Rq 1;
BA_ "U_CDX706_MY2023_Tx" SG_ 563 OfbChrgSetSync_D_Rq 1;
BA_ "GenSigSendType" SG_ 563 KeyOffPwMde_D_Stat 3;
BA_ "U_T6_MCA_MY2020_Tx" SG_ 563 KeyOffPwMde_D_Stat 1;
BA_ "ECGUsedTxSignal" SG_ 563 KeyOffPwMde_D_Stat 1;
BA_ "U_CD542_MY2021_Tx" SG_ 563 KeyOffPwMde_D_Stat 1;
BA_ "U_U55X_MY2022_Tx" SG_ 563 KeyOffPwMde_D_Stat 1;
BA_ "U_CDX706_MY2023_Tx" SG_ 563 KeyOffPwMde_D_Stat 1;
BA_ "GenSigSendType" SG_ 563 ModemReset_D_Stat 3;
BA_ "U_T6_MCA_MY2020_Tx" SG_ 563 ModemReset_D_Stat 1;
BA_ "ECGUsedTxSignal" SG_ 563 ModemReset_D_Stat 1;
BA_ "U_CD542_MY2021_Tx" SG_ 563 ModemReset_D_Stat 1;
BA_ "U_U55X_MY2022_Tx" SG_ 563 ModemReset_D_Stat 1;
BA_ "U_CDX706_MY2023_Tx" SG_ 563 ModemReset_D_Stat 1;
BA_ "GenSigSendType" SG_ 563 FactoryReset_St 3;
BA_ "U_T6_MCA_MY2020_Tx" SG_ 563 FactoryReset_St 1;
BA_ "ECGUsedTxSignal" SG_ 563 FactoryReset_St 1;
BA_ "U_CD542_MY2021_Tx" SG_ 563 FactoryReset_St 1;
BA_ "U_U55X_MY2022_Tx" SG_ 563 FactoryReset_St 1;
BA_ "U_CDX706_MY2023_Tx" SG_ 563 FactoryReset_St 1;
BA_ "GenSigSendType" SG_ 2609923288 OTAPhysGWM_ECGtoSOBDMC 3;
BA_ "U_CX727_MY2021_Rx" SG_ 2609923288 OTAPhysGWM_ECGtoSOBDMC 1;
BA_ "U_P702_MY2021_Rx" SG_ 2609923288 OTAPhysGWM_ECGtoSOBDMC 1;
BA_ "U_CD542_MY2021_Rx" SG_ 2609923288 OTAPhysGWM_ECGtoSOBDMC 1;
BA_ "U_CDX706_MY2023_Rx" SG_ 2609923288 OTAPhysGWM_ECGtoSOBDMC 1;
BA_ "ECGUsedTxSignal" SG_ 2609923288 OTAPhysGWM_ECGtoSOBDMC 1;
BA_ "U_CD542_MY2021_Tx" SG_ 2609923288 OTAPhysGWM_ECGtoSOBDMC 1;
BA_ "U_U55X_MY2022_Tx" SG_ 2609923288 OTAPhysGWM_ECGtoSOBDMC 1;
VAL_ 785 VehPerfDemo_D_Stat 3 "NotUsed" 2 "NotReady" 1 "Active" 0 "Inactive" ;
VAL_ 785 VehVLimMsgTxt_B_Rq 1 "Yes" 0 "No" ;
VAL_ 785 BattElecPerf_D2_Actl 7 "NotUsed" 6 "SeverelyLimitedPerformance" 5 "LimitedPerformance" 4 "SeverelyLimPerf_MotorTe" 3 "LimitedPerf_MotorTe" 2 "SeverelyLimPerf_BatteryTe" 1 "LimitedPerf_BatteryTe" 0 "NoMessage" ;
VAL_ 785 RgenAnimation_B_Dsply 1 "Active" 0 "Inactive" ;
VAL_ 785 BattTracLimPerf_D_Dsply 3 "NotUsed" 2 "SeverelyLimitedPerformance" 1 "LimitedPerformance" 0 "NoDisplay" ;
VAL_ 785 EcoIdl_D_Stat 3 "NotUsed" 2 "Enabled" 1 "Disabled" 0 "Null" ;
VAL_ 785 DteVehOffst_L_Dsply 8191 "Faulty" 8190 "NoDataExists" ;
VAL_ 785 DteVehOffstMsgTxt_D_Rq 15 "NotUsed_7" 14 "NotUsed_6" 13 "NotUsed_5" 12 "NotUsed_4" 11 "NotUsed_3" 10 "NotUsed_2" 9 "NotUsed_1" 8 "PowerToTheBox" 7 "Payload" 6 "TrailerTowing_Off" 5 "TrailerTowing_On" 4 "TrafficAlongRoute" 3 "ExternalTemperature" 2 "HillyTerrain" 1 "DestinationRoute" 0 "NoMessage" ;
VAL_ 785 PwPckTqRdyChime_B_Rq 3 "NotUsed" 2 "Shutdown" 1 "Startup" 0 "Null" ;
VAL_ 785 BattTracLoThres_D_Stat 7 "NotUsed" 6 "Thres80km_50mi" 5 "Thres50km_31mi" 4 "Thres30km_18mi" 3 "Thres50mi_80km" 2 "Thres30mi_48km" 1 "Thres20mi_32km" 0 "Null" ;
VAL_ 785 BattTracLoMsgTxt_D_Rq 7 "NotUsed_2" 6 "NotUsed_1" 5 "ZeroDteBatteryDepleted" 4 "ClimateLowDteSecondAlert" 3 "ClimateLowDteFirstAlert" 2 "LowDteSecondAlert" 1 "LowDteFirstAlert" 0 "Null" ;
VAL_ 785 BattTracLoSoc_D_Dsply 3 "NotUsed" 2 "ZeroDteDepletedBattery" 1 "LoDte" 0 "Null" ;
VAL_ 770 BattTracVrtOck_B_Stat 1 "Yes" 0 "No" ;
VAL_ 770 ChrgTrgtSocOvrrd_B_Stat 1 "On" 0 "Off" ;
VAL_ 770 ScPayloadUpdate_B_Stat 3 "NotUsed" 2 "Complete" 1 "InProcess" 0 "Null" ;
VAL_ 770 ScChrgrPwMax_Pw_Actl 4095 "Faulty" ;
VAL_ 770 ScEnbl_B_Stat 1 "On" 0 "Off" ;
VAL_ 1205 CstmDrvMdeCfg2_B_Avail 1 "Available" 0 "NotAvailable" ;
VAL_ 1205 CstmDrvMdeCfg1_B_Avail 1 "Available" 0 "NotAvailable" ;
VAL_ 942 ApaOffOptnSel_B_Avail 1 "Available" 0 "NotAvailable" ;
VAL_ 942 PrkBrkElRleas_B_RqApa 1 "Yes" 0 "No" ;
VAL_ 942 ApaDrvRq2MsgTxt_D_Rq 15 "NotUsed_7" 14 "NotUsed_6" 13 "NotUsed_5" 12 "NotUsed_4" 11 "NotUsed_3" 10 "NotUsed_2" 9 "NotUsed_1" 8 "CloseDoor" 7 "TakeControl" 6 "ReleaseEpb" 5 "ReleaseSteering" 4 "ReleaseBrake" 3 "DriveBackward" 2 "DriveForward" 1 "Stop" 0 "NoRequest" ;
VAL_ 942 ApaDrvRq1MsgTxt_D_Rq 7 "NotUsed" 6 "ExitVehicle" 5 "PressApaButton" 4 "ShiftToP" 3 "ShiftToN" 2 "ShiftToD" 1 "ShiftToR" 0 "NoRequest" ;
VAL_ 942 ApaSys_D2_Stat 15 "NotUsed_5" 14 "NotUsed_4" 13 "NotUsed_3" 12 "NotUsed_2" 11 "NotUsed_1" 10 "NoSideSelectable" 9 "RightSideSelectable" 8 "LeftSideSelectable" 7 "BothSidesSelectable" 6 "Faulty" 5 "Finished" 4 "Cancelled" 3 "NotAvailable" 2 "Overspeed" 1 "Pause" 0 "NormalOperation" ;
VAL_ 942 ApaSlotTrgt_D_Stat 15 "NotUsed_7" 14 "NotUsed_6" 13 "NotUsed_5" 12 "NotUsed_4" 11 "NotUsed_3" 10 "NotUsed_2" 9 "NotUsed_1" 8 "Front" 7 "Rear" 6 "Right3" 5 "Right2" 4 "Right1" 3 "Left3" 2 "Left2" 1 "Left1" 0 "None" ;
VAL_ 942 ApaSlotOption_B_Avail 1 "Available" 0 "NotAvailable" ;
VAL_ 942 ApaSlotAlrtSet_B_Stat 1 "Enable" 0 "Disable" ;
VAL_ 942 ApaSlotAlrt_B_Rq 1 "True" 0 "False" ;
VAL_ 942 ApaRmtFeatSel_B_Avail 1 "Available" 0 "NotAvailable" ;
VAL_ 942 ApaParkOutSel_B_Avail 1 "Available" 0 "NotAvailable" ;
VAL_ 942 ApaParkInSel_B_Avail 1 "Available" 0 "NotAvailable" ;
VAL_ 942 ApaMsgTxt_D2_Stat 15 "ReducedFunction" 14 "TrailerFeatureNotAvailable" 13 "AcceleratorPedalInactive" 12 "SensorsBlocked" 11 "TrailerAttached" 10 "TcsDeactivated" 9 "WheelSlip" 8 "HighInclination" 7 "DoorOpen" 6 "SteeringInteraction" 5 "WrongDirection" 4 "SpeedLimitExceeded" 3 "BrakeEvent" 2 "ObstacleInPath" 1 "WaitForSteering" 0 "None" ;
VAL_ 942 ApaDynmcSlot_B_Stat 1 "On" 0 "Off" ;
VAL_ 942 ApaDisplayMode_D_Stat 3 "NotUsed" 2 "FullScreen" 1 "Menu" 0 "Off" ;
VAL_ 942 ApaControlMode_D_Stat 1 "Active" 0 "Inactive" ;
VAL_ 942 PrkAidAcsyRear_D_Stat 3 "NotUsed" 2 "On" 1 "Off" 0 "Null" ;
VAL_ 942 PrkAidAcsyFront_D_Stat 3 "NotUsed" 2 "On" 1 "Off" 0 "Null" ;
VAL_ 942 PrkAidDrvDir_D_Stat 7 "NotUsed_2" 6 "NotUsed_1" 5 "BackwardNegative" 4 "ForwardNegative" 3 "BackwardPositive" 2 "ForwardPositive" 1 "NoMotion" 0 "DirectionNotKnown" ;
VAL_ 123 BattTrac_U2_Actl 4095 "Faulty" 4094 "NoDataExists" ;
VAL_ 123 BattTrac_I2_Actl 262143 "Faulty" 262142 "NoDataExists" ;
VAL_ 1201 FrontDiffLck_D_RqDrv2 3 "Faulty" 2 "NoRequest" 1 "On" 0 "Off" ;
VAL_ 1201 RearDiffLck_D_RqDrv2 3 "Faulty" 2 "NoRequest" 1 "On" 0 "Off" ;
VAL_ 1201 DrvSlipCtlMde_B_Rq5 1 "Pressed" 0 "Not_Pressed" ;
VAL_ 1201 StabBarCnncButtn_D_Sta2 3 "Faulty" 2 "NotUsed" 1 "Pressed" 0 "Not_Pressed" ;
VAL_ 1201 OrtaSwtch_D_Stat 3 "Faulty" 2 "NotUsed" 1 "Pressed" 0 "Not_Pressed" ;
VAL_ 1239 SelDrvMdeGzg_D_Rq 31 "Faulty" 30 "SelDrvMde31" 29 "SelDrvMde30" 28 "SelDrvMde29" 27 "SelDrvMde28" 26 "SelDrvMde27" 25 "SelDrvMde26" 24 "SelDrvMde25" 23 "SelDrvMde24" 22 "SelDrvMde23" 21 "SelDrvMde22" 20 "SelDrvMde21" 19 "SelDrvMde20" 18 "SelDrvMde19" 17 "SelDrvMde18" 16 "SelDrvMde17" 15 "SelDrvMde16" 14 "SelDrvMde15" 13 "SelDrvMde14" 12 "SelDrvMde13" 11 "SelDrvMde12" 10 "SelDrvMde11" 9 "SelDrvMde10" 8 "SelDrvMde09" 7 "SelDrvMde08" 6 "SelDrvMde07" 5 "SelDrvMde06" 4 "SelDrvMde05" 3 "SelDrvMde04" 2 "SelDrvMde03" 1 "SelDrvMde02" 0 "SelDrvMde01" ;
VAL_ 1239 CstmDrvMdeTracCtl_D_Rq 3 "App_Specific_Off_Mode_3" 2 "App_Specific_Off_Mode_2" 1 "App_Specific_Off_Mode_1" 0 "Default_Mode" ;
VAL_ 1239 CstmDrvMdeChassis_D_Rq 31 "Faulty" 30 "NotUsed17" 29 "NotUsed16" 28 "NotUsed15" 27 "NotUsed14" 26 "NotUsed13" 25 "NotUsed12" 24 "NotUsed11" 23 "NotUsed10" 22 "NotUsed9" 21 "NotUsed8" 20 "NotUsed7" 19 "NotUsed6" 18 "NotUsed5" 17 "NotUsed4" 16 "OnePedalDrive" 15 "DragMode" 14 "RoughRoadMode" 13 "TrackMode" 12 "HighSpeedDesertMode" 11 "TowHaulMode" 10 "RockCrawlMode" 9 "SandMode" 8 "MudAndRutsMode" 7 "LowMuMode" 6 "ComfortAdaptiveMode" 5 "ComfortMode" 4 "SportAdaptiveMode" 3 "SportMode" 2 "EconomyMode" 1 "NormalAdaptiveMode" 0 "NormalMode" ;
VAL_ 1239 CstmDrvMdeHmi2_D_Rq 31 "Faulty" 30 "SelDrvMde31" 29 "SelDrvMde30" 28 "SelDrvMde29" 27 "SelDrvMde28" 26 "SelDrvMde27" 25 "SelDrvMde26" 24 "SelDrvMde25" 23 "SelDrvMde24" 22 "SelDrvMde23" 21 "SelDrvMde22" 20 "SelDrvMde21" 19 "SelDrvMde20" 18 "SelDrvMde19" 17 "SelDrvMde18" 16 "SelDrvMde17" 15 "SelDrvMde16" 14 "SelDrvMde15" 13 "SelDrvMde14" 12 "SelDrvMde13" 11 "SelDrvMde12" 10 "SelDrvMde11" 9 "SelDrvMde10" 8 "SelDrvMde09" 7 "SelDrvMde08" 6 "SelDrvMde07" 5 "SelDrvMde06" 4 "SelDrvMde05" 3 "SelDrvMde04" 2 "SelDrvMde03" 1 "SelDrvMde02" 0 "SelDrvMde01" ;
VAL_ 1239 SelDrvMdeCstmLamp_D_Rq 3 "NotUsed2" 2 "NotUsed1" 1 "On" 0 "Off" ;
VAL_ 1239 SelDrvMdeCstm_D_RqDrv 7 "Faulty" 6 "NotUsed_3" 5 "NotUsed_2" 4 "NotUsed_1" 3 "Recall" 2 "Save" 1 "Activate" 0 "Null" ;
VAL_ 1239 StabBarCnnctLamp_D_Cstm 3 "Fast_Flash" 2 "Slow_Flash" 1 "On" 0 "Off" ;
VAL_ 1239 CstmDrvMdeMsgTxt_D_Rq 15 "Message15" 14 "Message14" 13 "Message13" 12 "Message12" 11 "Message11" 10 "Message10" 9 "Message9" 8 "Message8" 7 "Message7" 6 "Message6" 5 "Message5" 4 "Message4" 3 "Message3" 2 "Message2" 1 "Message1" 0 "NoMessage" ;
VAL_ 1239 ActvDrvMdeCstm_D2_Rq 31 "Faulty" 30 "SelDrvMde31" 29 "SelDrvMde30" 28 "SelDrvMde29" 27 "SelDrvMde28" 26 "SelDrvMde27" 25 "SelDrvMde26" 24 "SelDrvMde25" 23 "SelDrvMde24" 22 "SelDrvMde23" 21 "SelDrvMde22" 20 "SelDrvMde21" 19 "SelDrvMde20" 18 "SelDrvMde19" 17 "SelDrvMde18" 16 "SelDrvMde17" 15 "SelDrvMde16" 14 "SelDrvMde15" 13 "SelDrvMde14" 12 "SelDrvMde13" 11 "SelDrvMde12" 10 "SelDrvMde11" 9 "SelDrvMde10" 8 "SelDrvMde09" 7 "SelDrvMde08" 6 "SelDrvMde07" 5 "SelDrvMde06" 4 "SelDrvMde05" 3 "SelDrvMde04" 2 "SelDrvMde03" 1 "SelDrvMde02" 0 "SelDrvMde01" ;
VAL_ 949 Tire_Press_RR_ORR_Data 65535 "Not_Supported" 65534 "Invalid" 65533 "Unknown" ;
VAL_ 949 Tire_Press_LR_OLR_Data 65535 "Not_Supported" 65534 "Invalid" 65533 "Unknown" ;
VAL_ 949 Tire_Press_LF_Data 65535 "Not_Supported" 65534 "Invalid" 65533 "Unknown" ;
VAL_ 949 Tire_Press_RF_Data 65535 "Not_Supported" 65534 "Invalid" 65533 "Unknown" ;
VAL_ 639 OfbTrgtSocOvrrd_D_Rq 3 "NotUsed" 2 "Enable" 1 "Disable" 0 "Null" ;
VAL_ 639 OfbChrgPrflUpdate_B_Rq 1 "Request" 0 "NoRequest" ;
VAL_ 639 OfbChrgClearAll_B_Rq 1 "Request" 0 "NoRequest" ;
VAL_ 639 OfbChrgGoTTouch_D_Rq 3 "NotUsed" 2 "On" 1 "Off" 0 "Null" ;
VAL_ 639 OfbChrgGoTPrcond_D_Rq 3 "High" 2 "Medium" 1 "Low" 0 "Off" ;
VAL_ 639 OfbChrgGoTOn_D_Rq 3 "NotUsed" 2 "On" 1 "Off" 0 "Null" ;
VAL_ 639 OfbChrgGoTMnte_D_Rq 15 "NotUsed_4" 14 "NotUsed_3" 13 "NotUsed_2" 12 "NotUsed_1" 11 "Minute_55" 10 "Minute_50" 9 "Minute_45" 8 "Minute_40" 7 "Minute_35" 6 "Minute_30" 5 "Minute_25" 4 "Minute_20" 3 "Minute_15" 2 "Minute_10" 1 "Minute_5" 0 "Minute_0" ;
VAL_ 639 OfbChrgGoTHr_T_Rq 31 "Faulty" 30 "NoDataExists" ;
VAL_ 639 OfbChrgGoTExtHtr_D_Rq 3 "NotUsed" 2 "On" 1 "Off" 0 "Null" ;
VAL_ 639 OfbChrgGoTDelete_B_Rq 1 "Request" 0 "NoRequest" ;
VAL_ 639 OfbChrgGoTUpdate_B_Rq 1 "Request" 0 "NoRequest" ;
VAL_ 530 OfbChrgToPcWknd_D_Actl 7 "Percent_50" 6 "Percent_60" 5 "Percent_70" 4 "Percent_80" 3 "Percent_85" 2 "Percent_90" 1 "Percent_95" 0 "Percent_100" ;
VAL_ 530 OfbChrgToPcWkdy_D_Actl 7 "Percent_50" 6 "Percent_60" 5 "Percent_70" 4 "Percent_80" 3 "Percent_85" 2 "Percent_90" 1 "Percent_95" 0 "Percent_100" ;
VAL_ 530 OfbChrgSetNow_D_Rq 3 "NotUsed" 2 "On" 1 "Off" 0 "Null" ;
VAL_ 530 OfbChrgSetDelete_B_Rq 1 "Request" 0 "NoRequest" ;
VAL_ 530 OfbChrgLocIdUns_B_Rq 1 "Request" 0 "NoRequest" ;
VAL_ 550 PtWakeupActv1_B_Rq 1 "Wake_up_Powertrain_via_HW" 0 "Don_t_Wake_Up_Powertrain" ;
VAL_ 879 WndwRearHeat_I_Actl 2047 "Faulty" ;
VAL_ 879 WndwRearHeat_D_Stat 7 "NotUsed" 6 "FetLiftLimitReached" 5 "FetOpenCircuit" 4 "FetOutputShortToPower" 3 "FetOutputShortToGround" 2 "FetNotControlled" 1 "OnPowerToLoad" 0 "OffNoPowerToLoad" ;
VAL_ 885 BattULoChrg_D_RqOta 1 "Yes" 0 "No" ;
VAL_ 885 VehStrtInhbt_D_Dsply 15 "NotUsed_12" 14 "NotUsed_11" 13 "NotUsed_10" 12 "NotUsed_9" 11 "NotUsed_8" 10 "NotUsed_7" 9 "NotUsed_6" 8 "NotUsed_5" 7 "AutoInhibit" 6 "FleetPhoneNumber" 5 "FleetGeneral" 4 "OtaSuccess" 3 "PostOtaActivatePermFail" 2 "PostOtaActivateWarning" 1 "DuringOtaActivate" 0 "NoMessage" ;
VAL_ 885 VehOnRqstr_D_Stat 11 "NotUsed_8" 10 "NotUsed_7" 9 "NotUsed_6" 8 "NotUsed_5" 7 "NotUsed_4" 6 "NotUsed_3" 5 "NotUsed_2" 4 "NotUsed_1" 3 "FleetVehInhbt" 2 "StolenVehInhbt" 1 "OverTheAir" 0 "NoRequestor" 15 "NotUsed_12" 14 "NotUsed_11" 13 "NotUsed_10" 12 "NotUsed_9" ;
VAL_ 885 VehStrtInhbt_D_RqCld 3 "NotUsed" 2 "On" 1 "Off" 0 "Null" ;
VAL_ 885 VehOn_D_RqCld 3 "NoControl" 2 "On" 1 "Off" 0 "Null" ;
VAL_ 885 OtaActv_D_Stat 15 "NotUsed_10" 14 "NotUsed_9" 13 "NotUsed_8" 12 "NotUsed_7" 11 "NotUsed_6" 10 "NotUsed_5" 9 "NotUsed_4" 8 "NotUsed_3" 7 "NotUsed_2" 6 "NotUsed_1" 5 "NonInterruptible_Pending" 4 "NonInterruptible_Config" 3 "NonInterruptible_ER" 2 "NonInterruptible_AB" 1 "Interruptible_AB" 0 "NoInVehicleOta" ;
VAL_ 979 LatCtlRampType_D_Rq 3 "Immediately" 2 "Fast" 1 "Medium" 0 "Slow" ;
VAL_ 979 LatCtlPrecision_D_Rq 3 "NotUsed2" 2 "NotUsed1" 1 "Precise" 0 "Comfortable" ;
VAL_ 979 LatCtl_D_Rq 7 "NotUsed4" 6 "NotUsed3" 5 "NotUsed2" 4 "NotUsed1" 3 "InterventionRight" 2 "InterventionLeft" 1 "ContinuousPathFollowing" 0 "NoLateralControl" ;
VAL_ 979 HandsOffCnfm_B_Rq 1 "Active" 0 "Inactive" ;
VAL_ 739 BptMde_D_RqMnu 7 "NotUsed_4" 6 "NotUsed_3" 5 "NotUsed_2" 4 "NotUsed_1" 3 "Automatic" 2 "Manual" 1 "Off" 0 "Null" ;
VAL_ 739 SpeedChngChime_D_Rq 3 "NotUsed" 2 "On" 1 "Off" 0 "Null" ;
VAL_ 739 BptMnSoc_L_RqMnu 8191 "Faulty" 8190 "NoDataExists" ;
VAL_ 739 BptStrtStop_D_RqMnu 3 "NotUsed_1" 2 "Start" 1 "Stop" 0 "NoRequest" ;
VAL_ 739 OnbTrgtSocOvrrd_D_Rq 3 "NotUsed" 2 "Enable" 1 "Disable" 0 "Null" ;
VAL_ 739 BabySeatInUse_D_Stat 3 "NotUsed" 2 "InUse" 1 "NotInUse" 0 "Null" ;
VAL_ 739 VehHornOccAlrt_D_Stat 3 "NotUsed" 2 "On" 1 "Off" 0 "Null" ;
VAL_ 739 SeatOccChime_B_RqCancl 1 "Cancel" 0 "Null" ;
VAL_ 739 SeatOccRear_D_Stat 3 "NotUsed" 2 "On" 1 "Off" 0 "Null" ;
VAL_ 739 EngExhMdeHrStrt_D_Rq 31 "NotUsed_7" 30 "NotUsed_6" 29 "NotUsed_5" 28 "NotUsed_4" 27 "NotUsed_3" 26 "NotUsed_2" 25 "NotUsed_1" 24 "Hour23_11pm" 23 "Hour22_10pm" 22 "Hour21_9pm" 21 "Hour20_8pm" 20 "Hour19_7pm" 19 "Hour18_6pm" 18 "Hour17_5pm" 17 "Hour16_4pm" 16 "Hour15_3pm" 15 "Hour14_2pm" 14 "Hour13_1pm" 13 "Hour12_12pm" 12 "Hour11_11am" 11 "Hour10_10am" 10 "Hour9_9am" 9 "Hour8_8am" 8 "Hour7_7am" 7 "Hour6_6am" 6 "Hour5_5am" 5 "Hour4_4am" 4 "Hour3_3am" 3 "Hour2_2am" 2 "Hour1_1am" 1 "Hour0_12am" 0 "Null" ;
VAL_ 739 EngExhMdeHrEnd_D_Rq 31 "NotUsed_7" 30 "NotUsed_6" 29 "NotUsed_5" 28 "NotUsed_4" 27 "NotUsed_3" 26 "NotUsed_2" 25 "NotUsed_1" 24 "Hour23_11pm" 23 "Hour22_10pm" 22 "Hour21_9pm" 21 "Hour20_8pm" 20 "Hour19_7pm" 19 "Hour18_6pm" 18 "Hour17_5pm" 17 "Hour16_4pm" 16 "Hour15_3pm" 15 "Hour14_2pm" 14 "Hour13_1pm" 13 "Hour12_12pm" 12 "Hour11_11am" 11 "Hour10_10am" 10 "Hour9_9am" 9 "Hour8_8am" 8 "Hour7_7am" 7 "Hour6_6am" 6 "Hour5_5am" 5 "Hour4_4am" 4 "Hour3_3am" 3 "Hour2_2am" 2 "Hour1_1am" 1 "Hour0_12am" 0 "Null" ;
VAL_ 739 EngExhMdeHrEnbl_D_Rq 3 "NotConfigured" 2 "Enabled" 1 "Disabled" 0 "Null" ;
VAL_ 739 VgfSet_D_Stat 3 "NotUsed" 2 "On" 1 "Off" 0 "Null" ;
VAL_ 739 BptDly_T_RqMnu 63 "Faulty" 62 "NoDataExists" ;
VAL_ 739 Partial_Amp_Shutdown 1 "Active" 0 "Inactive" ;
VAL_ 739 HMI_HMIMode_St 7 "NotUsed2" 6 "NotUsed1" 5 "Load_Shed_Active" 0 "Invalid" 1 "OffMode" 2 "On" 3 "Phone" 4 "Climate" ;
VAL_ 1160 VgfZone_D_Stat 7 "Faulty" 6 "NotUsed_2" 5 "NotUsed_1" 4 "GPS_Unavailable" 3 "Restricted_Zone" 2 "Warning_Zone" 1 "Allowed_Zone" 0 "Off_Normal" ;
VAL_ 1160 HybMdeGzg_D_Rq 7 "NotUsed_2" 6 "NotUsed_1" 5 "EV_Override_Mode" 4 "EV_Charge_Mode" 3 "EV_Later_Mode" 2 "EV_Now_Mode" 1 "EV_Auto_Mode" 0 "Null" ;
VAL_ 1160 ReFuelSwtchStat_D_Actl2 3 "NotUsed_2" 2 "NotUsed_1" 1 "On" 0 "Off" ;
VAL_ 1160 DcacPwReset_B_RqCell 1 "Reset" 0 "Null" ;
VAL_ 1160 DcacPw_D_RqCell 3 "High" 2 "Low" 1 "Off" 0 "Null" ;
VAL_ 1160 DgtlCommPncReset_B_Req 1 "Yes" 0 "No" ;
VAL_ 1160 DgtlCommPnc_D_Rq 3 "DeleteAll" 2 "Disable" 1 "Reset" 0 "NoRequest" ;
VAL_ 1160 DataMntrSustn_B_Rq 1 "Active" 0 "Inactive" ;
VAL_ 1160 PwSustnRdata_B_RqTelem 1 "Active" 0 "Inactive" ;
VAL_ 1001 AirSuspMsgTxt_D_Rq2 3 "NotUsed" 2 "Faulty" 1 "Override" 0 "NoMessage" ;
VAL_ 1001 PersIndexSuma_D_Actl 7 "Unused_3" 6 "Unused_2" 5 "Unused_1" 4 "Vehicle" 3 "PERS_4" 2 "PERS_3" 1 "PERS_2" 0 "PERS_1" ;
VAL_ 1077 AirSuspLoading_D_Stat 7 "Faulty" 6 "MeasurementInProgress" 5 "Overload_2" 4 "Overload_1" 3 "FullyLoaded" 2 "MediumLoaded" 1 "LightLoaded" 0 "LoadNotDetermined" ;
VAL_ 1077 AirSprngRear_P_Actl 4095 "Faulty" ;
VAL_ 1077 AirSprngRear_M_Actl 4095 "Faulty" ;
VAL_ 1077 AirSprngFront_P_Actl 4095 "Faulty" ;
VAL_ 1077 AirSprngFront_M_Actl 4095 "Faulty" ;
VAL_ 945 PrkLckCtlMsgTxt_D2_Rq 7 "Message7" 6 "Message6" 5 "Message5" 4 "Message4" 3 "Message3" 2 "Message2" 1 "Message1" 0 "NoMessage" ;
VAL_ 945 KeyPadCodeDgt7_D_Dsply 15 "NotUsed_4" 14 "NotUsed_3" 13 "NotUsed_2" 12 "NotUsed_1" 11 "Button7_8and9_0" 10 "Button0" 9 "Button9_0or9" 8 "Button8" 7 "Button7_8or7" 6 "Button6" 5 "Button5_6or5" 4 "Button4" 3 "Button3_4or3" 2 "Button2" 1 "Button1_2or1" 0 "EndofString" ;
VAL_ 945 KeyPadCodeDgt6_D_Dsply 15 "NotUsed_4" 14 "NotUsed_3" 13 "NotUsed_2" 12 "NotUsed_1" 11 "Button7_8and9_0" 10 "Button0" 9 "Button9_0or9" 8 "Button8" 7 "Button7_8or7" 6 "Button6" 5 "Button5_6or5" 4 "Button4" 3 "Button3_4or3" 2 "Button2" 1 "Button1_2or1" 0 "EndofString" ;
VAL_ 945 KeyPadCodeDgt5_D_Dsply 15 "NotUsed_4" 14 "NotUsed_3" 13 "NotUsed_2" 12 "NotUsed_1" 11 "Button7_8and9_0" 10 "Button0" 9 "Button9_0or9" 8 "Button8" 7 "Button7_8or7" 6 "Button6" 5 "Button5_6or5" 4 "Button4" 3 "Button3_4or3" 2 "Button2" 1 "Button1_2or1" 0 "EndofString" ;
VAL_ 945 KeyPadCodeDgt4_D_Dsply 15 "NotUsed_4" 14 "NotUsed_3" 13 "NotUsed_2" 12 "NotUsed_1" 11 "Button7_8and9_0" 10 "Button0" 9 "Button9_0or9" 8 "Button8" 7 "Button7_8or7" 6 "Button6" 5 "Button5_6or5" 4 "Button4" 3 "Button3_4or3" 2 "Button2" 1 "Button1_2or1" 0 "EndofString" ;
VAL_ 945 KeyPadCodeDgt3_D_Dsply 15 "NotUsed_4" 14 "NotUsed_3" 13 "NotUsed_2" 12 "NotUsed_1" 11 "Button7_8and9_0" 10 "Button0" 9 "Button9_0or9" 8 "Button8" 7 "Button7_8or7" 6 "Button6" 5 "Button5_6or5" 4 "Button4" 3 "Button3_4or3" 2 "Button2" 1 "Button1_2or1" 0 "EndofString" ;
VAL_ 945 KeyPadCodeDgt2_D_Dsply 15 "NotUsed_4" 14 "NotUsed_3" 13 "NotUsed_2" 12 "NotUsed_1" 11 "Button7_8and9_0" 10 "Button0" 9 "Button9_0or9" 8 "Button8" 7 "Button7_8or7" 6 "Button6" 5 "Button5_6or5" 4 "Button4" 3 "Button3_4or3" 2 "Button2" 1 "Button1_2or1" 0 "EndofString" ;
VAL_ 945 KeyPadCodeDgt1_D_Dsply 15 "NotUsed_4" 14 "NotUsed_3" 13 "NotUsed_2" 12 "NotUsed_1" 11 "Button7_8and9_0" 10 "Button0" 9 "Button9_0or9" 8 "Button8" 7 "Button7_8or7" 6 "Button6" 5 "Button5_6or5" 4 "Button4" 3 "Button3_4or3" 2 "Button2" 1 "Button1_2or1" 0 "EndofString" ;
VAL_ 945 KeyOffMde_D_Actl 15 "NotUsed_11" 14 "NotUsed_10" 13 "NotUsed_9" 12 "NotUsed_8" 11 "NotUsed_7" 10 "NotUsed_6" 9 "NotUsed_5" 8 "NotUsed_4" 7 "NotUsed_3" 6 "NotUsed_2" 5 "NotUsed_1" 4 "CriticalBattery" 3 "Hibernate" 2 "Transport" 1 "Factory" 0 "Normal" ;
VAL_ 945 PrkLckCtlLatch_B_Rq 1 "On" 0 "Off" ;
VAL_ 771 ScDayOfWeekId_D_Stat 7 "Sunday" 6 "Saturday" 5 "Friday" 4 "Thursday" 3 "Wednesday" 2 "Tuesday" 1 "Monday" 0 "NotUsed" ;
VAL_ 771 ScChrgDurSet_B_Stat 1 "On" 0 "Off" ;
VAL_ 777 ScLocSaved_B_Dsply 1 "Yes" 0 "No" ;
VAL_ 777 ScLocLongPostv_B_Stat 1 "Yes" 0 "No" ;
VAL_ 777 ScLocLattPostv_B_Stat 1 "Yes" 0 "No" ;
VAL_ 1043 PrkBrkPerfMsgTxt_D_Rq 31 "Message31" 30 "Message30" 29 "Message29" 28 "Message28" 27 "Message27" 26 "Message26" 25 "Message25" 24 "Message24" 23 "Message23" 22 "Message22" 21 "Message21" 20 "Message20" 19 "Message19" 18 "Message18" 17 "Message17" 16 "Message16" 15 "Message15" 14 "Message14" 13 "Message13" 12 "Message12" 11 "Message11" 10 "Message10" 9 "Message9" 8 "Message8" 7 "Message7" 6 "Message6" 5 "Message5" 4 "Message4" 3 "Message3" 2 "Message2" 1 "Message1" 0 "NoMessage" ;
VAL_ 1043 PrkBrkPerfMde_D_Stat 3 "Faulty" 2 "NotUsed" 1 "On" 0 "Off" ;
VAL_ 1043 WhlSpareMsgTxt_D_Rq 3 "NotUsed" 2 "PleaseChangeYourSpareTire" 1 "DoNotDriveAbove80kph" 0 "NoMessage" ;
VAL_ 1043 WhlSpareDetct_D_Dsply 7 "NotUsed_2" 6 "NotUsed_1" 5 "DetectedAtVehicleRearRight" 4 "DetectedAtVehicleRearLeft" 3 "DetectedAtVehicleFrntRight" 2 "DetectedAtVehicleFrontLeft" 1 "Active" 0 "NotActive" ;
VAL_ 1043 PrkBrkPerfActv_B_Stat 1 "Active" 0 "Inactive" ;
VAL_ 1043 SelDrvMdeHmi02_D_Rq 31 "Faulty" 30 "SelDrvMde31" 29 "SelDrvMde30" 28 "SelDrvMde29" 27 "SelDrvMde28" 26 "SelDrvMde27" 25 "SelDrvMde26" 24 "SelDrvMde25" 23 "SelDrvMde24" 22 "SelDrvMde23" 21 "SelDrvMde22" 20 "SelDrvMde21" 19 "SelDrvMde20" 18 "SelDrvMde19" 17 "SelDrvMde18" 16 "SelDrvMde17" 15 "SelDrvMde16" 14 "SelDrvMde15" 13 "SelDrvMde14" 12 "SelDrvMde13" 11 "SelDrvMde12" 10 "SelDrvMde11" 9 "SelDrvMde10" 8 "SelDrvMde09" 7 "SelDrvMde08" 6 "SelDrvMde07" 5 "SelDrvMde06" 4 "SelDrvMde05" 3 "SelDrvMde04" 2 "SelDrvMde03" 1 "SelDrvMde02" 0 "SelDrvMde01" ;
VAL_ 1043 SelDrvMdeHmi04_D_Rq 31 "Faulty" 30 "SelDrvMde31" 29 "SelDrvMde30" 28 "SelDrvMde29" 27 "SelDrvMde28" 26 "SelDrvMde27" 25 "SelDrvMde26" 24 "SelDrvMde25" 23 "SelDrvMde24" 22 "SelDrvMde23" 21 "SelDrvMde22" 20 "SelDrvMde21" 19 "SelDrvMde20" 18 "SelDrvMde19" 17 "SelDrvMde18" 16 "SelDrvMde17" 15 "SelDrvMde16" 14 "SelDrvMde15" 13 "SelDrvMde14" 12 "SelDrvMde13" 11 "SelDrvMde12" 10 "SelDrvMde11" 9 "SelDrvMde10" 8 "SelDrvMde09" 7 "SelDrvMde08" 6 "SelDrvMde07" 5 "SelDrvMde06" 4 "SelDrvMde05" 3 "SelDrvMde04" 2 "SelDrvMde03" 1 "SelDrvMde02" 0 "SelDrvMde01" ;
VAL_ 1043 IndvMdeSel_D_Stat 3 "NotUsed" 2 "DriveModeChangeRequest" 1 "DriveModeChangeSelection" 0 "NoDriveModeChangeRequest" ;
VAL_ 1043 IndvMdeMsgTxt_D_Rq 15 "Message15" 14 "Message14" 13 "Message13" 12 "Message12" 11 "Message11" 10 "Message10" 9 "Message9" 8 "Message8" 7 "Message7" 6 "Message6" 5 "Message5" 4 "Message4" 3 "Message3" 2 "Message2" 1 "Message1" 0 "NoMessage" ;
VAL_ 1043 IndvMde5_B_Avail 1 "Available" 0 "NotAvailable" ;
VAL_ 1043 IndvMde4_B_Avail 1 "Available" 0 "NotAvailable" ;
VAL_ 1043 IndvMde3_B_Avail 1 "Available" 0 "NotAvailable" ;
VAL_ 1043 IndvMde2_B_Avail 1 "Available" 0 "NotAvailable" ;
VAL_ 1043 IndvMde1_B_Avail 1 "Available" 0 "NotAvailable" ;
VAL_ 1043 TrailOnePdlMde_D_Ind 7 "NotUsed_4" 6 "NotUsed_3" 5 "NotUsed_2" 4 "NotUsed_1" 3 "Standby" 2 "Active" 1 "Fault" 0 "Off" ;
VAL_ 1043 TrailOnePdlMsgTxt_D_Rq 7 "Message7" 6 "Message6" 5 "Message5" 4 "Message4" 3 "Message3" 2 "Message2" 1 "Message1" 0 "NoMessage" ;
VAL_ 1043 OrtaSwtchLamp_B_Rq 1 "On" 0 "Off" ;
VAL_ 1043 OrtaMsgTxt_D_Rq 15 "Message15" 14 "Message14" 13 "Message13" 12 "Message12" 11 "Message11" 10 "Message10" 9 "Message9" 8 "Message8" 7 "Message7" 6 "Message6" 5 "Message5" 4 "Message4" 3 "Message3" 2 "Message2" 1 "Message1" 0 "NoMessage" ;
VAL_ 1043 OrtaMde_D_Ind 7 "Faulty" 6 "NotUsed_2" 5 "NotUsed_1" 4 "ActiveRight" 3 "ActiveLeft" 2 "StandbyRight" 1 "StandbyLeft" 0 "Off" ;
VAL_ 991 PsngrLoad_D_Stat 3 "NotUsed_1" 2 "Accepted" 1 "NotAccepted" 0 "Inactive" ;
VAL_ 991 VehPayloadScrn_D_Stat 7 "CheckLoadScreenActive" 6 "WeightCarryScreenActive" 5 "GooseneckScreenActive" 4 "FifthWheelScreenActive" 3 "WeightDistScreenActive" 2 "AddMassEstScreenActive" 1 "PayloadEstScreenActive" 0 "ScaleScreenNotActive" ;
VAL_ 991 VehPayloadTireP_B_Stat 1 "Yes" 0 "No" ;
VAL_ 991 VehPayloadFlat_B_Stat 1 "Yes" 0 "No" ;
VAL_ 991 TrlrTngLoad_D_Stat 7 "Faulty" 6 "NoDataExists" 5 "NotUsed_3" 4 "NotUsed_2" 3 "NotUsed_1" 2 "AboveRange" 1 "InRange" 0 "BelowRange" ;
VAL_ 991 VehPayloadStew_B_Stat 1 "Yes" 0 "No" ;
VAL_ 991 VehPayloadTare_D_Stat 3 "Faulty" 2 "NotUsed" 1 "Request" 0 "NoRequest" ;
VAL_ 991 VehPayloadGear_B_Stat 1 "Yes" 0 "No" ;
VAL_ 991 VehFalr_D_Stat 7 "Faulty" 6 "NotUsed_3" 5 "NotUsed_2" 4 "NotUsed_1" 3 "HeightCorrectionCompleted" 2 "SecondMeasurementCollected" 1 "FirstMeasurementCollected" 0 "NotActive" ;
VAL_ 991 Trlr_M_Actl 2047 "Faulty" 2046 "NoDataExists" ;
VAL_ 991 PersIndexVdm_D_Actl 7 "Unused_3" 6 "Unused_2" 5 "Unused_1" 4 "Vehicle" 3 "PERS_4" 2 "PERS_3" 1 "PERS_2" 0 "PERS_1" ;
VAL_ 395 SelDrvMdeCnfm_D_Stat 3 "NotUsed" 2 "Accepted" 1 "NotAccepted" 0 "Null" ;
VAL_ 395 HudMde_D_Rq 7 "NotUsed3" 6 "NotUsed2" 5 "NotUsed1" 4 "Manual" 3 "Drag" 2 "RoadCourse" 1 "Tach" 0 "Off" ;
VAL_ 395 HudLedMde_D_Rq 3 "Not_Used" 2 "Flash" 1 "On" 0 "Off" ;
VAL_ 395 HudLed9On_B_Rq 1 "On" 0 "Off" ;
VAL_ 395 HudLed8On_B_Rq 1 "On" 0 "Off" ;
VAL_ 395 HudLed7On_B_Rq 1 "On" 0 "Off" ;
VAL_ 395 HudLed6On_B_Rq 1 "On" 0 "Off" ;
VAL_ 395 HudLed5On_B_Rq 1 "On" 0 "Off" ;
VAL_ 395 HudLed4On_B_Rq 1 "On" 0 "Off" ;
VAL_ 395 HudLed3On_B_Rq 1 "On" 0 "Off" ;
VAL_ 395 HudLed2On_B_Rq 1 "On" 0 "Off" ;
VAL_ 395 HudLed1On_B_Rq 1 "On" 0 "Off" ;
VAL_ 395 HudLed18On_B_Rq 1 "On" 0 "Off" ;
VAL_ 395 HudLed17On_B_Rq 1 "On" 0 "Off" ;
VAL_ 395 HudLed16On_B_Rq 1 "On" 0 "Off" ;
VAL_ 395 HudLed15On_B_Rq 1 "On" 0 "Off" ;
VAL_ 395 HudLed14On_B_Rq 1 "On" 0 "Off" ;
VAL_ 395 HudLed13On_B_Rq 1 "On" 0 "Off" ;
VAL_ 395 HudLed12On_B_Rq 1 "On" 0 "Off" ;
VAL_ 395 HudLed11On_B_Rq 1 "On" 0 "Off" ;
VAL_ 395 HudLed10On_B_Rq 1 "On" 0 "Off" ;
VAL_ 515 PtIgnSwtch_D_Stat 3 "Faulty" 2 "No_Data_Exists" 1 "On" 0 "Off" ;
VAL_ 982 LatCtlRampType_D_Rq 3 "Immediately" 2 "Fast" 1 "Medium" 0 "Slow" ;
VAL_ 982 LatCtl_D2_Rq 7 "NotUsed_5" 6 "NotUsed_4" 5 "NotUsed_3" 4 "LaneChange" 3 "SafeRampOut" 2 "PathFollowingExtendedMode" 1 "PathFollowingLimitedMode" 0 "NoLateralControl" ;
VAL_ 982 LatCtlPrecision_D_Rq 3 "NotUsed2" 2 "NotUsed1" 1 "Precise" 0 "Comfortable" ;
VAL_ 982 HandsOffCnfm_B_Rq 1 "Active" 0 "Inactive" ;
VAL_ 1104 DrvEngageLevel_D_Stat 7 "Faulty" 6 "NotUsed_2" 5 "NotUsed_1" 4 "Disengaged" 3 "Distracted" 2 "Attentive" 1 "Invalid" 0 "NotDetermined" ;
VAL_ 1104 DrvImpLvlConfid_D_Stat 7 "Faulty" 6 "NotUsed" 5 "High" 4 "MediumHigh" 3 "Medium" 2 "LowMedium" 1 "Low" 0 "NotDetermined" ;
VAL_ 1104 DrvImpairLvl_D_Stat 15 "Faulty" 14 "NotUsed_5" 13 "NotUsed_4" 12 "NotUsed_3" 11 "NotUsed_2" 10 "NotUsed_1" 9 "Incapacitated" 8 "Asleep" 7 "Microsleep" 6 "MostDrowsy" 5 "Drowsy_4" 4 "Drowsy_3" 3 "Drowsy_2" 2 "LeastDrowsy" 1 "Alert" 0 "NotDetermined" ;
VAL_ 1104 DrvEngLvlConfid_D_Stat 7 "Faulty" 6 "NotUsed" 5 "High" 4 "MediumHigh" 3 "Medium" 2 "LowMedium" 1 "Low" 0 "NotDetermined" ;
VAL_ 1104 DrvCamPassIR_D_Stat 3 "Faulty" 2 "Blocked" 1 "Ok" 0 "TemporaryUnavailable" ;
VAL_ 1104 DrvCamera_D_Stat 3 "Faulty" 2 "Blocked" 1 "Ok" 0 "TemporaryUnavailable" ;
VAL_ 1104 DrvCamDrvIR_D_Stat 3 "Faulty" 2 "Blocked" 1 "Ok" 0 "TemporaryUnavailable" ;
VAL_ 1104 DrvAttentZone_D_Stat 15 "Faulty" 14 "HeadsDisplay" 13 "EyesClosed" 12 "PassengerWindshield" 11 "NotConfigured" 10 "DriverLap" 9 "PassengerSideWindow" 8 "DriverSideWindow" 7 "DriverSideMirror" 6 "RearviewMirror" 5 "PassengerSideMirror" 4 "Infotainment" 3 "Cluster" 2 "FrontWindshield" 1 "Other" 0 "NotDetermined" ;
VAL_ 1104 DrvAlertSt_D_Stat 3 "Faulty" 2 "EyesOffRoad" 1 "EyesOnRoad" 0 "NotDetermined" ;
VAL_ 829 PwSrcULoMde2_D_Actl 3 "BuckSpecial" 2 "ReverseBoost" 1 "ForwardBuck" 0 "Standby" ;
VAL_ 829 DcdcUHi3_I_Actl 2047 "Faulty" 2046 "NoDataExists" ;
VAL_ 1089 Mtr2Aout_W_ActlMntr 1023 "Faulty" ;
VAL_ 1089 Inv1_Te_Actl 255 "Faulty" 254 "NoDataExists" ;
VAL_ 1089 MtrTrac2Coil_Te_Actl 255 "Faulty" 254 "NoDataExists" ;
VAL_ 1089 MtrTrac2Falt_B_Stat 1 "Active" 0 "Inactive" ;
VAL_ 1089 MtrTrac2TeAlrm_B_Stat 1 "Active" 0 "Inactive" ;
VAL_ 1089 Mtr2CntlTeAlrm_B_Stat 1 "Active" 0 "Inactive" ;
VAL_ 1089 MtrTrac2Inv_Te_Actl 255 "Faulty" 254 "NoDataExists" ;
VAL_ 1089 MtrTrac2_I_Actl 65535 "Faulty" ;
VAL_ 776 ScChrgrPwMax_Pw_RqCld 4095 "Faulty" ;
VAL_ 776 PrcondEdit_D_RqCld 7 "NotUsed_3" 6 "NotUsed_2" 5 "NotUsed_1" 4 "High" 3 "Medium" 2 "Low" 1 "Off" 0 "Null" ;
VAL_ 776 GoTEditMnte_T_RqCld 15 "Faulty" 14 "NoDataExists" 13 "NotUsed_2" 12 "NotUsed_1" 11 "Minute_55" 10 "Minute_50" 9 "Minute_45" 8 "Minute_40" 7 "Minute_35" 6 "Minute_30" 5 "Minute_25" 4 "Minute_20" 3 "Minute_15" 2 "Minute_10" 1 "Minute_5" 0 "Minute_0" ;
VAL_ 776 GoTEditHr_T_RqCld 31 "Faulty" 30 "NoDataExists" ;
VAL_ 776 ChrgToPcEdit_Pc_RqCld 127 "Faulty" 126 "NoDataExists" ;
VAL_ 776 ScFreshDataEnbl_B_Rq 1 "Yes" 0 "No" ;
VAL_ 776 ScEnbl_D_RqCld 3 "NotUsed" 2 "On" 1 "Off" 0 "Null" ;
VAL_ 1088 TrlrRng_L_Dsply 8191 "Faulty" 8190 "NoDataExists" ;
VAL_ 1088 ChrgStat_D2_Dsply 15 "ChargeStopCommanded" 14 "ChargeStartCommanded" 13 "ChargeTargetReached" 12 "DriveConditioning" 11 "CabinPreconditioning" 10 "ChargingSystemMaintain" 9 "ChargingInductive" 8 "ChargingDCFastCharge" 7 "ChargingAC" 6 "ChargeScheduled" 5 "EvsePaused" 4 "EvseNotDetected" 3 "EvseNotCompatible" 2 "FaultOutsideCar" 1 "FaultInsideCar" 0 "NotReady" ;
VAL_ 1088 ChrgTMatch_B_Stat 1 "True" 0 "False" ;
VAL_ 1088 HvacPrecondRecirc_D_Rq 3 "Last_User_Setting" 2 "Auto" 1 "Recirc" 0 "Outside" ;
VAL_ 1088 HvacPrecondMode2_D_Rq 15 "NotUsed4" 14 "NotUsed3" 13 "NotUsed2" 12 "Low_Blower_Auto" 11 "Last_User_Settings" 10 "Auto" 9 "Max_Defrost" 8 "Windshield_Panel_Floor" 7 "Windshield_Panel" 6 "Windshield" 5 "Windshield_Floor" 4 "Floor" 3 "Panel_Floor" 2 "Panel" 1 "MAX_AC" 0 "Off" ;
VAL_ 1088 HvacPrecondBlwr2_D_Rq 15 "NotUsed6" 14 "NotUsed5" 13 "NotUsed4" 12 "NotUsed3" 11 "NotUsed2" 10 "NotUsed1" 9 "Last_User_Setting" 8 "Auto" 7 "Speed7" 6 "Speed6" 5 "Speed5" 4 "Speed4" 3 "Speed3" 2 "Speed2" 1 "Speed1" 0 "Off" ;
VAL_ 1088 HvacPrecondAC_D_Rq 3 "Last_User_Setting" 2 "Auto" 1 "On" 0 "Off" ;
VAL_ 1088 BattChrgInhbt_D_Rq 3 "MaintainTargetSoc" 2 "NotUsed" 1 "InhibitChargingThermal" 0 "Enable_Charging" ;
VAL_ 1088 BattDcChrgRms_I_Lim 32767 "Faulty" 32766 "NoDataExists" ;
VAL_ 850 VehElRngeNut_L2_Dsply 8191 "Faulty" 8190 "NoDataExists" ;
VAL_ 850 VehElRngeNut_L_Dsply 4095 "Faulty" 4094 "NoDataExists" ;
VAL_ 850 NxtUsgSocEst_Pc_Dsply 255 "Faulty" 254 "NoDataExists" ;
VAL_ 850 EstmChrgTimeLP_St 255 "Invalid" ;
VAL_ 850 EstmChrgTimeHP_St 255 "Invalid" ;
VAL_ 850 ChargeNowDuration_St 255 "Invalid" ;
VAL_ 1070 BattULo24_Te_Actl 127 "Fault" ;
VAL_ 1070 BattULo24State_D_Qlty 3 "OK" 2 "Not_Within_Spec" 1 "Eval_In_Progress" 0 "Faulty" ;
VAL_ 1070 BattULo24_I_Actl 16383 "Faulty" ;
VAL_ 1070 BattULo24_B_Falt 1 "Yes" 0 "No" ;
VAL_ 1070 BattULo24_D_Falt 3 "NotUsed" 2 "TemporaryFault" 1 "Fault" 0 "NoFault" ;
VAL_ 1153 TerrStat_D_RqDsply 15 "Reserved4" 14 "Reserved3" 13 "Reserved2" 12 "Crawl_Mode_4LOW_Reqd" 11 "Economy_Mode_Select" 10 "ModeChangeNotAvailable" 9 "Terrain_Sys_Not_Avail" 8 "Terrain_System_Fault" 7 "Mode_Change_InProgress" 6 "Dynamics_Mode_Select" 5 "Rock_Crawl_Mode_Select" 4 "Sand_Mode_Select" 3 "Mud_Ruts_Mode_Select" 2 "Low_Mu_Mode_Select" 1 "Special_Modes_Off" 0 "No_Message" ;
VAL_ 1153 TerrMde_D_RqDrv 7 "Fail_Safe_Default" 6 "Dynamic_Mode" 5 "Rock_Crawl_Mode" 4 "Mud_Ruts_Mode" 3 "Sand_Mode" 2 "Undefined" 1 "Low_Mu_Mode" 0 "Special_Operating_Mode_Off" ;
VAL_ 868 BattRgenLoStat_D_Qlty 3 "OK" 2 "Not_Within_Spec" 1 "Eval_In_Progress" 0 "Faulty" ;
VAL_ 868 BattRgenLoPrtct_B_Stat 1 "Yes" 0 "No" ;
VAL_ 868 BattRgenLoDChrg_D_Stat 3 "StuckClosed" 2 "StuckOpen" 1 "Closed" 0 "Open" ;
VAL_ 868 BattRgenLoDchrg_B_Rq 1 "Yes" 0 "No" ;
VAL_ 868 BattRgenLoChrg_D_Stat 3 "StuckClosed" 2 "StuckOpen" 1 "Closed" 0 "Open" ;
VAL_ 868 BattRgenLoChrg_B_Rq 1 "Yes" 0 "No" ;
VAL_ 868 BattRgenLo_B_Falt 1 "Yes" 0 "No" ;
VAL_ 981 AdbBrdrTop_An_Rq 255 "Faulty" 254 "NoDataExists" ;
VAL_ 981 AdbBrdrRight_L_Stat 511 "Faulty" 510 "NoDataExists" ;
VAL_ 981 AdbBrdrRight_An_Rq 1023 "Faulty" 1022 "NoDataExists" ;
VAL_ 981 AdbBrdrLeft_L_Stat 511 "Faulty" 510 "NoDataExists" ;
VAL_ 981 AdbBrdrLeft_An_Rq 1023 "Faulty" 1022 "NoDataExists" ;
VAL_ 981 AdbBrdrBottom_An_Rq 63 "Faulty" 62 "NoDataExists" ;
VAL_ 981 AdbBeam_D_Rq 7 "NotUsed_3" 6 "NotUsed_2" 5 "NotUsed_1" 4 "FullHighBeam" 3 "Spot_BothSide" 2 "Spot_OnlyRightSide" 1 "Spot_OnlyLeftSide" 0 "NoHighBeam" ;
VAL_ 810 VehHorn_B_RqOccAlrt 1 "On" 0 "Off" ;
VAL_ 810 RmtViewMde_B_Rq 1 "On" 0 "Off" ;
VAL_ 810 DteCldAcceptData_B_Rq 1 "Yes" 0 "No" ;
VAL_ 810 DteCldCnclRoute_B_Rq 1 "Yes" 0 "No" ;
VAL_ 810 PtRmtRprt_D_Stat 15 "NotUsed_4" 14 "NotUsed_3" 13 "NotUsed_2" 12 "PlugInToMaintain12vBattery" 11 "SettingUpdated" 10 "FastChargeComplete" 9 "ChargeNotOccurring" 8 "OneTimeSocReached" 7 "BatteryTemperatureRemind" 6 "ReducedPerformance" 5 "LimitedPerformance" 4 "ChargeFault" 3 "ChargeComplete" 2 "VehiclePreconditioned" 1 "TripDistanceAchieved" 0 "NoReportRequest" ;
VAL_ 810 ChrgrPncEnbl_D_Rq 3 "NotUsed" 2 "Enable" 1 "Disable" 0 "Null" ;
VAL_ 810 OneTEditActv_B_RqCld 1 "Yes" 0 "No" ;
VAL_ 810 OBCCSerial_D_Rq 3 "PresentAndProvisioned" 2 "PresentAndProvAlertAck" 1 "PresentAndUnprovisioned" 0 "NotPresent" ;
VAL_ 810 ExtLghtDsply_B_StatArb 1 "On" 0 "Off" ;
VAL_ 810 ExtLghtRight_D_RqOta 7 "NotUsed" 6 "PressToOn3" 5 "PressToOff3" 4 "PressToOn2" 3 "PressToOff2" 2 "PressToOn1" 1 "PressToOff1" 0 "Reset" ;
VAL_ 810 ExtLghtRear_D_RqOta 7 "NotUsed" 6 "PressToOn3" 5 "PressToOff3" 4 "PressToOn2" 3 "PressToOff2" 2 "PressToOn1" 1 "PressToOff1" 0 "Reset" ;
VAL_ 810 ExtLghtLeft_D_RqOta 7 "NotUsed" 6 "PressToOn3" 5 "PressToOff3" 4 "PressToOn2" 3 "PressToOff2" 2 "PressToOn1" 1 "PressToOff1" 0 "Reset" ;
VAL_ 810 ExtLghtFront_D_RqOta 7 "NotUsed" 6 "PressToOn3" 5 "PressToOff3" 4 "PressToOn2" 3 "PressToOff2" 2 "PressToOn1" 1 "PressToOff1" 0 "Reset" ;
VAL_ 810 TlghtTest_D_RqArb 3 "TestEndAcknowledge" 2 "StartTest" 1 "StopTest" 0 "Null" ;
VAL_ 810 ChrgrPncSustn_B_Rq 1 "Active" 0 "Inactive" ;
VAL_ 563 BattChrgStrtStop_D2_Rq 15 "NotUsed_8" 14 "NotUsed_7" 13 "NotUsed_6" 12 "NotUsed_5" 11 "NotUsed_4" 10 "NotUsed_3" 9 "NotUsed_2" 8 "NotUsed_1" 7 "GridStopChargingPartial" 6 "GridStopChargingMandatory" 5 "GridStartChargingFree" 4 "GridStartChargingPreferred" 3 "ReturnToSettings" 2 "StopCharge" 1 "StartCharge" 0 "NoNewRequest" ;
VAL_ 563 DrvBhavAudioAlrt_D_Rq 58 "NotUsed_51" 57 "NotUsed_50" 56 "NotUsed_49" 55 "NotUsed_48" 54 "NotUsed_47" 53 "NotUsed_46" 52 "NotUsed_45" 25 "NotUsed_18" 24 "NotUsed_17" 23 "NotUsed_16" 22 "NotUsed_15" 21 "NotUsed_14" 20 "NotUsed_13" 19 "NotUsed_12" 18 "NotUsed_11" 17 "NotUsed_10" 16 "NotUsed_9" 15 "NotUsed_8" 14 "NotUsed_7" 13 "NotUsed_6" 12 "NotUsed_5" 11 "NotUsed_4" 10 "NotUsed_3" 9 "NotUsed_2" 8 "NotUsed_1" 7 "ExcessiveIdleAndUnbuckled" 6 "ExcessiveSpeedAndUnbuckled" 5 "SeatbeltUnbuckled" 4 "HardBrakingBegin" 3 "HardAccelerationBegin" 2 "ExcessiveSpeedBegin" 1 "ExcessiveIdleBegin" 0 "NoMessage" 63 "NotUsed_56" 62 "NotUsed_55" 61 "NotUsed_54" 60 "NotUsed_53" 59 "NotUsed_52" ;
VAL_ 563 NtfyDrvTrgtDist_L2_Rq 8191 "Faulty" 8190 "NoDataExists" ;
VAL_ 563 BattChrgStrtStop_D_Rq 3 "ReturnToSettings" 2 "StopCharge" 1 "StartCharge" 0 "NoNewRequest" ;
VAL_ 563 DrvBhavWarn_B_Rq 1 "On" 0 "Off" ;
VAL_ 563 OfbChrgSetSync_D_Rq 3 "Fail" 2 "Success" 1 "InProgress" 0 "NoSyncInProgress" ;
VAL_ 563 KeyOffPwMde_D_Stat 7 "NotUsed_6" 6 "NotUsed_5" 5 "NotUsed_4" 4 "NotUsed_3" 0 "Inactive" 1 "On" 2 "NotUsed_1" 3 "NotUsed_2" ;
VAL_ 563 ModemReset_D_Stat 15 "NotUsed_10" 14 "NotUsed_9" 13 "NotUsed_8" 12 "NotUsed_7" 11 "NotUsed_6" 10 "NotUsed_5" 9 "NotUsed_4" 8 "NotUsed_3" 7 "NotUsed_2" 6 "NotUsed_1" 5 "WifiHotSpotResetComplete" 4 "CcsResetComplete" 3 "OnlineTrafficResetComplete" 2 "PaakResetComplete" 1 "ResetNotComplete" 0 "Null" ;
VAL_ 563 FactoryReset_St 3 "NotUsed_2" 2 "NotUsed_1" 1 "FactoryDefaultsRestored" 0 "Null" ;
SIG_GROUP_ 885 Profile1A_SigGroup_FD1_375 1 : BattULoChrg_D_RqOta VehStrtInhbt_T_Dsply VehStrtInhbt_D_Dsply OtaActv_D_Stat VehOn_D_RqCld VehOnRqstr_D_Stat VehStrtInhbt_D_RqCld CanMsg375_No_Cnt CanMsg375_No_Crc;
